VERSION ""

NS_ :

BS_:

BU_: VT TECU TC Sprayer GPS AuxInput

BO_ 2633895166 WSMEM: 8 Vector__XXX
 SG_ ArbitraryAddressCapable : 63|1@1+ (1,0) [0|1] "" Vector__XXX
 SG_ ECUInstance : 32|3@1+ (1,0) [0|7] "" Vector__XXX
 SG_ Function : 40|8@1+ (1,0) [0|255] "" Vector__XXX
 SG_ FunctionInstance : 35|5@1+ (1,0) [0|31] "" Vector__XXX
 SG_ IdentityNumber : 0|21@1+ (1,0) [0|2097152] "" Vector__XXX
 SG_ IndustryGroup M : 60|3@1+ (1,0) [0|7] "" Vector__XXX
 SG_ ManufacturerCode : 21|11@1+ (1,0) [0|2047] "" Vector__XXX
 SG_ VehicleSystem m0 : 49|7@1+ (1,0) [0|127] "" Vector__XXX
 SG_ VehicleSystem1 m1 : 49|7@1+ (1,0) [0|127] "" Vector__XXX
 SG_ VehicleSystem2 m2 : 49|7@1+ (1,0) [0|127] "" Vector__XXX
 SG_ VehicleSystem3 m3 : 49|7@1+ (1,0) [0|127] "" Vector__XXX
 SG_ VehicleSystem4 m4 : 49|7@1+ (1,0) [0|127] "" Vector__XXX
 SG_ VehicleSystem5 m5 : 49|7@1+ (1,0) [0|127] "" Vector__XXX
 SG_ VehicleSystemInstance m0 : 56|4@1+ (1,0) [0|15] "" Vector__XXX

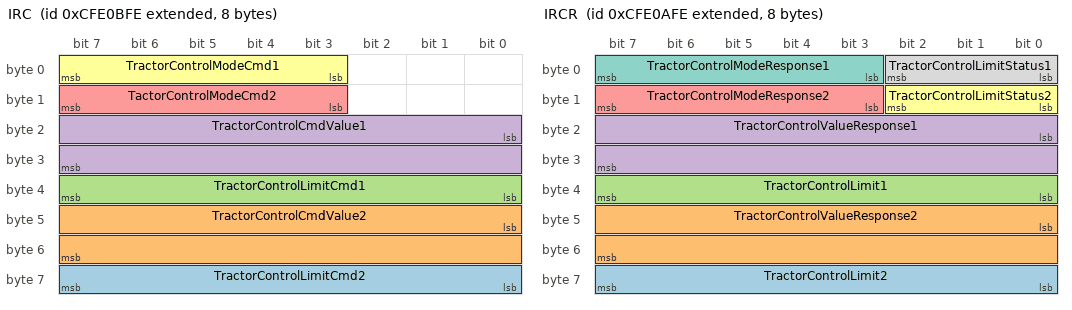
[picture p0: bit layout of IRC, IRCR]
BO_ 2365459454 IRC: 8 Vector__XXX
 SG_ TractorControlLimitCmd2 : 56|8@1- (1,0) [0|0] "" Vector__XXX
 SG_ TractorControlCmdValue2 : 40|16@1+ (1,0) [0|0] "" Vector__XXX
 SG_ TractorControlLimitCmd1 : 32|8@1- (1,0) [0|0] "" Vector__XXX
 SG_ TractorControlCmdValue1 : 16|16@1+ (1,0) [0|0] "" Vector__XXX
 SG_ TactorControlModeCmd2 : 11|5@1+ (1,0) [0|31] "" Vector__XXX
 SG_ TractorControlModeCmd1 : 3|5@1+ (1,0) [0|31] "" Vector__XXX

BO_ 2365459198 IRCR: 8 Vector__XXX
 SG_ TractorControlLimit2 : 56|8@1- (1,0) [0|0] "" Vector__XXX
 SG_ TractorControlValueResponse2 : 40|16@1+ (1,0) [0|0] "" Vector__XXX
 SG_ TractorControlLimit1 : 32|8@1- (1,0) [0|0] "" Vector__XXX
 SG_ TractorControlValueResponse1 : 16|16@1+ (1,0) [0|0] "" Vector__XXX
 SG_ TractorControlModeResponse2 : 11|5@1+ (1,0) [0|31] "" Vector__XXX
 SG_ TractorControlLimitStatus2 : 8|3@1+ (1,0) [0|7] "" Vector__XXX
 SG_ TractorControlModeResponse1 : 3|5@1+ (1,0) [0|31] "" Vector__XXX
 SG_ TractorControlLimitStatus1 : 0|3@1+ (1,0) [0|7] "" Vector__XXX

BO_ 2365458942 TFR: 8 Vector__XXX
 SG_ OperatorExtLightControls : 35|1@1+ (1,0) [0|0] "" Vector__XXX
 SG_ MachineSelectedSpeed : 34|1@1+ (1,0) [0|0] "" Vector__XXX
 SG_ MachineSelectedSpeedControl : 33|1@1+ (1,0) [0|0] "" Vector__XXX
 SG_ DirectionControl : 32|1@1+ (1,0) [0|0] "" Vector__XXX
 SG_ DriveStrategyStatusAndCommands : 48|1@1- (1,0) [0|0] "" Vector__XXX
 SG_ ExtGuidanceStatusAndCmd : 49|1@1- (1,0) [0|0] "" Vector__XXX
 SG_ PTOCmd_FrontPTOModeGearCmd : 55|1@1- (1,0) [0|0] "" Vector__XXX
 SG_ PTOCmd_RearPTOModeGearCmd : 26|1@1- (1,0) [0|0] "" Vector__XXX
 SG_ ReservedBitIndicator : 56|1@1- (1,0) [0|1] "" Vector__XXX
 SG_ HitchInfo_FrontPosition : 47|1@1+ (1,0) [0|1] "" Vector__XXX
 SG_ HitchInfo_FrontInWork : 46|1@1+ (1,0) [0|1] "" Vector__XXX
 SG_ PTOInfo_FrontShaftSpeed : 45|1@1+ (1,0) [0|1] "" Vector__XXX
 SG_ PTOInfo_FrontShaftEngagement : 44|1@1+ (1,0) [0|1] "" Vector__XXX
 SG_ AddHitchParameter__FrontDraft : 43|1@1+ (1,0) [0|1] "" Vector__XXX
 SG_ HitchCmd_FrontHitchPosition : 42|1@1+ (1,0) [0|1] "" Vector__XXX
 SG_ PTOCmd_FrontPTOSpeedCmd : 41|1@1+ (1,0) [0|1] "" Vector__XXX
 SG_ PTOCmd_FrontPTOEngagementCmd : 40|1@1+ (1,0) [0|1] "" Vector__XXX
 SG_ NavigSystemHighOutputPosition : 39|1@1+ (1,0) [0|1] "" Vector__XXX
 SG_ NavigSystemPositionData : 38|1@1+ (1,0) [0|1] "" Vector__XXX
 SG_ NavigPseudorangeNoiseStatistic : 37|1@1+ (1,0) [0|1] "" Vector__XXX
 SG_ HitchCmd_RearHitchPosition : 31|1@1+ (1,0) [0|1] "" Vector__XXX
 SG_ PTOCmd_RearPTOSpeedCmd : 30|1@1+ (1,0) [0|1] "" Vector__XXX
 SG_ PTOCmd_RearPTOEngagementCmd : 29|1@1+ (1,0) [0|1] "" Vector__XXX
 SG_ AuxiliaryValveCmd : 28|1@1+ (1,0) [0|1] "" Vector__XXX
 SG_ LimitStatusReporting : 27|1@1+ (1,0) [0|0] "" Vector__XXX
 SG_ TimeDate : 23|1@1+ (1,0) [0|1] "" Vector__XXX
 SG_ SpeedAndDist_GndBasedDistance : 22|1@1+ (1,0) [0|1] "" Vector__XXX
 SG_ SpeedAndDist_GndBasedDirection : 21|1@1+ (1,0) [0|1] "" Vector__XXX
 SG_ SpeedAndDist_WheelBasedDistance : 20|1@1+ (1,0) [0|1] "" Vector__XXX
 SG_ SpeedAndDist_WheelBasedDirection : 19|1@1+ (1,0) [0|1] "" Vector__XXX
 SG_ AddHitchParameter_RearDraft : 18|1@1+ (1,0) [0|1] "" Vector__XXX
 SG_ Light_FullImplLightingMessageSet : 17|1@1+ (1,0) [0|1] "" Vector__XXX
 SG_ EstimatedOrMeasuredAuxValveState : 16|1@1+ (1,0) [0|1] "" Vector__XXX
 SG_ HitchInfo_RearPosition : 15|1@1+ (1,0) [0|1] "" Vector__XXX
 SG_ HitchInfo_RearInWork : 14|1@1+ (1,0) [0|1] "" Vector__XXX
 SG_ PTOInfo_RearShaftSpeed : 13|1@1+ (1,0) [0|1] "" Vector__XXX
 SG_ PTOInfo_RearShaftEngagement : 12|1@1+ (1,0) [0|0] "" Vector__XXX
 SG_ Lighting_MinimalSet : 11|1@1+ (1,0) [0|1] "" Vector__XXX
 SG_ LanguageCmdStorageInTractorECU : 10|1@1+ (1,0) [0|1] "" Vector__XXX
 SG_ TractorClass : 6|2@1+ (1,0) [0|3] "" Vector__XXX
 SG_ PowerMgt_KeySwitch : 5|1@1+ (1,0) [0|1] "" Vector__XXX
 SG_ PowerMgt_MaxTimeTractorPower : 4|1@1+ (1,0) [0|1] "" Vector__XXX
 SG_ PowerMgt_MaintainPower : 3|1@1+ (1,0) [0|1] "" Vector__XXX
 SG_ SpeedInfo_WheelBasedSpeed : 2|1@1+ (1,0) [0|1] "" Vector__XXX
 SG_ SpeedInfo_GroundBasedSpeed : 1|1@1+ (1,0) [0|1] "" Vector__XXX
 SG_ SpeedInfo_EngineSpeed : 0|1@1+ (1,0) [0|1] "" Vector__XXX

BO_ 2365458686 RTF: 8 Vector__XXX
 SG_ DriveStrategyStatusAndCommands : 48|1@1- (1,0) [0|0] "" Vector__XXX
 SG_ ExtGuidanceStatusAndCmd : 49|1@1- (1,0) [0|0] "" Vector__XXX
 SG_ PTOCmd_FrontPTOModeGearCmd : 55|1@1- (1,0) [0|0] "" Vector__XXX
 SG_ PTOCmd_RearPTOModeGearCmd : 26|1@1- (1,0) [0|0] "" Vector__XXX
 SG_ ReservedBitIndicator : 56|1@1- (1,0) [0|1] "" Vector__XXX
 SG_ HitchInfo_FrontPosition : 47|1@1+ (1,0) [0|1] "" Vector__XXX
 SG_ HitchInfo_FrontInWork : 46|1@1+ (1,0) [0|1] "" Vector__XXX
 SG_ PTOInfo_FrontShaftSpeed : 45|1@1+ (1,0) [0|1] "" Vector__XXX
 SG_ PTOInfo_FrontShaftEngagement : 44|1@1+ (1,0) [0|1] "" Vector__XXX
 SG_ AddHitchParameter__FrontDraft : 43|1@1+ (1,0) [0|1] "" Vector__XXX
 SG_ HitchCmd_FrontHitchPosition : 42|1@1+ (1,0) [0|1] "" Vector__XXX
 SG_ PTOCmd_FrontPTOSpeedCmd : 41|1@1+ (1,0) [0|1] "" Vector__XXX
 SG_ PTOCmd_FrontPTOEngagementCmd : 40|1@1+ (1,0) [0|1] "" Vector__XXX
 SG_ NavigSystemHighOutputPosition : 39|1@1+ (1,0) [0|1] "" Vector__XXX
 SG_ NavigSystemPositionData : 38|1@1+ (1,0) [0|1] "" Vector__XXX
 SG_ NavigPseudorangeNoiseStatistic : 37|1@1+ (1,0) [0|1] "" Vector__XXX
 SG_ OperatorExternalLightControls : 35|1@1+ (1,0) [0|1] "" Vector__XXX
 SG_ SelectedMachineSpeed : 34|1@1+ (1,0) [0|1] "" Vector__XXX
 SG_ SelectedMachineSpeedControl : 33|1@1+ (1,0) [0|1] "" Vector__XXX
 SG_ DirectionControl : 32|1@1+ (1,0) [0|1] "" Vector__XXX
 SG_ HitchCmd_RearHitchPosition : 31|1@1+ (1,0) [0|1] "" Vector__XXX
 SG_ PTOCmd_RearPTOSpeedCmd : 30|1@1+ (1,0) [0|1] "" Vector__XXX
 SG_ PTOCmd_RearPTOEngagementCmd : 29|1@1+ (1,0) [0|1] "" Vector__XXX
 SG_ AuxiliaryValveCmd : 28|1@1+ (1,0) [0|1] "" Vector__XXX
 SG_ LimitStatusReporting : 27|1@1+ (1,0) [0|0] "" Vector__XXX
 SG_ TimeDate : 23|1@1+ (1,0) [0|1] "" Vector__XXX
 SG_ SpeedAndDist_GndBasedDistance : 22|1@1+ (1,0) [0|1] "" Vector__XXX
 SG_ SpeedAndDist_GndBasedDirection : 21|1@1+ (1,0) [0|1] "" Vector__XXX
 SG_ SpeedAndDist_WheelBasedDistance : 20|1@1+ (1,0) [0|1] "" Vector__XXX
 SG_ SpeedAndDist_WheelBasedDirection : 19|1@1+ (1,0) [0|1] "" Vector__XXX
 SG_ AddHitchParameter_RearDraft : 18|1@1+ (1,0) [0|1] "" Vector__XXX
 SG_ Light_FullImplLightingMessageSet : 17|1@1+ (1,0) [0|1] "" Vector__XXX
 SG_ EstimatedOrMeasuredAuxValveState : 16|1@1+ (1,0) [0|1] "" Vector__XXX
 SG_ HitchInfo_RearPosition : 15|1@1+ (1,0) [0|1] "" Vector__XXX
 SG_ HitchInfo_RearInWork : 14|1@1+ (1,0) [0|1] "" Vector__XXX
 SG_ PTOInfo_RearShaftSpeed : 13|1@1+ (1,0) [0|1] "" Vector__XXX
 SG_ PTOInfo_RearShaftEngagement : 12|1@1+ (1,0) [0|0] "" Vector__XXX
 SG_ Lighting_MinimalSet : 11|1@1+ (1,0) [0|1] "" Vector__XXX
 SG_ LanguageCmdStorageInTractorECU : 10|1@1+ (1,0) [0|1] "" Vector__XXX
 SG_ TractorClass : 6|2@1+ (1,0) [0|3] "" Vector__XXX
 SG_ PowerMgt_KeySwitch : 5|1@1+ (1,0) [0|1] "" Vector__XXX
 SG_ PowerMgt_MaxTimeTractorPower : 4|1@1+ (1,0) [0|1] "" Vector__XXX
 SG_ PowerMgt_MaintainPower : 3|1@1+ (1,0) [0|1] "" Vector__XXX
 SG_ SpeedInfo_WheelBasedSpeed : 2|1@1+ (1,0) [0|1] "" Vector__XXX
 SG_ SpeedInfo_GroundBasedSpeed : 1|1@1+ (1,0) [0|1] "" Vector__XXX
 SG_ SpeedInfo_EngineSpeed : 0|1@1+ (1,0) [0|1] "" Vector__XXX

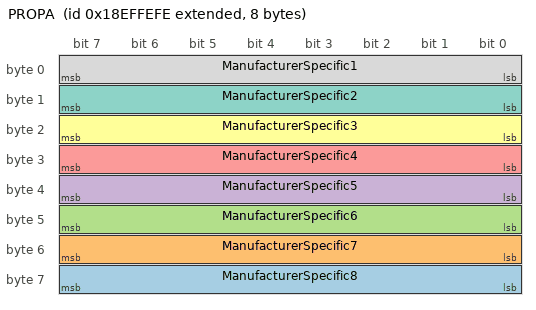
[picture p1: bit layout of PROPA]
BO_ 2565865214 PROPA: 8 Vector__XXX
 SG_ ManufacturerSpecific8 : 56|8@1+ (1,0) [0|255] "" Vector__XXX
 SG_ ManufacturerSpecific7 : 48|8@1+ (1,0) [0|255] "" Vector__XXX
 SG_ ManufacturerSpecific6 : 40|8@1+ (1,0) [0|255] "" Vector__XXX
 SG_ ManufacturerSpecific5 : 32|8@1+ (1,0) [0|255] "" Vector__XXX
 SG_ ManufacturerSpecific4 : 24|8@1+ (1,0) [0|255] "" Vector__XXX
 SG_ ManufacturerSpecific3 : 16|8@1+ (1,0) [0|255] "" Vector__XXX
 SG_ ManufacturerSpecific2 : 8|8@1+ (1,0) [0|255] "" Vector__XXX
 SG_ ManufacturerSpecific1 : 0|8@1+ (1,0) [0|255] "" Vector__XXX

BO_ 2632777470 TPCM: 8 Vector__XXX
 SG_ PGNumber : 40|24@1+ (1,0) [0|16777200] "" Vector__XXX
 SG_ MaximumNumberOfPackets m16 : 32|8@1+ (1,0) [0|255] "" Vector__XXX
 SG_ TotalNumberOfPackets m16 : 24|8@1+ (1,0) [0|255] "" Vector__XXX
 SG_ TotalNumberOfPacketsBAM m32 : 24|8@1+ (1,0) [0|255] "" Vector__XXX
 SG_ TotalNumberOfPacketsEoMA m19 : 24|8@1+ (1,0) [0|255] "" Vector__XXX
 SG_ NextPacketNumberToBeSent m17 : 16|8@1+ (1,0) [0|255] "" Vector__XXX
 SG_ ConnectionAbortReason m255 : 8|8@1+ (1,0) [0|255] "" Vector__XXX
 SG_ NumberOfPacketsThatCanBeSent m17 : 8|8@1+ (1,0) [0|255] "" Vector__XXX
 SG_ TotalMessageSize m16 : 8|16@1+ (1,0) [0|64255] "counts" Vector__XXX
 SG_ TotalMessageSizeBAM m32 : 8|16@1+ (1,0) [0|64255] "counts" Vector__XXX
 SG_ TotalMessageSizeEoMA m19 : 8|16@1+ (1,0) [0|64255] "counts" Vector__XXX
 SG_ ControlByte M : 0|8@1+ (1,0) [0|255] "" Vector__XXX

BO_ 2632711934 TPDT: 8 Vector__XXX
 SG_ SequenceNumber : 0|8@1+ (1,0) [0|255] "" Vector__XXX

BO_ 2565537534 RQST: 3 Vector__XXX
 SG_ ParameterGroupNumber : 0|24@1+ (1,0) [0|16777215] "" Vector__XXX

BO_ 2565406462 ACKM: 8 Vector__XXX
 SG_ ParameterGroupNumber : 40|24@1+ (1,0) [0|16777215] "" Vector__XXX
 SG_ AddressBusy m3 : 32|8@1+ (1,0) [0|255] "" Vector__XXX
 SG_ AddressAccessDenied m2 : 32|8@1+ (1,0) [0|255] "" Vector__XXX
 SG_ AddressNegativeAcknowledgement m1 : 32|8@1+ (1,0) [0|255] "" Vector__XXX
 SG_ AddressAcknowledged m0 : 32|8@1+ (1,0) [0|255] "" Vector__XXX
 SG_ GroupFunctionValue : 8|8@1+ (1,0) [0|255] "" Vector__XXX
 SG_ ControlByte M : 0|8@1+ (1,0) [0|255] "" Vector__XXX

BO_ 2498232062 VT21: 33 Vector__XXX
 SG_ AudioWasTerminated m10 : 8|1@1+ (1,0) [0|0] "" Vector__XXX
 SG_ VTControlAudioSigTerminationTAN m10 : 20|4@1+ (1,0) [0|0] "" Vector__XXX
 SG_ VTSelectInputObjectIsEdited m3 : 32|1@1+ (1,0) [0|1] "" Vector__XXX
 SG_ ParentMaskObjectID m2 : 48|16@1+ (1,0) [0|0] "" Vector__XXX
 SG_ OperatingState4 m38 : 59|1@1+ (1,0) [0|1] "" Vector__XXX
 SG_ OperatingState3 m38 : 58|1@1+ (1,0) [0|1] "" Vector__XXX
 SG_ VTSelectInputObjectResponseTAN m3 : 60|4@1+ (1,0) [0|15] "" Vector__XXX
 SG_ VTOnUserLayoutHideShowRespTAN m9 : 60|4@1+ (1,0) [0|15] "" Vector__XXX
 SG_ VTESCResponseTAN m4 : 60|4@1+ (1,0) [0|15] "" Vector__XXX
 SG_ VTChangeNumericValueResponseTAN m5 : 28|4@1+ (1,0) [0|15] "" Vector__XXX
 SG_ SoftKeyActivationResponseTAN m0 : 60|4@1+ (1,0) [0|15] "" Vector__XXX
 SG_ PointingEventResponseTAN m2 : 44|4@1+ (1,0) [0|15] "" Vector__XXX
 SG_ ButtonActivationResponseTAN m1 : 60|4@1+ (1,0) [0|15] "" Vector__XXX
 SG_ WSVehicleSystemInstance m144 : 64|4@1+ (1,0) [0|15] "" Vector__XXX
 SG_ WSVehicleSystem5 m5 : 57|7@1+ (1,0) [0|127] "" Vector__XXX
 SG_ WSVehicleSystem4 m4 : 57|7@1+ (1,0) [0|127] "" Vector__XXX
 SG_ WSVehicleSystem3 m3 : 57|7@1+ (1,0) [0|127] "" Vector__XXX
 SG_ WSVehicleSystem2 m2 : 57|7@1+ (1,0) [0|127] "" Vector__XXX
 SG_ WSVehicleSystem1 m1 : 57|7@1+ (1,0) [0|127] "" Vector__XXX
 SG_ WSVehicleSystem m0 : 57|7@1+ (1,0) [0|127] "" Vector__XXX
 SG_ WSManufacturerCode m144 : 29|11@1+ (1,0) [0|2047] "" Vector__XXX
 SG_ WSIndustryGroup m144M : 68|3@1+ (1,0) [0|7] "" Vector__XXX
 SG_ WSIdentityNumber m144 : 8|21@1+ (1,0) [0|2097152] "" Vector__XXX
 SG_ WSFunctionInstance m144 : 43|5@1+ (1,0) [0|31] "" Vector__XXX
 SG_ WSFunction m144 : 48|8@1+ (1,0) [0|255] "" Vector__XXX
 SG_ WSECUInstance m144 : 40|3@1+ (1,0) [0|7] "" Vector__XXX
 SG_ WSArbitraryAddressCapable m144 : 71|1@1+ (1,0) [0|1] "" Vector__XXX
 SG_ PathRequested m198 : 16|8@1+ (1,0) [0|255] "" Vector__XXX
 SG_ ItemRequested m198 : 8|8@1+ (1,0) [0|255] "" Vector__XXX
 SG_ Status_3 m35 : 24|8@1+ (1,0) [0|0] "" Vector__XXX
 SG_ UnsupportedVtFunction m253 : 8|8@1+ (1,0) [0|255] "" Vector__XXX
 SG_ AuxiliaryInputID_1 m34 : 120|16@1+ (1,0) [0|65535] "" Vector__XXX
 SG_ AuxiliaryFunctionID_1 m34 : 104|16@1+ (1,0) [0|65535] "" Vector__XXX
 SG_ NumOfPreferredFunctions m34 : 96|8@1- (1,0) [0|255] "" Vector__XXX
 SG_ ModelIdentificationCode m34 : 80|16@1+ (1,0) [0|65535] "" Vector__XXX
 SG_ ArbitraryAddressCapable m34 : 79|1@1+ (1,0) [0|1] "" Vector__XXX
 SG_ IndustryGroup m34 : 76|3@1+ (1,0) [0|7] "" Vector__XXX
 SG_ VehicleSystemInstance m34 : 72|4@1+ (1,0) [0|15] "" Vector__XXX
 SG_ VehicleSystem2 m34 : 65|7@1+ (1,0) [0|127] "" Vector__XXX
 SG_ ZoomValue_PanZoom m16 : 64|32@1- (1,0) [-32|32] "" Vector__XXX
 SG_ OperatingState2 m38 : 57|1@1+ (1,0) [0|1] "" Vector__XXX
 SG_ Function m34 : 56|8@1+ (1,0) [0|255] "" Vector__XXX
 SG_ OperatingState1 m38 : 56|1@1+ (1,0) [0|1] "" Vector__XXX
 SG_ YPosChangeTopLeftLong m180 : 56|16@1- (1,0) [-32768|32767] "" Vector__XXX
 SG_ LineDirection m169 : 56|8@1+ (1,0) [0|1] "" Vector__XXX
 SG_ FunctionInstance m34 : 51|5@1+ (1,0) [0|31] "" Vector__XXX
 SG_ ECUInstance m34 : 48|3@1+ (1,0) [0|7] "" Vector__XXX
 SG_ NewValueY m182 : 48|16@1+ (1,0) [0|65535] "" Vector__XXX
 SG_ GraphicRepresentationObjectID m181 : 48|16@1+ (1,0) [0|255] "" Vector__XXX
 SG_ FontStyle m170 : 48|8@1+ (1,0) [0|255] "" Vector__XXX
 SG_ YPosChangeTopLeft m165 : 48|8@1+ (1,-127) [-127|128] "" Vector__XXX
 SG_ OffTimeDuration_Audio m163 : 48|16@1+ (1,0) [0|65535] "ms" Vector__XXX
 SG_ ButtonKeyCode m1 : 48|8@1+ (1,0) [0|255] "" Vector__XXX
 SG_ SoftKeyCode m0 : 48|8@1+ (1,0) [0|255] "" Vector__XXX
 SG_ Status_2 m9 : 48|8@1+ (1,0) [0|1] "" Vector__XXX
 SG_ NewViewportHeight m17 : 48|16@1+ (1,0) [0|65535] "" Vector__XXX
 SG_ ViewportY_PanZoom m16 : 48|16@1- (1,0) [-32768|32767] "" Vector__XXX
 SG_ ViewportY m14 : 48|16@1- (1,0) [-32768|32767] "" Vector__XXX
 SG_ EllipseHeight m11 : 48|16@1+ (1,0) [0|65535] "" Vector__XXX
 SG_ RectangleHeight_Draw m10 : 48|16@1+ (1,0) [0|65535] "" Vector__XXX
 SG_ EndPixelOffsetY m9 : 48|16@1- (1,0) [-32768|32767] "" Vector__XXX
 SG_ PixelOffsetY m8 : 48|16@1- (1,0) [-32768|32767] "" Vector__XXX
 SG_ CursorOffsetY m1 : 48|16@1- (1,0) [-32768|32767] "" Vector__XXX
 SG_ CursorPosY m0 : 48|16@1- (1,0) [-32768|32767] "" Vector__XXX
 SG_ NewStringValue m179 : 24|16@1+ (1,0) [0|65535] "" Vector__XXX
 SG_ Value2 m38 : 40|16@1+ (1,0) [0|65535] "" Vector__XXX
 SG_ NewHeigthAttribute m183 : 40|16@1+ (1,0) [0|0] "" Vector__XXX
 SG_ FontType m170 : 40|8@1+ (1,0) [0|255] "" Vector__XXX
 SG_ XPosChangeTopLeftLong m180 : 40|16@1- (1,0) [-32768|32767] "" Vector__XXX
 SG_ FillPatternObjectID m172 : 40|16@1+ (1,0) [0|65535] "" Vector__XXX
 SG_ LineArt m171 : 40|16@1+ (1,0) [0|65535] "" Vector__XXX
 SG_ LabelFontType m181 : 40|8@1+ (1,0) [0|255] "" Vector__XXX
 SG_ Height m169 : 40|16@1+ (1,0) [0|65535] "" Vector__XXX
 SG_ NewHeight m166 : 40|16@1+ (1,0) [0|65535] "" Vector__XXX
 SG_ XPosChangeTopLeft m165 : 40|8@1+ (1,-127) [-127|128] "" Vector__XXX
 SG_ TouchState m2 : 40|4@1+ (1,0) [0|255] "" Vector__XXX
 SG_ TextLength m13 : 40|8@1+ (1,0) [0|255] "bytes" Vector__XXX
 SG_ ManufacturerCode m34 : 37|11@1+ (1,0) [0|2047] "" Vector__XXX
 SG_ AuxErrorAnyOther m37 : 33|1@1+ (1,0) [0|1] "" Vector__XXX
 SG_ CursorPosX m0 : 32|16@1- (1,0) [-32768|32767] "" Vector__XXX
 SG_ CursorOffsetX m1 : 32|16@1- (1,0) [-32768|32767] "" Vector__XXX
 SG_ ForegroundColour m2 : 32|8@1+ (1,0) [0|255] "" Vector__XXX
 SG_ BackgroundColour m3 : 32|8@1+ (1,0) [0|255] "" Vector__XXX
 SG_ LineAttributesObjectID m4 : 32|16@1+ (1,0) [0|65535] "" Vector__XXX
 SG_ FillAttributesObjectID m5 : 32|16@1+ (1,0) [0|65535] "" Vector__XXX
 SG_ FontAttributesObjectID m6 : 32|16@1+ (1,0) [0|65535] "" Vector__XXX
 SG_ RectangleWidth_Erase m7 : 32|16@1+ (1,0) [0|65535] "" Vector__XXX
 SG_ RectangleHeight_Erase m7 : 48|16@1+ (1,0) [0|65535] "" Vector__XXX
 SG_ PixelOffsetX m8 : 32|16@1- (1,0) [-32768|32767] "" Vector__XXX
 SG_ EndPixelOffsetX m9 : 32|16@1- (1,0) [-32768|32767] "" Vector__XXX
 SG_ RectangleWidth_Draw m10 : 32|16@1+ (1,0) [0|65535] "" Vector__XXX
 SG_ EllipseWidth m11 : 32|16@1+ (1,0) [0|65535] "" Vector__XXX
 SG_ NumberOfPoints m12 : 32|8@1+ (1,0) [0|255] "" Vector__XXX
 SG_ TextOption m13 : 32|8@1+ (1,0) [0|1] "" Vector__XXX
 SG_ ViewportX m14 : 32|16@1- (1,0) [-32768|32767] "" Vector__XXX
 SG_ ZoomValue m15 : 32|32@1- (1,0) [-32|32] "" Vector__XXX
 SG_ ViewportX_PanZoom m16 : 32|16@1- (1,0) [-32768|32767] "" Vector__XXX
 SG_ NewViewportWidth m17 : 32|16@1+ (1,0) [0|65535] "" Vector__XXX
 SG_ ObjectID m18 : 32|16@1+ (1,0) [0|65534] "" Vector__XXX
 SG_ PictureGraphicsID_Canvas m19 : 32|16@1+ (1,0) [0|65534] "" Vector__XXX
 SG_ PictureGraphicsID_Viewport m20 : 32|16@1+ (1,0) [0|65534] "" Vector__XXX
 SG_ LastWideChar m193 : 32|16@1+ (1,0) [0|65535] "" Vector__XXX
 SG_ LockTimeout m189 : 32|16@1+ (1,0) [0|65535] "" Vector__XXX
 SG_ NewValueX m182 : 32|16@1+ (1,0) [0|65535] "" Vector__XXX
 SG_ NewObjectID m177 : 32|16@1+ (1,0) [0|65535] "" Vector__XXX
 SG_ NewAttributeValue m175 : 32|32@1+ (1,0) [0|0] "" Vector__XXX
 SG_ NewSoftKeyMaskObjectID m174 : 32|16@1+ (1,0) [0|65535] "" Vector__XXX
 SG_ FillColour m172 : 32|8@1+ (1,0) [0|255] "" Vector__XXX
 SG_ LineWidth m171 : 32|8@1+ (1,0) [0|255] "" Vector__XXX
 SG_ FontSize m170 : 32|8@1+ (1,0) [0|255] "" Vector__XXX
 SG_ NewValue m168 : 32|32@1+ (1,0) [0|65535] "" Vector__XXX
 SG_ OnTimeDuration_Audio m163 : 32|16@1+ (1,0) [0|65535] "ms" Vector__XXX
 SG_ AuxErrorInvalidInputID m37 : 32|1@1+ (1,0) [0|1] "" Vector__XXX
 SG_ VTChangeNumericValueValue m5 : 32|32@1+ (1,0) [0|4294967295] "" Vector__XXX
 SG_ ButtonObjectParentID m1 : 32|16@1+ (1,0) [0|65535] "" Vector__XXX
 SG_ KeyObjectParentID m0 : 32|16@1+ (1,0) [0|65535] "" Vector__XXX
 SG_ ObjectId_2 m9 : 32|16@1+ (1,0) [0|65535] "" Vector__XXX
 SG_ Value1 m38 : 24|16@1+ (1,0) [0|65535] "" Vector__XXX
 SG_ AttributeIDToChange m175 : 24|8@1+ (1,0) [0|0] "" Vector__XXX
 SG_ SubCommandID m184M : 24|8@1+ (1,0) [0|0] "" Vector__XXX
 SG_ NewWidthAttribute m183 : 24|16@1+ (1,0) [0|65535] "" Vector__XXX
 SG_ IndexOfThePointToReplace m182 : 24|8@1+ (1,0) [0|255] "" Vector__XXX
 SG_ StringVariableObjectID m181 : 24|16@1+ (1,0) [0|65535] "" Vector__XXX
 SG_ ChangeChildLocationObjectID m165 : 24|16@1+ (1,0) [0|65535] "" Vector__XXX
 SG_ ListIndex m177 : 24|8@1+ (1,0) [0|255] "" Vector__XXX
 SG_ NewPriority m176 : 24|8@1+ (1,0) [0|255] "" Vector__XXX
 SG_ AttributeID m185 : 24|8@1+ (1,0) [0|16777200] "" Vector__XXX
 SG_ NewActiveMaskObjectID m173 : 24|16@1+ (1,0) [0|65535] "" Vector__XXX
 SG_ FillType m172 : 24|8@1+ (1,0) [0|255] "" Vector__XXX
 SG_ LineColour m171 : 24|8@1+ (1,0) [0|255] "" Vector__XXX
 SG_ FontColour m170 : 24|8@1+ (1,0) [0|255] "" Vector__XXX
 SG_ Width m169 : 24|16@1+ (1,0) [0|65535] "" Vector__XXX
 SG_ NewBackgroundColour m167 : 24|8@1+ (1,0) [0|255] "" Vector__XXX
 SG_ NewWidth m166 : 24|16@1+ (1,0) [0|65535] "" Vector__XXX
 SG_ ChangeChildPositionObjectID m180 : 24|16@1+ (1,0) [0|65535] "" Vector__XXX
 SG_ SetFocusOpenForEditing m162 : 24|8@1+ (1,0) [0|255] "" Vector__XXX
 SG_ EnableOrDisable m161 : 24|8@1+ (1,0) [0|1] "" Vector__XXX
 SG_ ShowOrHide m160 : 24|8@1+ (1,0) [0|1] "" Vector__XXX
 SG_ AuxInputEnable m37 : 24|8@1+ (1,0) [0|1] "" Vector__XXX
 SG_ AssignmentErrorNotAccepted m36 : 24|1@1+ (1,0) [0|1] "" Vector__XXX
 SG_ ObjectOfChangedStringValueID m8 : 24|16@1+ (1,0) [0|65535] "" Vector__XXX
 SG_ VTChangeSoftKeyMaskObjectID m7 : 24|16@1+ (1,0) [0|65535] "" Vector__XXX
 SG_ VTSelectInputObjectStatus m3 : 24|8@1+ (1,0) [0|1] "" Vector__XXX
 SG_ YPosition m2 : 24|16@1+ (1,0) [0|65535] "" Vector__XXX
 SG_ AuxiliaryFunctionID m32 : 24|16@1+ (1,0) [0|65535] "" Vector__XXX
 SG_ Status_1 m9 : 24|8@1+ (1,0) [0|1] "" Vector__XXX
 SG_ IdentityNumber m34 : 16|21@1+ (1,0) [0|2097152] "" Vector__XXX
 SG_ FirstWideChar m193 : 16|16@1+ (1,0) [0|65535] "" Vector__XXX
 SG_ MemoryRequired m192 : 16|32@1+ (1,0) [0|4294967295] "" Vector__XXX
 SG_ ObjectIDOfDataMaskToLock m189 : 16|16@1+ (1,0) [0|65535] "" Vector__XXX
 SG_ DataOrAlarmMaskObjectID m174 : 16|16@1+ (1,0) [0|65535] "" Vector__XXX
 SG_ Frequency_Audio m163 : 16|16@1+ (1,0) [0|65535] "hz" Vector__XXX
 SG_ ButtonObjectID m1 : 16|16@1+ (1,0) [0|65535] "" Vector__XXX
 SG_ KeyObjectID m0 : 16|16@1+ (1,0) [0|65535] "" Vector__XXX
 SG_ WSMaintenanceVersion m255M : 16|8@1+ (1,0) [0|255] "" Vector__XXX
 SG_ AuxiliaryInputNumber m32 : 16|8@1+ (1,0) [0|255] "" Vector__XXX
 SG_ ExtendedVersionLabelToDelete m214 : 8|256@1+ (1,0) [0|3338120000] "" Vector__XXX
 SG_ ExtendedVersionLabelToLoad m213 : 8|256@1+ (1,0) [0|3338120000] "" Vector__XXX
 SG_ ExtendedVersionLabelToStore m212 : 8|256@1+ (1,0) [0|3338120000] "" Vector__XXX
 SG_ MacroObjectID_2 m188 : 8|16@1+ (1,0) [0|65535] "" Vector__XXX
 SG_ AuxCapabilitiesRequestType m39 : 8|8@1+ (1,0) [0|255] "" Vector__XXX
 SG_ WSMaintenanceInitiating m3 : 8|1@1+ (1,0) [0|1] "" Vector__XXX
 SG_ VersionLabelToDelete m210 : 8|56@1+ (1,0) [0|3338120000] "" Vector__XXX
 SG_ VersionLabelToLoad m209 : 8|56@1+ (1,0) [0|3338120000] "" Vector__XXX
 SG_ VersionLabelToStore m208 : 8|56@1+ (1,0) [0|3338120000] "" Vector__XXX
 SG_ CodePlane m193 : 8|8@1+ (1,0) [0|16] "" Vector__XXX
 SG_ MacroObjectID m190 : 8|8@1+ (1,0) [0|255] "" Vector__XXX
 SG_ LockUnlockCommand m189 : 8|8@1+ (1,0) [0|1] "" Vector__XXX
 SG_ ColourMapObjectID m186 : 8|16@1+ (1,0) [0|65535] "" Vector__XXX
 SG_ ObjectToGetAttributeID m185 : 8|16@1+ (1,0) [0|65535] "" Vector__XXX
 SG_ GraphicsContextObjectID m184 : 8|16@1+ (1,0) [0|65535] "" Vector__XXX
 SG_ PolygonObjectToScaleID m183 : 8|16@1+ (1,0) [0|65535] "" Vector__XXX
 SG_ PolygonObjectToChangeID m182 : 8|16@1+ (1,0) [0|65535] "" Vector__XXX
 SG_ ObjectToAssociateLabelWithID m181 : 8|16@1+ (1,0) [0|65535] "" Vector__XXX
 SG_ ObjectToChangeStringValueID m179 : 8|16@1+ (1,0) [0|65535] "" Vector__XXX
 SG_ ListInputObjectID m177 : 8|16@1+ (1,0) [0|65535] "" Vector__XXX
 SG_ AlarmMaskObjectID m176 : 8|16@1+ (1,0) [0|65535] "" Vector__XXX
 SG_ ObjectToChangeAttributeID m175 : 8|16@1+ (1,0) [0|65535] "" Vector__XXX
 SG_ MaskType m174 : 8|8@1+ (1,0) [0|255] "" Vector__XXX
 SG_ WorkingSetObjectID m173 : 8|16@1+ (1,0) [0|65535] "" Vector__XXX
 SG_ ObjectToChangeFillAttributesID m172 : 8|16@1+ (1,0) [0|65535] "" Vector__XXX
 SG_ ObjectToChangeLineAttributesID m171 : 8|16@1+ (1,0) [0|65535] "" Vector__XXX
 SG_ ObjectToChangeFontID m170 : 8|16@1+ (1,0) [0|65535] "" Vector__XXX
 SG_ ObjectToChangeEndPointID m169 : 8|16@1+ (1,0) [0|65535] "" Vector__XXX
 SG_ ObjectToChangeNumValueID m168 : 8|16@1+ (1,0) [0|65535] "" Vector__XXX
 SG_ ObjectToChangeColourID m167 : 8|16@1+ (1,0) [0|65535] "" Vector__XXX
 SG_ ObjectToSizeID m166 : 8|16@1+ (1,0) [0|65535] "" Vector__XXX
 SG_ ChangeChildLocationParentOb_0003 m165 : 8|16@1+ (1,0) [0|65535] "" Vector__XXX
 SG_ AudioVolume m164 : 8|8@1+ (1,0) [0|100] "%" Vector__XXX
 SG_ NumberOfRepetitions_Audio m163 : 8|8@1+ (1,0) [0|255] "" Vector__XXX
 SG_ SelectInputObjectID m162 : 8|16@1+ (1,0) [0|65535] "" Vector__XXX
 SG_ ObjectoEnableDisbaleID m161 : 8|16@1+ (1,0) [0|65535] "" Vector__XXX
 SG_ ObjectToShowHideID m160 : 8|16@1+ (1,0) [0|65535] "" Vector__XXX
 SG_ InputStatusObjectId m37 : 8|16@1+ (1,0) [0|255] "" Vector__XXX
 SG_ AuxModelIdentification m35 : 8|16@1+ (1,0) [0|65535] "" Vector__XXX
 SG_ NumberOfInpuUnits m34 : 8|8@1+ (1,0) [0|255] "" Vector__XXX
 SG_ AuxiliaryFunctionObjectID m36 : 8|16@1+ (1,0) [0|65535] "" Vector__XXX
 SG_ ObjectPoolRecord m17 : 8|56@1+ (1,0) [0|3338120000] "" Vector__XXX
 SG_ ChangeChildPositionParentOb_0003 m180 : 8|16@1+ (1,0) [0|65535] "" Vector__XXX
 SG_ VTChangeSoftKeyMaskParentID m7 : 8|16@1+ (1,0) [0|65535] "" Vector__XXX
 SG_ VTChangeActiveMaskObjectID m6 : 8|16@1+ (1,0) [0|65535] "" Vector__XXX
 SG_ VTChangeNumericValueObjectID m5 : 8|16@1+ (1,0) [0|65535] "" Vector__XXX
 SG_ VTEscObjectID m4 : 8|16@1+ (1,0) [0|65535] "" Vector__XXX
 SG_ VTSelectInputObjectID m3 : 8|16@1+ (1,0) [0|65535] "" Vector__XXX
 SG_ XPosition m2 : 8|16@1+ (1,0) [0|65535] "" Vector__XXX
 SG_ ButtonActivationCode m1 : 8|8@1+ (1,0) [0|2] "" Vector__XXX
 SG_ KeyActivationCode m0 : 8|8@1+ (1,0) [0|2] "" Vector__XXX
 SG_ InputObjectId m38 : 8|16@1+ (1,0) [0|255] "" Vector__XXX
 SG_ SourceAddressOfAuxiliaryInputDev m32 : 8|8@1+ (1,0) [0|255] "" Vector__XXX
 SG_ ObjectId_1 m9 : 8|16@1+ (1,0) [0|65535] "" Vector__XXX
 SG_ VTFunctionECUtoVT M : 0|8@1+ (1,0) [0|255] "" Vector__XXX

CM_ BO_ 2633895166 "Working Set Member";
CM_ BO_ 2365459454 "Tractor control mode command (previously: Implement remote control command)";
CM_ BO_ 2365459198 "Tractor control command tractor response (previoulsy: Implement remote control command Tractor response)";
CM_ SG_ 2365459198 TractorControlLimitStatus2 "Parameter used to report the tractor ECUs present limit status associated with a parameter whose commands are persistent";
CM_ SG_ 2365459198 TractorControlLimitStatus1 "Parameter used to report the tractor ECUs present limit status associated with a parameter whose commands are persistent";
CM_ BO_ 2365458942 "Tractor Facilities response message";
CM_ SG_ 2365458942 LimitStatusReporting "Parameter used to respond to a request of a facility of a tractor ECU";
CM_ BO_ 2365458686 "Required Tractor Facilities message";
CM_ SG_ 2365458686 OperatorExternalLightControls "Parameter used to respond to a request of a facility of a tractor ECU";
CM_ SG_ 2365458686 SelectedMachineSpeed "Parameter used to respond to a request of a facility of a tractor ECU";
CM_ SG_ 2365458686 SelectedMachineSpeedControl "Parameter used to respond to a request of a facility of a tractor ECU";
CM_ SG_ 2365458686 DirectionControl "Parameter used to respond to a request of a facility of a tractor ECU";
CM_ SG_ 2365458686 LimitStatusReporting "Parameter used to respond to a request of a facility of a tractor ECU";
CM_ BO_ 2565865214 "Proprietary A";
CM_ BO_ 2632777470 "Transport Protocol - Connection Management";
CM_ SG_ 2632777470 MaximumNumberOfPackets "Maximum number of packets for RTS/CTS message.";
CM_ SG_ 2632777470 NextPacketNumberToBeSent "Next Packet Number to be sent (TP.CM_CTS)";
CM_ SG_ 2632777470 ConnectionAbortReason "Reason for connection abort message.";
CM_ SG_ 2632777470 NumberOfPacketsThatCanBeSent "Number of Packets that can be sent (TP.CM_CTS)";
CM_ BO_ 2632711934 "Transport Protocol - Data Transfer";
CM_ BO_ 2565537534 "Request";
CM_ SG_ 2565537534 ParameterGroupNumber "PGN which is requested by the Request message";
CM_ BO_ 2565406462 "Acknowledgment Message";
CM_ SG_ 2565406462 ParameterGroupNumber "PGN which is requested by the Request message";
CM_ BO_ 2498232062 "ECU to VT";
CM_ SG_ 2498232062 AuxErrorAnyOther "Any other error";
CM_ SG_ 2498232062 AuxErrorInvalidInputID "Invalid Auxiliary Input Object ID";
CM_ SG_ 2498232062 AuxInputEnable "Auxiliary Input Enable";
CM_ SG_ 2498232062 ObjectOfChangedStringValueID "Object ID of the Input String or String Variable ";
CM_ SG_ 2498232062 AuxModelIdentification "Model Identification Code of the Auxiliary Input Unit";
BA_DEF_ SG_  "DDI" INT 0 65535;
BA_DEF_ BO_  "SingleFrame" INT 0 1;
BA_DEF_ BO_  "VFrameFormat" ENUM  "StandardCAN","ExtendedCAN","reserved","J1939PG","vector_leerstring";
BA_DEF_ BO_  "GenMsgSendType" ENUM  "cyclic","NotUsed","IfActive","NotUsed","NotUsed","NotUsed","NotUsed","NotUsed","noMsgSendType","vector_leerstring";
BA_DEF_ BO_  "GenMsgCycleTime" INT 0 3600000;
BA_DEF_ BO_  "GenMsgRequestable" INT 0 1;
BA_DEF_ BO_  "GenMsgNrOfRepetition" INT 0 1000000;
BA_DEF_ BO_  "GenMsgCycleTimeFast" INT 0 3600000;
BA_DEF_ BO_  "GenMsgFastOnStart" INT 0 100000;
BA_DEF_ SG_  "SPN" INT 0 524287;
BA_DEF_ SG_  "GenSigSendType" ENUM  "Cyclic","OnWrite","OnWriteWithRepetition","OnChange","OnChangeWithRepetition","IfActive","IfActiveWithRepetition","NoSigSendType";
BA_DEF_ SG_  "SigType" ENUM  "Default","Range","RangeSigned","ASCII","Discrete","Control","ReferencePGN","DTC","StringDelimiter","StringLength","StringLengthControl","MessageCounter","MessageChecksum";
BA_DEF_ SG_  "GenSigStartValue" INT -2147483648 2147483647;
BA_DEF_ SG_  "SystemSignalLongSymbol" STRING ;
BA_DEF_DEF_  "DDI" 0;
BA_DEF_DEF_  "SingleFrame" 1;
BA_DEF_DEF_  "VFrameFormat" "J1939PG";
BA_DEF_DEF_  "GenMsgSendType" "noMsgSendType";
BA_DEF_DEF_  "GenMsgCycleTime" 0;
BA_DEF_DEF_  "GenMsgRequestable" 1;
BA_DEF_DEF_  "GenMsgNrOfRepetition" 0;
BA_DEF_DEF_  "GenMsgCycleTimeFast" 0;
BA_DEF_DEF_  "GenMsgFastOnStart" 0;
BA_DEF_DEF_  "SPN" 0;
BA_DEF_DEF_  "GenSigSendType" "NoSigSendType";
BA_DEF_DEF_  "SigType" "Default";
BA_DEF_DEF_  "GenSigStartValue" 0;
BA_DEF_DEF_  "SystemSignalLongSymbol" "";
BA_ "GenMsgCycleTime" BO_ 2365459454 100;
BA_ "GenMsgSendType" BO_ 2365459454 8.61276577466361E-317;
BA_ "GenMsgCycleTime" BO_ 2365459198 100;
BA_ "GenMsgCycleTime" BO_ 2365458942 100;
BA_ "GenMsgCycleTime" BO_ 2365458686 100;
BA_ "GenMsgCycleTime" BO_ 2565865214 100;
BA_ "GenMsgSendType" BO_ 2565865214 8.63482481761913E-317;
BA_ "GenMsgCycleTime" BO_ 2498232062 1000;
BA_ "GenMsgSendType" BO_ 2498232062 2;
BA_ "SPN" SG_ 2633895166 ArbitraryAddressCapable 2844;
BA_ "SPN" SG_ 2633895166 ECUInstance 2840;
BA_ "SPN" SG_ 2633895166 Function 2841;
BA_ "SPN" SG_ 2633895166 FunctionInstance 2839;
BA_ "SPN" SG_ 2633895166 IdentityNumber 2837;
BA_ "SPN" SG_ 2633895166 IndustryGroup 2846;
BA_ "SPN" SG_ 2633895166 ManufacturerCode 2838;
BA_ "SigType" SG_ 2633895166 ManufacturerCode 1;
BA_ "SPN" SG_ 2633895166 VehicleSystemInstance 2843;
BA_ "SigType" SG_ 2365459454 TractorControlCmdValue2 1;
BA_ "SigType" SG_ 2365459454 TractorControlCmdValue1 1;
BA_ "SPN" SG_ 2365459454 TractorControlModeCmd1 5204;
BA_ "SigType" SG_ 2365459198 TractorControlValueResponse2 1;
BA_ "SigType" SG_ 2365459198 TractorControlValueResponse1 1;
BA_ "SPN" SG_ 2365459198 TractorControlModeResponse1 5213;
BA_ "SPN" SG_ 2365459198 TractorControlLimitStatus1 5227;
BA_ "SPN" SG_ 2365458942 ReservedBitIndicator 5236;
BA_ "SPN" SG_ 2365458942 TractorClass 5234;
BA_ "SigType" SG_ 2365458942 TractorClass 4;
BA_ "SPN" SG_ 2365458942 SpeedInfo_EngineSpeed 5235;
BA_ "SPN" SG_ 2365458686 TractorClass 5232;
BA_ "SigType" SG_ 2365458686 TractorClass 4;
BA_ "SPN" SG_ 2365458686 SpeedInfo_EngineSpeed 5233;
BA_ "SigType" SG_ 2565865214 ManufacturerSpecific8 1;
BA_ "SigType" SG_ 2565865214 ManufacturerSpecific7 1;
BA_ "SigType" SG_ 2565865214 ManufacturerSpecific6 1;
BA_ "SigType" SG_ 2565865214 ManufacturerSpecific5 1;
BA_ "SigType" SG_ 2565865214 ManufacturerSpecific4 1;
BA_ "SigType" SG_ 2565865214 ManufacturerSpecific3 1;
BA_ "SigType" SG_ 2565865214 ManufacturerSpecific2 1;
BA_ "SigType" SG_ 2565865214 ManufacturerSpecific1 1;
BA_ "SPN" SG_ 2632777470 PGNumber 2560;
BA_ "SigType" SG_ 2632777470 PGNumber 6;
BA_ "SPN" SG_ 2632777470 MaximumNumberOfPackets 2559;
BA_ "SPN" SG_ 2632777470 TotalNumberOfPackets 2558;
BA_ "SPN" SG_ 2632777470 NextPacketNumberToBeSent 2562;
BA_ "SPN" SG_ 2632777470 ConnectionAbortReason 2570;
BA_ "SPN" SG_ 2632777470 NumberOfPacketsThatCanBeSent 2561;
BA_ "SPN" SG_ 2632777470 ControlByte 2556;
BA_ "SPN" SG_ 2632711934 SequenceNumber 2572;
BA_ "SPN" SG_ 2565537534 ParameterGroupNumber 2574;
BA_ "SigType" SG_ 2565537534 ParameterGroupNumber 6;
BA_ "SPN" SG_ 2565406462 ParameterGroupNumber 2574;
BA_ "SigType" SG_ 2565406462 ParameterGroupNumber 6;
BA_ "SigType" SG_ 2565406462 GroupFunctionValue 1;
BA_ "SPN" SG_ 2565406462 GroupFunctionValue 2542;
BA_ "SPN" SG_ 2565406462 ControlByte 2541;
BA_ "SPN" SG_ 2498232062 WSIdentityNumber 2837;
BA_ "SPN" SG_ 2498232062 ArbitraryAddressCapable 2844;
BA_ "SPN" SG_ 2498232062 IndustryGroup 2846;
BA_ "SPN" SG_ 2498232062 VehicleSystemInstance 2843;
BA_ "SPN" SG_ 2498232062 Function 2841;
BA_ "SPN" SG_ 2498232062 FunctionInstance 2839;
BA_ "SPN" SG_ 2498232062 ECUInstance 2840;
BA_ "SigType" SG_ 2498232062 NewStringValue 9;
BA_ "SPN" SG_ 2498232062 ManufacturerCode 2838;
BA_ "SigType" SG_ 2498232062 ManufacturerCode 1;
BA_ "SPN" SG_ 2498232062 IdentityNumber 2837;
BA_ "SigType" SG_ 2498232062 ExtendedVersionLabelToDelete 3;
BA_ "SigType" SG_ 2498232062 ExtendedVersionLabelToLoad 3;
BA_ "SigType" SG_ 2498232062 ExtendedVersionLabelToStore 3;
BA_ "SigType" SG_ 2498232062 VersionLabelToDelete 3;
BA_ "SigType" SG_ 2498232062 VersionLabelToLoad 3;
BA_ "SigType" SG_ 2498232062 VersionLabelToStore 3;
BA_ "SystemSignalLongSymbol" SG_ 2498232062 ChangeChildLocationParentOb_0003 "ChangeChildLocationParentObjectID";
BA_ "SystemSignalLongSymbol" SG_ 2498232062 ChangeChildPositionParentOb_0003 "ChangeChildPositionParentObjectID";
VAL_ 2633895166 Function 43 "Transmission Display" 44 "Exhaust Emission Control" 45 "Vehicle Dynamic Stability Control" 46 "Oil Sensor Unit" 47 "Information System Controller" 48 "Ramp Control" 49 "Clutch/Converter Control" 50 "Auxiliary Heater" 51 "Forward-Looking Collision Warning System" 52 "Chassis Controller" 53 "Alternator/Charging System" 54 "Communications Unit, Cellular" 55 "Communications Unit, Satellite" 56 "Communications Unit, Radio" 57 "Steering Column Unit" 58 "Fan Drive Control" 59 "Starter" 60 "Cab Display" 61 "File Server/Printer" 62 "On-Board Diagnostic Unit" 63 "Engine Valve Controller" 64 "Endurance Braking" 65 "Gas Flow Measurement" 66 "I/O Controller" 67 "Electrical System Controller" 68 "Aftertreatment system gas measurement" 69 "Engine Emission Aftertreatement System" 70 "Auxiliary Regeneration Device" 71 "Transfer Case Control" 72 "Coolant Valve Controller" 73 "Rollover Detection Control" 74 "Lubrication System" 75 "Supplemental Fan" 76 "Temperature Sensor" 77 "Fuel Properties Sensor" 78 "Fire Suppression System" 79 "Power Systems Manager" 80 "Electric Powertrain" 81 "Hydraulic Powertrain" 82 "File Server" 83 "Printer" 84 "Start Aid Device" 85 "Engine Injection Control Module" 86 "Reserved" 87 "Reserved" 88 "Reserved" 89 "Reserved" 90 "Reserved" 91 "Reserved" 92 "Reserved" 93 "Reserved" 94 "Reserved" 95 "Reserved" 96 "Reserved" 97 "Reserved" 98 "Reserved" 99 "Reserved" 100 "Reserved" 0 "Engine" 1 "Auxiliary Power Unit (APU)" 2 "Electric Propulsion Control" 3 "Transmission" 4 "Battery Pack Monitor" 5 "Shift Control/Console" 6 "Power TakeOff - (Main or Rear)" 7 "Axle - Steering" 8 "Axle - Drive" 9 "Brakes - System Controller" 10 "Brakes - Steer Axle" 11 "Brakes - Drive Axle" 12 "Retarder - Engine" 13 "Retarder - Driveline" 14 "Cruise Control" 15 "Fuel System" 16 "Steering Controller" 17 "Suspension - Steer Axle" 18 "Suspension - Drive Axle" 19 "Instrument Cluster" 20 "Trip Recorder" 21 "Cab Climate Control" 22 "Aerodynamic Control" 23 "Vehicle Navigation" 24 "Vehicle Security" 25 "Network Interconnect ECU" 26 "Body Controller" 27 "Power TakeOff (Secondary or Front)" 28 "Off Vehicle Gateway" 29 "Virtual Terminal (in cab)" 30 "Management Computer" 31 "Propulsion Battery Charger" 32 "Headway Controller" 33 "System Monitor" 34 "Hydraulic Pump Controller" 35 "Suspension - System Controller" 36 "Pneumatic - System Controller" 37 "Cab Controller" 38 "Tire Pressure Control" 39 "Ignition Control Module" 40 "Seat Control" 41 "Lighting - Operator Controls" 42 "Water Pump Control" 101 "Reserved" 102 "Reserved" 103 "Reserved" 104 "Reserved" 105 "Reserved" 106 "Reserved" 107 "Reserved" 108 "Reserved" 109 "Reserved" 110 "Reserved" 111 "Reserved" 112 "Reserved" 113 "Reserved" 114 "Reserved" 115 "Reserved" 116 "Reserved" 117 "Reserved" 118 "Reserved" 119 "Reserved" 120 "Reserved" 121 "Reserved" 122 "Reserved" 123 "Reserved" 124 "Reserved" 125 "Reserved" 126 "Reserved" 127 "Reserved" 255 "Not Available" ;
VAL_ 2633895166 IndustryGroup 7 "Reserved for SAE" 5 "IndustrialProcessCtrlStationary" 4 "Marine" 3 "Construction" 2 "AgriculturalAndForestry" 1 "On-Highway" 0 "Global" 6 "Reserved for SAE" ;
VAL_ 2633895166 ManufacturerCode 1077 "Ymer Technology" 1076 "DOGA S.A." 1075 "Uniden America Corporation" 1074 "Kindhelm / Navigs Oy" 1073 "Manitou Equipment America LLC" 1072 "La Marche Manufacturing Company" 1071 "MACH SYSTEMS s.r.o." 1070 "Quick-teck Electronics Ltd" 1069 "Lithionics Battery LLC" 1068 "Zapi S.p.A." 1067 "Tecomec S.r.l." 1066 "Spot Zero Water" 1065 "CALYPSO Instruments" 1064 "Omnitech Robotics Inc." 1063 "SolSteer" 1062 "Marol Co Ltd" 1061 "Volvo Construction Equipment" 1060 "Scale-Tec" 1059 "Boatrax" 1058 "Bondioli & Pavesi SpA" 1057 "EquipmentShare" 1056 "Lithium Pros" 1055 "EXA Computing GmbH" 1054 "Schmotzer Hacktechnik GmbH & Co. KG" 1053 "Vetus Maxwell, Inc." 1052 "Pfreundt" 1051 "ProNav AS" 1050 "Spacenus GmbH" 1049 "S&S Cycle" 1048 "Agrivation UG" 1047 "Sonic Corporation" 1046 "Praxidyn" 1045 "CMR Group" 1044 "Xee" 1043 "Hyva" 1042 "engcon group" 1041 "EZ Lynk" 1040 "BPE Electronics Srl" 1039 "Liugong Dressta Machinery" 1038 "EMIT Technologies, Inc." 1037 "Dragonfly Energy Corp." 1036 "Bender GmbH & Co. KG" 1035 "Agres" 1034 "Siren Marine" 1033 "ECCO Safety Group" 1032 "SIMOL S.p.A." 1031 "Flintec UK Ltd." 1030 "Tume-Agri Oy" 1029 "The Marine Guardian LLC" 1028 "Autel Intelligent Technology Corp., Ltd" 1027 "Goldacres PTY LTD" 1026 "ZTR Control Systems, LLC" 1025 "eze System, Inc." 1024 "Inventus Power" 1023 "PEAK-System Technik GmbH" 1022 "ITC Inc" 1021 "Entratech Systems LLC" 1020 "Onyx Marine Automation s.r.l." 1019 "Codek Foundries" 1018 "Flex TTS" 1017 "Caldaro AB" 1016 "Röhren- und Pumpenwerk BAUER GmbH" 1015 "SECURITAG SAS" 1014 "Briri Maschinenbau GmbH" 1013 "Allochis E-Tec" 1012 "Rhodan Marine Systems of Florida LLC" 1011 "Soundmax Electronics Ltd" 1010 "Agricultural Industry Electronics Foundation e.V." 1009 "TouchTronics, Inc." 1008 "Lintest Systems LLC" 1007 "Maschinenfabrik Meyer-Lohne GmbH" 1006 "Proterra" 1005 "TSE Brakes, Inc." 1004 "Ultraflex SpA" 1003 "technotrans SE" 1002 "Kussmaul Electronics Co." 1001 "Cleral Inc." 1000 "Landmaschinen Wienhoff GmbH" 1569 "621 Technologies Inc." 999 "TerraTroniq B.V." 998 "Transcell Technology Inc" 997 "Xenta Systems Srl" 996 "Eniquest Pty Ltd" 995 "Circuitlink Pty Ltd." 994 "Morris Industries Ltd." 993 "Alelion Energy Systems AB" 992 "MarineIOT LLC" 991 "Deutronic Elektronik GmbH" 990 "SAMSUNG SDI Co., Ltd." 989 "Flux-Geräte GmbH" 988 "Voith Turbo" 987 "Baltic Car Equipment" 986 "AAMP Global" 985 "NLR, LLC" 984 "E-T-A Elektrotechnische Apparate GmbH" 983 "Dezwaef NV" 982 "Briggs & Stratton Corporation" 981 "Kobelt Manufacturing Co. Ltd" 980 "Gussi Italia S.R.L." 979 "McHale" 978 "Canfield Connector" 977 "Emerson Electric Co." 976 "Derive Systems, Inc." 975 "Siemens AG" 974 "Pico Technology Limited" 973 "Zasso GmbH" 972 "Axion AG" 971 "B+B Smartworx" 970 "Jaboni Power Products, LLC" 969 "Blue Sea Systems" 968 "Cox Powertrain Limited" 967 "Moteck Electric Corp." 966 "VisibleFarm" 965 "Ro-Sys Software" 964 "AgroVIR Kft" 963 "Thomason Jones Company, LLC" 962 "Timbolier Industries, Inc." 961 "POK SAS" 960 "Vemcon GmbH" 959 "Cascade Corporation" 958 "NHK MEC Corporation" 957 "Sierra Wireless Inc" 956 "Piher Sensors & Controls S.A." 955 "Hottinger Baldwin (Suzhou) Electronic Measurement Technology Co., Ltd." 954 "Setec Pty Ltd" 953 "Curtiss-Wright" 952 "Tan Delta Systems Ltd" 951 "Exor International S.p.A." 950 "RE:Lab s.r.l." 949 "Škoda Electric a.s." 948 "Donix" 947 "Gerd Bär GmbH" 946 "Hydac Tecnologia Ltda" 945 "Equalizer AG" 944 "ZONTISA Marine SL" 943 "FISCHER AG Präzisionspindeln" 942 "Vogelsang GmbH & Co. KG" 941 "Navya" 940 "Dometal Oy" 939 "Warn Industries, Inc." 938 "LEVEL Systems" 937 "Precision Circuits Inc" 936 "Hi-tech Millennium" 935 "Meels GmbH & Co. KG" 934 "Farmobile, Inc." 933 "Delta Mobile Systems, Inc." 932 "Discover Battery" 931 "Enertec Marine Ltd" 930 "Ecotronix Corp." 929 "Jl Marine Systems, Inc." 928 "EAO Automotive GmbH & Co. KG" 927 "Saicon" 926 "Buhler Industries Inc." 925 "GW Lisk Company" 924 "PAS Peschak Autonome Systeme GmbH" 923 "ELTEK S.p.A." 922 "Terberg Benschop B.V." 921 "ROPA Fahrzeug- und Maschinenbau GmbH" 920 "MTD Consumer Group Inc." 919 "Furrion LLC" 918 "AMW Machine Control, Inc" 917 "Sentinel d.o.o." 916 "Turck Inc." 915 "Dosificacion y sistemas electronicos S.L. (DSE)" 914 "ZETOR TRACTORS a.s." 913 "Toyota Motor Corporation" 912 "Steyr Motors GmbH" 911 "Nautic-On" 910 "Hermann Paus Maschinenfabrik GmbH" 909 "Marines Co., Ltd." 908 "Chonbuk National University Department of Electronics" 907 "strautmann" 906 "MOBA AG" 905 "ASA Electronics" 904 "Equipment Safety Systems Pty. Ltd. (EQSS)" 903 "InMotion" 902 "Bucher Hydraulics" 901 "Zivan Srl" 900 "OSB AG" 899 "Lippert Components, Inc" 898 "Josef Kotte Landtechnik GmbH & Co. KG" 897 "Dot Technology Corp." 896 "NextFour Solutions Ltd" 895 "Peloton Technology" 894 "Rhodan Marine Systems of Florida LLC" 893 "KlinkTechnics Ltd." 892 "Mectronx Corp" 891 "CarrierWeb" 890 "L3 Technologies, Inc." 889 "SANY America Inc" 888 "Carma Systems Inc" 887 "Hyperdrive Innovation Limited" 886 "Hitachi Zosen Corporation" 885 "SICK Stegmann GmbH" 884 "Sure Grip Controls Inc." 883 "Swift Navigation, Inc." 882 "BHTronik GmbH & Co. KG" 881 "Sovema" 880 "Revision Military" 879 "PG Trionic, Inc." 878 "FOTON" 877 "SICK ATech GmbH" 876 "SUCO Robert Scheuffele GmbH & Co. KG" 875 "Salvarani S.r.l." 874 "MTA S.p.A." 873 "Garnet Instruments Ltd." 872 "Kählig Antriebstechnik GmbH" 871 "Superior Tech Inc" 870 "Textron Fleet Management" 869 "Intercomp" 868 "Data Panel Corp" 867 "Skeleton Technologies" 866 "Netradyne, Inc." 865 "MyEasyFarm" 864 "Streamline Transportation Technologies Inc." 863 "SMAG" 862 "Prospec Electronics" 861 "Adel System S.r.l." 860 "Michelin" 859 "Valor" 858 "Littelfuse" 857 "Zoomlion Heavy Industry NA, Inc" 856 "FarmFacts GmbH" 855 "Toshiba Infrastructure Systems & Solutions Corporation" 854 "GEMAC Chemnitz GmbH" 853 "Teledyne RESON B.V." 852 "Velvac Inc" 851 "Novotechnik Messwertaufnehmer OHG" 850 "Geoprospectors GmbH" 849 "MTS Maschinentechnik Schrode AG" 848 "ningupex" 847 "Oceanvolt" 846 "L3 Magnet-Motor" 845 "GMB Güstrower Maschinenbau GmbH" 844 "FELL AS" 843 "Hendrickson Truck Commercial Vehicle Systems" 842 "DigiDevice Srl" 841 "Agra-GPS" 840 "E.S.T.E. Srl" 839 "Indexator Rotator Systems AB" 838 "Teamsurv Ltd" 837 "Famic Technologies Inc." 836 "Signature4" 835 "PetTrack Ltd." 834 "Pioneer Microsystems, Inc." 833 "Electrum Automation AB" 832 "Heizomat Gerätebau-Energiesysteme GmbH" 831 "DOK-ING Ltd." 830 "Ultra Motion LLC" 829 "Drov Technologies, Inc." 828 "AgriBrink Inc." 827 "INmatix Technology Group Ltd" 826 "Lewmar Marine Inc" 825 "BPW Hungária" 824 "Undheim Systems AS" 823 "ACEINNA, Inc (formerly MEMSIC, Inc)" 822 "Bren-Tronics, Inc." 821 "Thorsen Teknik A/S" 820 "DIaLOGIKa Gesellschaft fuer angewandte Informatik mbH" 819 "Preco Electronics" 818 "HGNSS" 817 "TE Connectivity Sensor Solutions" 816 "UniStrong" 815 "FLIR Systems, Inc." 814 "Kronotech Srl (formerly Soltec Soluzioni Tecnologiche Srl)" 813 "Thales Suisse SA" 812 "Torch Technologies" 811 "Blue Water Desalination" 810 "Dutch Power Company" 809 "HMS Industrial Networks AB" 808 "RIMEX Supply Ltd." 807 "Schneider-Electric" 806 "Charge Automotive Ltd" 805 "Gundersen & Løken AS" 804 "ASA Electronics" 803 "Gill Sensors & Controls Limited" 802 "SPBI (Bj Technologie)" 801 "LOR Manufacturing Company Inc." 800 "Delta-Q Technologies" 799 "Stillwater Designs and Audio, Inc. - KICKER" 798 "Lumishore Ltd" 797 "Tides Marine" 796 "Canadian Automotive Industries Ltd" 795 "Broyda Enterprises Pty Ltd" 794 "Shihlin Electric & Engineering Corporation" 793 "James Fisher Prolec" 792 "Kostal Mexicana" 791 "AUTEC" 790 "VACALL" 789 "GRADALL" 788 "MoTeC Pty Ltd" 787 "Abertax Technologies Limited" 1863 "Thomas G. Faria Co." 1862 "Sanshin" 1861 "Vector North America" 1860 "MMP" 1859 "Kvasar AB" 1858 "Litton" 1857 "Simrad" 1856 "Trimble" 1855 "Furuno USA" 1854 "Northstar Technologies" 1853 "Japan Radio Co" 1852 "Navionics" 1851 "RayMarine" 1850 "Seastar Solutions (formerly Teleflex)" 786 "Johnson Matthey Battery Systems" 785 "Fischer Panda GmbH" 784 "CM Automotive Systems, Inc." 783 "Loup Electronics Inc." 782 "AVR bv (formerly AVR bvba)" 781 "Poly-Planar LLC" 780 "AVID Technology Ltd" 779 "RLC Electronic Systems" 778 "Seakeeper Inc." 777 "Ocean Signal Ltd" 776 "HMI Systems LLC" 775 "ZIEHL-ABEGG Automotive GmbH" 774 "Taisho Corporation" 773 "Clarion Corporation of America" 772 "Blink Marine" 771 "Shaw Development, LLC" 770 "MONOSEM" 769 "Trombetta" 768 "Flores Automation, LLC" 767 "Alliance Wireless Technologies Inc." 766 "Epec Oy" 765 "GIGAVAC" 764 "Bednar FMT s.r.o." 763 "AT-Systems BVBA" 762 "ROJ s.r.l." 761 "MITA OLEODINAMICA S.p.A." 760 "Bernecker + Rainer Industrie Elektronik GmbH" 759 "Hydro-Gear" 758 "Banner Engineering Corp." 757 "IMPCO Technologies" 756 "Maschio Gaspardo S.P.A." 755 "Firefly Integrations" 754 "Parker Hannifin Corp., Automation Group" 753 "AIROD Technologies" 752 "Deep Sea Electronics Plc" 751 "Pacific Track" 750 "Joskin SA" 749 "Chart Inc." 748 "ISOTTA" 747 "Agratronix" 746 "SureFire Ag Systems, Inc." 745 "Cidra Corporate Services Inc." 744 "Woosung Engineering Co., Ltd." 743 "Daemyung Elevator Co., Ltd." 742 "EROAD" 741 "Carling Technologies" 740 "e-Traction" 739 "LXNAV d.o.o." 738 "Blue Ink Technologies" 737 "Balluff GmbH" 736 "Terex Aerial Work Platforms - Genie" 735 "AEM Performance Electronics" 734 "REAPsystems" 733 "Intendia S.L." 732 "Gefran S.p.A." 731 "Modine Manufacturing Company" 730 "BERTHOUD AGRICOLE" 729 "Liebherr" 728 "Streumaster (formerly Streumaster / Panien)" 727 "Dhoot Transmission Pvt Ltd." 726 "MIDORI PRECISIONS" 725 "Hitachi Construction Machinery Co., Ltd." 724 "Electronic Applications, Inc." 723 "Jabil Inc." 722 "Contelec AG" 721 "Hypro" 720 "WITZ Corporation" 719 "Cojali S. L." 718 "Micronet Inc" 717 "Yacht Devices Ltd" 716 "Eaton Control & Power Conversion Division (CPCD)" 715 "Autonnic Research Ltd" 714 "Kobashi Kogyo Co., Ltd." 713 "US Hybrid Corporation" 712 "LOR Manufacturing Company Inc." 711 "DAS Co., LTD" 710 "Greentronics Ltd." 709 "Marquardt GmbH" 708 "Lars Thrane A/S" 707 "Rochester Gauges Inc" 706 "Shanghai Diesel Engine Corporation Limited" 705 "SVAB Hydraulik AB" 704 "JL Audio, Inc." 703 "Hydro Tab Marine Engineering" 702 "Weichai Power Co., Ltd." 701 "BigRoad Inc." 700 "K-Tec Earthmovers Inc." 699 "Harman International Industries" 698 "Scorpion Technologies Ltd." 697 "Ålö AB" 696 "DRS Network & Imaging Systems, LLC (DRS Technologies)" 695 "Weldon Technologies" 694 "GasTOPS Ltd." 693 "Agility Fuel Solutions (formerly Agility Fuel Systems)" 692 "Tanhay Corporation" 691 "Digitroll Agricultural Electronics" 690 "LINAK A/S" 689 "Aarcomm Systems Inc" 688 "Rockford Corp" 687 "Flight Systems, Inc." 686 "Taigene Electric Machinery Corp." 685 "ANEDO (formerly ANEDO Ltd.)" 684 "KEB" 683 "Fosen Elektro" 682 "Eckelmann AG" 681 "BEDIA Motorentechnik GmbH & Co. KG" 680 "AMVAC Chemical Corporation" 679 "Cimco Marine AB" 678 "KeepTruckin, Inc." 677 "DSA Daten- und Systemtechnik GmbH" 676 "Danfoss IXA A/S" 675 "Kawasaki Motors Corp., USA" 674 "Yara International ASA" 673 "Caruelle Nicolas" 672 "OPTIMA Concept" 671 "Innovative Controls Inc." 670 "STEMCO LP" 669 "Quantum Fuel Systems Technologies Worldwide, Inc" 668 "MacDon Industries Ltd." 667 "Bartec" 666 "Schaeffler Technologies AG & Co., KG" 665 "Gebr. Bode GmbH & Co. KG" 664 "Level Developments Ltd" 663 "Delta Systems, Inc" 662 "Kissling Elektrotechnik GmbH" 661 "SPAL Automotive S.r.l." 660 "Auto-Gaz Centrum" 659 "Data Panel Corp." 658 "Shenzhen Jiuzhou Himunication Technology Co., Ltd" 657 "Terzo Power Systems" 656 "PRO SOLUS do Brasil" 655 "Genge & Thoma AG" 654 "Kohler Power Systems, Detroit Engine Development Center (DEDC)" 653 "AEV, spol. s r. o." 652 "MicroControl GmbH & Co. KG" 651 "Takakita Co, Ltd." 650 "Seiko Epson Corp." 649 "Control-Q B.V." 648 "OJSC Ekran" 647 "Siloking" 646 "Veenhuis Machines B.V." 645 "esd electronic system design gmbh" 644 "KUS USA" 643 "Bogballe A/S" 642 "Moog / Aspen Motion Technologies" 641 "Diverse Yacht Services" 640 "Power Solutions International" 639 "Startec s.r.l." 638 "KVH Industries, Inc." 637 "Bavaria Yachtbau GmbH" 636 "Divelbiss Corporation" 635 "Argo Tractors S.p.A." 634 "Rocky Research" 633 "TORC Robotics" 632 "Pepperl+Fuchs GmbH" 631 "Reltima" 630 "SmartDrive Systems Inc." 629 "Agri Info Design, Ltd." 524 "Vomax Instrumentation Pty. Ltd." 523 "Reggio Emilia Innovazione" 522 "Nebraska Tractor Test Laboratory" 521 "Clever Devices Ltd." 520 "Trapeze" 519 "Peeters Landbouwmachines b.v." 518 "Transas USA Inc." 517 "Noland Engineering" 516 "AVAT Automation GmbH" 515 "GINAF Trucks Nederland B.V." 514 "DISTek Integration, Inc." 513 "Precision Technology (Formerly FarmscanAg)" 512 "Inpower LLC" 511 "Sulky" 510 "Marinesoft Co. Ltd" 509 "MOTORTECH GmbH" 508 "Transtech Innovations" 507 "ISOBUS Test Center" 506 "IHI STAR Machinery Corporation" 505 "Yetter Farm Equipment" 504 "Vesper Marine" 503 "Naviop S.R.L." 502 "Attwood Corporation" 501 "Agrotronix S.A." 500 "Oxbo International Corporation" 499 "LCJ Capteurs" 498 "Innovative Design Solutions, Inc." 497 "SENTRON Sistemas Embarcados" 496 "W. Gessmann GmbH" 495 "HOLMER Maschinenbau GmbH" 494 "Synerject" 493 "Watcheye" 492 "Inergy Automotive Systems" 491 "Penny and Giles Ltd" 490 "QuikQ" 489 "Appareo Systems, LLC" 488 "The Charles Machine Works, Inc." 487 "DSE Test Solutions A/S" 486 "Westport Innovations Inc." 485 "MATT automotive" 484 "Headsight Inc." 483 "Valeo" 482 "Tricon Electronics" 481 "Chetco Digital Instruments" 480 "EnerDel, Inc." 479 "Vapor Bus International" 478 "OceanSat B.V." 477 "OilQuick AB" 476 "Hummingbird Marine Electronics" 475 "GME" 474 "Persen Technologies Inc." 473 "Boss Industries, Inc." 472 "Tenneco Inc." 471 "Sea Cross Marine AB" 628 "Falck Schmidt Defence Systems" 627 "Radio Ocean" 626 "AVL DiTEST GmbH" 625 "Global MRV Inc." 624 "Blackbox Machine Control Pty Ltd" 623 "Xirgo Technologies" 622 "Floyd Bell Inc" 621 "Hagie Manufacturing Company" 620 "Sevcon Ltd." 619 "Right Weigh Load Scales" 618 "Evrard SA" 617 "Zero Emission Vehicles" 616 "SMART-TEC s.r.o." 615 "Networkfleet, Verizon Telematics" 614 "ARLT Technologies GmbH" 613 "HKS Co., Ltd." 612 "Samwon IT" 611 "Esterline" 610 "Trail Tech" 609 "Walvoil S.p.A." 608 "Gale Banks Engineering" 607 "Knappco/Civacon" 606 "Intellian Technologies" 605 "Aventics GmbH" 604 "Indexator Rototilt Systems AB" 603 "Kereval" 602 "Nomad Digital Ltd." 601 "Navitas Systems" 600 "Aquatic AV" 599 "Spudnik Equipment Co, LLC" 598 "ABB Turbo Systems Ltd" 597 "Hydac Filter Systems GmbH" 596 "Brunelco Electronic Innovators B.V." 595 "CustomWare" 594 "Kongsberg Automotive" 593 "Sensata Technologies" 592 "tecsis GmbH" 591 "United States Coast Guard" 590 "ARGO-HYTOS GMBH" 589 "MICO, Inc." 588 "Vignal Systems" 587 "JCA Electronics" 586 "Suzuki Motor Corp" 585 "Industrial Electronic Controls" 584 "CarMedialab GmbH" 583 "Yachtcontrol" 582 "Innovative Software Engineering" 581 "Väderstad - Verken AB" 580 "San Jose Technology, Inc." 579 "KVH Industries, Inc." 578 "advanSea" 577 "Denchi Power Ltd  (formerly ABSL Power Solutions Limited)" 576 "Vectia" 575 "Lytx" 574 "Vishay Precision Group" 573 "Orolia Ltd" 572 "Fasse Valves" 571 "Marinecraft Co., Ltd." 570 "frenzel + berg electronic GmbH & Co. KG" 569 "LORD MicroStrain Sensing Systems" 568 "Makersan Ltd. Co." 567 "Lithiumstart LLC" 566 "Geode Technology, Inc." 565 "Micro-Trak Systems, Inc." 564 "Auto Power Electronic" 563 "LOHR Sistemas Eletronicos LTDA" 562 "Bombardier Transportation GmbH" 561 "b-plus GmbH" 560 "Iowa State University, Agricultural and Biosystems Engineering" 559 "Four Peaks Navigation" 558 "Davis Instruments Corp." 557 "Rockson Automation GmbH" 556 "Doosan Infracore Norway" 555 "Sasaki Corporation" 554 "iris-GmbH infrared & intelligent sensors" 553 "KIB Electronics" 552 "Matsuyama Plow Mfg Co, Ltd" 551 "Wexler CSD Ltd." 550 "SUN-A Corporation" 549 "ROAD Deutschland GmbH" 548 "TM4 Inc." 547 "Thomson Linear LLC" 546 "Maruyama Mfg Co, Inc." 545 "GS Hydraulics" 544 "Au Group Electronics" 543 "BAUER Maschinen GmbH" 542 "Dinamica Generale s.p.a." 541 "Total Fire Systems, Inc." 540 "Dinex A/S" 539 "Mobileview" 538 "Crop Ventures, Inc." 537 "Schrader Electronics Ltd." 536 "SSI Technologies" 535 "MOTORPAL, a.s." 534 "Webasto Thermo & Comfort SE" 533 "Doran Manufacturing, LLC" 532 "Onwa Marine Electronics Co Ltd." 531 "Genge & Thoma AG" 530 "NMEA" 529 "National Instruments Korea" 528 "Hoganas AB, Electric Drive Systems" 527 "GKN Walterscheid GmbH" 526 "LOFA Industries, Inc" 525 "Rust Sales INC" 470 "SI-TEX Marine Electronics" 469 "RA Consulting GmbH" 468 "Tyco Fire Protection Products" 467 "Lely Industries N.V." 466 "Veethree Electronics and Marine LLC" 465 "Ashcroft Inc" 464 "Leach International Corporation" 463 "PROBOTIQ" 462 "IHI Shibaura Machinery Corporation" 461 "HAWE Hydraulik SE" 460 "San Giorgio S.E.I.N." 459 "Alltek Marine Electronics Corp" 458 "Control Solutions, Inc." 457 "RUSELPROM-ElectricDrive Ltd" 456 "General Kinetics" 455 "ADZ NAGANO GmbH" 454 "NGK Spark Plug Co. Ltd" 453 "Cooper Bussmann" 452 "WIKA Alexander Wiegand SE & Co. KG" 451 "Parker Hannifin Corp" 450 "Dycor Technologies Ltd." 449 "Polaris Industries Inc" 448 "Stanadyne Corporation, Electronics Systems" 447 "Great Plains Mfg." 446 "CertTech, L.L.C." 445 "KAT MECHATRONIC, Electronic Product Division" 444 "ITT Power Solutions" 443 "SignalQuest, Inc." 442 "Horsch Maschinen GmbH" 441 "PTG Reifendruckregelsysteme GmbH" 440 "Cummins Power Generation" 439 "Hyundai Heavy Industries" 438 "Comar Systems Ltd" 437 "Digital Yacht Limited" 436 "Kinze Manufacturing" 435 "Zunhammer GmbH" 434 "Stored Energy Systems" 433 "Rowe Electronics" 432 "S&A Systems, Inc." 431 "Tohatsu Corporation" 430 "Auteq Telematica S.A." 429 "Rota Engineering Ltd." 425 "Methode Electronics Inc, MDI" 424 "Odyne LLC" 423 "BSM Wireless, Inc." 422 "True Heading AB" 421 "Vertex Standard Co, Ltd" 420 "Vermeer Corporation, ACS Group" 419 "Fusion Electronics Ltd" 418 "Intellistick Inc" 417 "KZValve" 416 "Kubota Corporation" 415 "Valid Manufacturing Ltd." 414 "Cattron Group International" 413 "Datapross Nijbroek bv" 412 "WebTech Wireless Inc." 411 "Hy-Drive Technologies Ltd." 410 "COBO S.p.A. Divisione 3B6" 409 "Transfluid S.r.L." 408 "Corvus Energy Ltd." 407 "Comtech Mobile Datacom" 406 "Vecima Networks Inc." 405 "Wema System AS" 404 "Com Nav Marine Ltd" 403 "Trackwell ADS, Inc." 402 "Simma Software, Inc." 401 "Torqeedo GmbH" 400 "Livorsi Marine" 399 "ISEKI & Co., Ltd." 398 "Hilite International" 397 "Sanyo-kiki Co Ltd." 396 "Beyond Measure" 395 "GENTEC S.R.L." 394 "Capi 2 Nederland B.V." 393 "Harvest Tec, Inc" 392 "Tianyuan Technology Co Ltd." 391 "Electronic Design for Industry, Inc" 390 "Partech Inc." 389 "Benchmark Electronics, Minnesota Division" 388 "Innomatix, LLC" 387 "Orscheln Products, LLC" 386 "JLG Automation BVBA" 385 "Johnson Outdoor Marine Electronics" 384 "Camano Light" 383 "MCL Industries" 382 "National Agriculture and Food Research Organization" 381 "B & G" 380 "Suntech International Ltd." 379 "Yamabiko Corporation" 378 "Glendinning Marine Products" 377 "ifm electronic gmbh" 376 "Quake Global" 375 "Williams Controls Inc." 374 "Northern Lights, Inc." 373 "Electronic Design Inc." 372 "Delphi" 371 "Heinzmann GmbH & Co. KG" 370 "Rolls-Royce Marine AS" 369 "Power Torque Engineering Ltd" 368 "HANSENHOF_electronic" 367 "Fliegl Agrartechnik" 366 "Viewnyx Corp." 365 "Digi-Star, LLC" 364 "OEM Controls Inc." 363 "BEI Duncan" 362 "Poettinger Landtechnik GmbH (formerly Alois Poettinger Maschinenfabrik GmbH)" 361 "InMach" 360 "HJS Emission Technology GmbH & Co KG   (formerly HJS Fahrzeugtechnik GmbH & Co KG)" 359 "Ludwig Bergmann GmbH" 358 "Victron Energy B.V." 357 "Hardi International A/S" 356 "Fischer Panda Generators, Inc" 355 "Mastervolt International B.V." 354 "Junkkari OY" 353 "Hegemon Electronics, Inc." 352 "SAME DEUTZ-FAHR GROUP S.p.A." 351 "Thrane & Thrane" 350 "Noris Marine Systems GmbH & Co KG" 349 "Suonentieto" 348 "Amazonen Werke H. Dreyer" 347 "Honeywell" 346 "Control Solutions" 345 "Korean Maritime University" 344 "Parvus Corporation" 343 "Baumer Group" 342 "THOMAS MAGNETE GmbH" 341 "Boning GmbH & Co" 340 "Continental AG" 339 "Competence Center ISOBUS e.V." 338 "GRAF-SYTECO" 337 "Carraro S.p.A." 336 "APE s.r.o." 335 "Evo Electric Ltd" 334 "Takata-Petri AG" 333 "Hadley Products Corporation" 332 "HWH Corporation" 331 "Horton, Inc." 330 "Kidde Aerospace and Defense" 329 "Deif A/S" 328 "Qwerty Electronik AB" 327 "Sonceboz SA" 326 "Akron Brass Company" 325 "ASM Automation Sensorik Messtechnik GmbH" 324 "Snap-on Diagnostics" 323 "Mobileye Vision Technologies Ltd." 322 "MICHENKA s.r.o." 321 "Ultra Electronics, Electrics" 320 "Miedema Landbouwwerktuigenfabriek B.V." 319 "Cadec Global" 318 "SAT Plan" 317 "Navtronics Bvba" 263 "IMMI" 262 "HydraForce, Inc" 261 "Red Dot Corporation" 260 "Reichhardt GmbH Steuerungstechnik" 259 "Jetter AG" 258 "ARAG" 257 "Honda Motor Co., Ltd" 256 "Tyco Electronics AMP" 255 "MEAS France" 254 "GE Sensing" 253 "Mobile Control Systems" 252 "Sensor-Technik Wiedemann GmbH" 251 "German Agricultural Society, Test Center (DLG)" 250 "Kuhn Group" 249 "Schaltbau GmbH" 248 "Cooper Standard Automotive Active Systems Group" 247 "ePULSE" 246 "Class 1, Inc" 245 "Capstan Ag Systems, Inc." 244 "Techno-Matic" 243 "eRide, Inc." 242 "Kokusandenki Co. Ltd" 241 "Schneider Automation SAS" 240 "Vanair Mfg" 239 "May & Scofield Ltd" 238 "ZF Friedrichshafen AG" 237 "Agtron Enterprises Inc" 236 "NORAC Systems International Inc" 235 "SailorMade Marine Telemetry - Tetra Technology Ltd." 234 "Mondial electronic GmbH" 233 "Yacht Monitoring Solutions Inc." 232 "TSD Integrated Controls" 231 "Topcon Positioning Systems, Inc." 230 "Saucon Technologies" 229 "Garmin International Inc." 228 "Unused (formerly ZF Marine Electronics)" 227 "Lykketronic A/S" 226 "Monaco Coach Corporation" 225 "SKF" 224 "EMMI Network, S.L." 223 "Vaueo Retarder Co., Ltd." 222 "Generac Power Systems, Inc." 221 "SiE" 220 "Beede Electrical Instrument Company, Inc" 219 "Cat OEM Solutions" 218 "Gits Manufacturing Company" 217 "RM Michaelides Software & Elektronik GmbH" 216 "Paneltronics Inc." 215 "Aetna Engineering/Fireboy-Xintex" 214 "MC elettronica Srl" 164 "MTU Friedrichshafen GmbH (formerly DaimlerChrysler Off-Highway)" 163 "BRP Inc." 162 "Axiomatic Technologies" 161 "Offshore Systems (UK) Ltd" 160 "Nido" 159 "NTech Industries Inc" 158 "Firestone Industrial Products Company" 157 "ISSPRO Inc." 156 "ITT Industries - Cannon" 155 "Vetronix Corporation" 154 "Westerbeke Corporation" 153 "Woodward, Industrial Controls Division" 152 "elobau GmbH & Co. KG" 151 "Raven Industries, Inc." 150 "Fleetguard" 149 "Holset" 148 "Blue Water Data, Inc." 147 "Nautibus electronic GmbH" 146 "Maxima Technologies" 145 "MurCal Controls" 144 "Mercury Marine" 143 "W. Gmeiner GmbH & Co." 142 "TRW Automotive (Commercial Steering Systems)" 141 "Thales Navigation Ltd." 140 "Lowrance Electronics, Inc." 139 "Caterpillar Trimble Control Technologies (CTCT), LLC" 138 "Georg Fritzmeier GmbH & Co. KG" 137 "Maretron" 136 "Komatsu Ltd" 135 "Airmar Technology Corporation" 134 "Iris Technology Ltd" 133 "Bucher Schoerling GmbH" 132 "Mulag-Fahrzeugwerk" 131 "ITT Industries" 130 "Nido - Universal Machines B.V." 129 "OMNEX Control Systems Inc." 128 "Gerhard Duecker GmbH & Co. KG" 127 "Holland USA" 126 "Driver Tech" 125 "Nevada Automotive Test Center" 124 "Hydac Electronic" 123 "Basler Electric" 122 "FG Wilson (Engineering) Limited" 121 "HED (Hydro Electronic Devices, Inc.)" 120 "RDS Technology Ltd" 119 "IntegriNautics  " 118 "Intron GmbH" 117 "HUSCO International" 116 "BEELINE Technologies" 115 "NACCO Materials Handling Group, Inc." 114 "EControls, Inc." 113 "Stress-Tek, Inc." 112 "MECALAC" 111 "Bernard Krone Holding SE & Co. KG (formerly Maschinenfabrik Bernard Krone GmbH)" 110 "EPIQ Sensor-Nite" 109 "TeeJet Technologies Denmark (formerly LH Technologies ApS)" 108 "WTK-Elecktronik GmbH" 107 "Grimme Landmaschinen GmbH & Co. KG" 106 "BAE Systems Controls, Inc." 105 "Kiepe Elektrik GmbH & Co. KG" 104 "CLAAS KGaA mbH (formerly CLAAS Selbstfahrende Erntemaschinen GmbH)" 103 "CLAAS E-Systems GmbH (formerly CLAAS E-Systems KGaA mbH & Co. KG)" 102 "AGCO (formerly AGCO GmbH & Co.)" 101 "Sensoria" 100 "VDO Technik AG" 99 "International Transmissions Ltd (ITL)" 98 "Mueller-Elektronik GmbH & Co" 97 "Ag Leader Technology, Inc." 96 "Mech@tronic IT GmbH" 95 "Pacific Insight Electronics Corp." 94 "CNH Industrial N.V. (formerly CNH Global N.V.)" 93 "Perkins Engines Company Ltd." 92 "Ag-Chem Equipment Co., Inc." 91 "BSG Bodensee Steuergeraete GmbH" 90 "Knorr-Bremse SfN GmbH" 89 "Kverneland Group, Electronics Division" 88 "Hemisphere GPS Inc (formerly Satloc Precision GPS)" 87 "J.C. Bamford Excavators Ltd (JCB)" 86 "C. E. Niehoff & Company" 85 "Kohler Co" 84 "New Holland UK Limited" 83 "Bendix VORAD Technologies (formerly Eaton VORAD Technologies)" 82 "Bobcat/Ingersoll-Rand (formerly Melroe/Ingersoll-Rand)" 81 "Fire Research Corp." 80 "Twin Disc, Inc." 79 "Daimler Benz AG - Engine Division (PBM)" 78 "Frank W. Murphy Manufacturing, Inc" 77 "Deere Power Systems Group" 76 "unused (formerly Deere & Co, Construction Division)" 75 "Deere & Co, Agricultural Division" 74 "Eaton Axle-Brake Division" 73 "LeTourneau, Inc." 72 "Sisu Corporation" 71 "Vansco Electronics Ltd." 70 "Flex-coil Limited" 69 "Trimble Navigation" 316 "ITT Flow Control" 315 "Icom Incorporated" 314 "CSM GmbH" 313 "Ilmor Engineering, Inc." 312 "Lectronix, Inc." 311 "Patrick Power Products" 310 "TECNORD srl" 309 "Krauss-Maffei Wegmann GmbH & Co. KG" 308 "Cyntrx" 307 "MAS Technologies" 306 "Sleipner Motor AB" 305 "NovAtel Inc" 304 "EmpirBus AB" 303 "CTS Corporation" 302 "Nissin Kogyo Co., LTD" 301 "Parker Hannifin (UK) Ltd FDE group" 300 "Systron Donner Automotive" 299 "Rauch" 298 "Holley Performance" 297 "Zonar Systems Inc" 296 "micro dynamics GmbH" 295 "BEP Marine" 294 "Grayhill Inc." 293 "Spyder Controls Corp." 292 "IKUSI - Angel Iglesias S.A." 291 "Groeneveld Transport Efficiency BV" 290 "Kuebler GmbH" 289 "Watlow" 288 "Mitsubishi FUSO Truck & Bus Corp." 287 "NTech Industries, Inc" 286 "Coelmo srl" 285 "Sea Recovery Corp" 284 "Mobile Tech Chile" 283 "CWF Hamilton & Co Ltd" 282 "Medallion Instrumentation Systems" 281 "Precision Governors LLC" 280 "Leica Geosystems Pty Ltd" 279 "Geometris LP" 278 "Takata Electronics" 277 "LHP Telematics" 276 "Aqua-Hot Heating Systems" 275 "Navico Egersund AS" 274 "LTW Technology Co., LTD" 273 "Active Research Limited" 272 "Gross Mechanical Laboratories, Inc" 271 "Cole Hersee" 270 "Tennant" 269 "Saft America Inc.,  Space & Defense Division" 268 "Accurate Technologies" 267 "Red Lion Controls, Inc" 266 "International Thermal Research Ltd" 265 "MTS Sensor Technologie GmbH" 264 "Autolync" 213 "CNH Belgium N.V." 212 "Sure Power Industries, Inc" 211 "DNA Group" 210 "Iteris, Inc." 209 "Bell Equip. Co. SA (PTY) LTD" 208 "Drew Technologies, Inc" 207 "Otto Engineering" 206 "port GmbH" 205 "SmarTire Systems Inc" 204 "The Morey Corporation" 203 "MILtronik GmbH" 202 "Curtis Instruments, Inc" 201 "Disenos y Tecnologia S.A." 200 "MGM Brakes" 199 "ACTIA Group (formerly Actia Corp)" 198 "Mystic Valley Communications" 197 "Mechron Power Systems" 196 "LEMKEN GmbH & Co KG" 195 "General Engine Products" 194 "TriMark Corporation" 193 "Jeppesen Marine" 192 "Floscan" 191 "XRS Corporation (formerly XATA Corporation)" 190 "Hella KGaA Hueck & Co" 189 "QUALCOMM" 188 "EMP Corp" 187 "Air-Weigh" 186 "Altronic, Inc" 185 "Beede Electrical Instrument Company" 184 "EIA Electronics" 183 "KDS Controls, Inc" 182 "Vehicle Systems Engineering B.V." 181 "Coretronics, Inc." 180 "Smart Power Systems" 179 "TeeJet Technologies Springfield (formerly Midwest Technologies Illinois, LLC)" 178 "Continental Automotive GmbH (formerly Siemens VDO Automotive AG)" 177 "Diagnostic Systems Associates" 176 "Moritz Aerospace" 175 "Veris Technologies, Inc." 174 "AB Volvo Penta" 173 "Ryeso, Inc." 172 "Yanmar Co., Ltd. (formerly Yanmar Marine USA)" 171 "Topcon Electronics GmbH & Co. KG (formerly Wachendorff Elektronik GmbH & Co. KG)" 170 "Computronics Corporation Ltd." 169 "Marlin Technologies Inc." 168 "Xantrex" 167 "JLG Industries Inc" 166 "John Deere Electronic Solutions (formerly Phoenix International)" 165 "CPAC Systems AB" 68 "Scania" 67 "John Deere Coffeyville Works (formerly Funk Manufacturing Company)" 66 "John Deere Construction Equipment Division" 65 "MAN Nutzfahrzeuge AG" 64 "Unused (formerly SpectraPrecision Laserplane, then SpectraPhysics)" 63 "ZF Industries Inc." 62 "Wabco" 61 "Volvo Truck Corp." 60 "Volvo Trucks North America Inc." 59 "VES Inc." 58 "SPX Corporation, OTC Div" 57 "Danfoss  (formerly Sauer Sundstrand Co, then Sauer-Danfoss Co)" 56 "SAIC" 55 "Ryder System Inc." 54 "Meritor Wabco" 53 "Continental Automotive Systems US, Inc. (formerly Rockwell Land Transportation)" 52 "Meritor Automotive, Inc. (formerly Rockwell Automotive)" 51 "Robert Bosch GmbH" 50 "Robert Bosch Corp" 49 "RE America Inc." 48 "Pollak Alphabet" 47 "Phillips Semiconductor" 46 "Noregon Systems, Inc  (formerly Parasoft Computing Solutions)" 45 "PACCAR" 44 "Nippondenso Co. Ltd." 43 "International Truck and Engine Corporation - Vehicle Electronics (formerly Navistar Intl Trans Corp.)" 42 "International Truck and Engine Corporation - Engine Electronics  (formerly Navistar Intl Trans Co., Engine Electronics)" 41 "Motorola Inc." 40 "Motorola AIEG Inc." 39 "Microfirm Inc." 38 "Micro Processor Systems Inc." 37 "Mack Trucks Inc." 36 "Lucas Ind." 35 "Kenworth Truck Co." 34 "Kelsey Hayes Co." 33 "John Deere" 32 "Jacobs Vehicle Systems" 31 "J Pollak Corp" 30 "Isuzu Motors Ltd" 29 "Hino Motors Ltd." 28 "Grote Ind. Inc." 27 "GMC" 26 "General Motors Corp, Service Technology Grp" 25 "Daimler Trucks North America LLC (formerly Freightliner LLC)" 24 "Ford Motor Co., Vehicle Controls" 23 "Ford Motor Co., Heavy Truck" 22 "Ford Motor Co., Electronic Concepts & Systems" 21 "Echlin Inc., Midland Brake Inc." 20 "Eaton Ltd" 19 "Eaton Corp. Trucking Info Services" 18 "Eaton Corp, Transmission Div." 17 "Eaton Corp, Corp Res & Dev" 16 "Eaton Corp" 15 "DICKEY-john Corporation" 14 "Detroit Diesel Corporation" 13 "Delco Electronics" 12 "Deere & Company, Precision Farming" 11 "Dearborn Group Inc." 10 "Cummins Inc (formerly Cummins Engine Co)" 9 "Chrysler Corp." 8 "Caterpillar Inc." 7 "Case Corp." 6 "Berifors Electronics AB" 5 "AMP Inc." 4 "Ametek-Dixson" 3 "Ametek, US Gauge Division" 2 "Allison Transmission, Inc." 1 "Bendix Commercial Vehicle Systems LLC (formerly Allied Signal Inc.)" 0 "Reserved" ;
VAL_ 2633895166 VehicleSystem 127 "Not Available" 0 "NonSpecificSystem" ;
VAL_ 2633895166 VehicleSystem1 0 "NonSpecificSystem" 127 "Not Available" 1 "Tractor" 2 "Trailer" ;
VAL_ 2633895166 VehicleSystem2 0 "NonSpecificSystem" 127 "Not Available" 1 "Tractor" 2 "Tillage" 3 "Secondary Tillage" 4 "Planters/Seeders" 5 "Fertilizers" 6 "Sprayers" 7 "Harvesters" 8 "Root Harvesters" 9 "Forage" 10 "Irrigation" 11 "Transport/Trailer" 12 "Farm Yard Operations" 13 "Powered Auxiliary Device" 14 "Special Crops" 15 "Earth Work" 16 "Skidder" 17 "Sensor Systems" 19 "Timber Harvesters" 20 "Forwarders" 21 "Timber loaders" 22 "Timber Processing Machines" 23 "Mulchers" 24 "Utility Vehicles" 25 "Slurry Applicators" ;
VAL_ 2633895166 VehicleSystem3 0 "NonSpecificSystem" 127 "Not Available" 1 "Skid Steer Loader" 2 "Articulated Dump Truck" 3 "Backhoe" 4 "Crawler" 5 "Excavator" 6 "Forklift" 7 "Four Wheel Drive Loader" 8 "Grader" ;
VAL_ 2633895166 VehicleSystem4 0 "NonSpecificSystem" 127 "Not Available" 10 "System Tools" 20 "Safety Systems" 25 "Inter/Intranetwork Device" 30 "Electrical Distribution" 40 "Steering and Control Surfaces" 50 "Propulsion" 60 "Navigation" 70 "Communications" 80 "Instrumentation/General Systems (deprecate)" 90 "Internal Environment" 100 "Deck, Cargo and Fishing Equipment" 35 "Electrical Generation" 75 "Sensor Communication Interface" 85 "External Environment" 120 "Display" 125 "Entertainment" ;
VAL_ 2633895166 VehicleSystem5 0 "Ind. Process Control Stationary" 127 "Not Available" ;
VAL_ 2365459454 TactorControlModeCmd2 31 "DoNotCare" 18 "UserDefinedControl" 17 "EnableGuidanceControl" 16 "EnableRearDraftForceControl" 15 "EnableFrontDraftForceControl" 14 "EnableRearPTOTorqueControl" 13 "EnableFrontPTOTorqueControl" 12 "EnableEngineEconomyCruiseControl" 11 "EnableMinimumEngineSpeedControl" 10 "EnableConstPTOSpeedCruiseControl" 9 "EnableConstantPTOSpeedControl" 8 "EnableMaximumDraftPowerControl" 7 "EnableAuxiliaryValveSlipControl" 6 "EnableReduceSpeedSlipControl" 5 "EnableRearPTOSlipControl" 4 "EnableFrontPTOSlipControl" 3 "EnableRearHitchSlipControl" 2 "EnableFrontHitchSlipControl" 1 "EnableCruiseControl" 0 "DisableRemoteControl" ;
VAL_ 2365459454 TractorControlModeCmd1 31 "DontCare" 17 "EnableGuidanceControl" 16 "EnableRearDraftForceControl" 15 "EnableFrontDraftForceControl" 14 "EnableRearPTOTorqueControl" 13 "EnableFrontPTOTorqueControl" 12 "EnableEngineEconomyCruiseControl" 11 "EnableMinimumEngineSpeedControl" 10 "EnableConstPTOSpeedCruiseControl" 9 "EnableConstantPTOSpeedControl" 8 "EnableMaximumDraftPowerControl" 7 "EnableAuxiliaryValveSlipControl" 6 "EnableReduceSpeedSlipControl" 5 "EnableRearPTOSlipControl" 4 "EnableFrontPTOSlipControl" 3 "EnableRearHitchSlipControl" 2 "EnableFrontHitchSlipControl" 1 "EnableCruiseControl" 0 "DisableRemoteControl" ;
VAL_ 2365459198 TractorControlModeResponse2 31 "NotAvailable" 23 "EnableGuidanceControl" 22 "EnableRearDraftForceControl" 21 "EnableFrontDraftForceControl" 20 "EnableRearPTOTorqueControl" 19 "EnableFrontPTOTorqueControl" 18 "EnEngineEcoSpdNavigSpdCruiseCtrl" 17 "EnEngineEcoSpdWheelSpdCrusieCtrl" 16 "EnEngineEcoSpdGndSpeedCruiseCtrl" 15 "EnableMinimumEngineSpeedControl" 14 "EnCoPTOSpeedNavigSpeedCruisCtrl" 13 "EnCoPTOSpeedWheelSpeedCruiseCtrl" 12 "EnCoPTOSpeedGndSpeedCruisCtrl" 11 "EnableConstantPTOSpeedControl" 10 "EnableMaximumDraftPowerControl" 9 "EnableReduceSpeedSlipControl" 8 "EnableAuxiliaryValveSlipControl" 7 "EnableRearPTOSlipControl" 6 "EnableFrontPTOSlipControl" 5 "EnableRearHitchSlipControl" 4 "EnableFrontHitchSlipCtrl" 3 "EnableNavigationSpeedCruiseCtrl" 2 "EnableWheelSpeedCruiseControl" 1 "EnableGroundSpeedCruiseControl" 0 "DisableRemoteControl" ;
VAL_ 2365459198 TractorControlLimitStatus2 0 "Not limited" 1 "Operator Limited" 2 "Limited High" 3 "Limited Low" 4 "Reserved" 5 "Reserver" 6 "Non-recoverable Fault" 7 "Not available" ;
VAL_ 2365459198 TractorControlModeResponse1 31 "NotAvailable" 23 "EnableGuidanceControl" 22 "EnableRearDraftForceControl" 21 "EnableFrontDraftForceControl" 20 "EnableRearPTOTorqueControl" 19 "EnableFrontPTOTorqueControl" 18 "EnEngineEcoSpdNavigSpdCruiseCtrl" 17 "EnEngineEcoSpdWheelSpdCrusieCtrl" 16 "EnEngineEcoSpdGndSpeedCruiseCtrl" 15 "EnableMinimumEngineSpeedControl" 14 "EnCoPTOSpeedNavigSpeedCruisCtrl" 13 "EnCoPTOSpeedWheelSpeedCruiseCtrl" 12 "EnCoPTOSpeedGndSpeedCruisCtrl" 11 "EnableConstantPTOSpeedControl" 10 "EnableMaximumDraftPowerControl" 9 "EnableReduceSpeedSlipControl" 8 "EnableAuxiliaryValveSlipControl" 7 "EnableRearPTOSlipControl" 6 "EnableFrontPTOSlipControl" 5 "EnableRearHitchSlipControl" 4 "EnableFrontHitchSlipCtrl" 3 "EnableNavigationSpeedCruiseCtrl" 2 "EnableWheelSpeedCruiseControl" 1 "EnableGroundSpeedCruiseControl" 0 "DisableRemoteControl" ;
VAL_ 2365459198 TractorControlLimitStatus1 0 "Not limited" 1 "Operator Limited" 2 "Limited High" 3 "Limited Low" 4 "Reserved" 5 "Reserver" 6 "Non-recoverable Fault" 7 "Not available" ;
VAL_ 2365458942 OperatorExtLightControls 1 "Facility available" 0 "Facility not available" ;
VAL_ 2365458942 MachineSelectedSpeed 1 "Facility available" 0 "Facility not available" ;
VAL_ 2365458942 MachineSelectedSpeedControl 1 "Facility available" 0 "Facility not available" ;
VAL_ 2365458942 DirectionControl 1 "Facility available" 0 "Facility not available" ;
VAL_ 2365458942 DriveStrategyStatusAndCommands 1 "Facility available" 0 "Facility not available" ;
VAL_ 2365458942 ExtGuidanceStatusAndCmd 1 "Facility available" 0 "Facility not available" ;
VAL_ 2365458942 PTOCmd_FrontPTOModeGearCmd 1 "Facility available" 0 "Facility not available" ;
VAL_ 2365458942 PTOCmd_RearPTOModeGearCmd 1 "Facility available" 0 "Facility not available" ;
VAL_ 2365458942 ReservedBitIndicator 1 "Reserved bits are set to 1" 0 "Reserved bits are set to 0" ;
VAL_ 2365458942 HitchInfo_FrontPosition 1 "FrontPositionAvailable" 0 "FrontPositionNotAvailable" ;
VAL_ 2365458942 HitchInfo_FrontInWork 1 "FrontInWorkAvailable" 0 "FrontInWorkNotAvailable" ;
VAL_ 2365458942 PTOInfo_FrontShaftSpeed 1 "FrontShaftSpeedAvailable" 0 "FrontShaftSpeedNotAvailable" ;
VAL_ 2365458942 PTOInfo_FrontShaftEngagement 1 "FrontShaftEgtAvailable" 0 "FrontShaftEgtNotAvailable" ;
VAL_ 2365458942 AddHitchParameter__FrontDraft 1 "FrontDraftAvailable" 0 "FrontDraftNotAvailable" ;
VAL_ 2365458942 HitchCmd_FrontHitchPosition 1 "FrontHitchPosAvailable" 0 "FrontHitchPosNotAvailable" ;
VAL_ 2365458942 PTOCmd_FrontPTOSpeedCmd 1 "FrontPTOSpeedCmdAvailable" 0 "FrontPTOSpeedCmdNotAvailable" ;
VAL_ 2365458942 PTOCmd_FrontPTOEngagementCmd 1 "FrontPTOEgtCmdAvailable" 0 "FrontPTOEgtCmdNotAvailable" ;
VAL_ 2365458942 NavigSystemHighOutputPosition 1 "NavigSysHOutPosDataAvailable" 0 "NavigSysHOutPosDataNotAvailable" ;
VAL_ 2365458942 NavigSystemPositionData 1 "NavigSysPosDataAvailable" 0 "NavigSysPosDataNotAvailable" ;
VAL_ 2365458942 NavigPseudorangeNoiseStatistic 1 "NavigPsdoNoiseStatAvailable" 0 "NavigPsdoNoiseStatNotAvailable" ;
VAL_ 2365458942 HitchCmd_RearHitchPosition 1 "HitchRearPosAvailable" 0 "HitchRearPosNotAvailable" ;
VAL_ 2365458942 PTOCmd_RearPTOSpeedCmd 1 "RearPTOSpeedCmdAvailable" 0 "RearPTOSpeedCmdNotAvailable" ;
VAL_ 2365458942 PTOCmd_RearPTOEngagementCmd 1 "RearPTOEgtCmdAvailable" 0 "RearPTOEgtCmdNotAvailable" ;
VAL_ 2365458942 AuxiliaryValveCmd 1 "AuxiliaryValveCmdsAvailable" 0 "AuxiliaryValveCmdsNotAvailable" ;
VAL_ 2365458942 LimitStatusReporting 0 "Facility not available" 1 "Facility available" ;
VAL_ 2365458942 TimeDate 1 "TimeAndDateAvailable" 0 "TimeAndDateNotAvailable" ;
VAL_ 2365458942 SpeedAndDist_GndBasedDistance 1 "GndBasedDistanceAvailable" 0 "GndBasedDistanceNotAvailable" ;
VAL_ 2365458942 SpeedAndDist_GndBasedDirection 1 "GndBasedDirectionAvailable" 0 "GndBasedDirectionNotAvailable" ;
VAL_ 2365458942 SpeedAndDist_WheelBasedDistance 1 "WheelBasedDistanceAvailable" 0 "WheelBasedDistanceNotAvailable" ;
VAL_ 2365458942 SpeedAndDist_WheelBasedDirection 1 "WheelBasedDirectionAvailable" 0 "WheelBasedDirectionNotAvailable" ;
VAL_ 2365458942 AddHitchParameter_RearDraft 1 "HitchInfo_RearDraftAvailable" 0 "HitchInfo_RearDraftNotAvailable" ;
VAL_ 2365458942 Light_FullImplLightingMessageSet 1 "FullImplLightMsgSetAvailable" 0 "FullImplLightMsgSetNotAvailable" ;
VAL_ 2365458942 EstimatedOrMeasuredAuxValveState 1 "EstOrMeasAuxValStatAvailable" 0 "EstOrMeasAuxValStatNotAvailable" ;
VAL_ 2365458942 HitchInfo_RearPosition 1 "HitchInfo_RearInPosAvailable" 0 "HitchInfo_RearInPosNotAvailable" ;
VAL_ 2365458942 HitchInfo_RearInWork 1 "HitchInfo_RearInWorkAvailable" 0 "HitchInfo_RearInWorkNotAvailable" ;
VAL_ 2365458942 PTOInfo_RearShaftSpeed 1 "PTOInfo_RearShaftSpdAvailable" 0 "PTOInfo_RearShaftSpdNotAvailable" ;
VAL_ 2365458942 PTOInfo_RearShaftEngagement 1 "PTOInfo_RearShaftEgtAvailable" 0 "PTOInfo_RearShaftEgtNotAvailable" ;
VAL_ 2365458942 Lighting_MinimalSet 1 "MinSetAvailable" 0 "MinSetNotAvailable" ;
VAL_ 2365458942 LanguageCmdStorageInTractorECU 1 "LangCmdAvailableInTractorECU" 0 "LangCmdNotAvailableInTractorECU" ;
VAL_ 2365458942 TractorClass 3 "NotAvailable" 2 "TECU_Class_3" 1 "TECU_Class_2" 0 "TECU_Class_1" ;
VAL_ 2365458942 PowerMgt_KeySwitch 1 "KeySwitchPwrMgtAvailable" 0 "KeySwitchPwrMgtNotAvailable" ;
VAL_ 2365458942 PowerMgt_MaxTimeTractorPower 1 "MaxTimeTractorPwrMgtAvailable" 0 "MaxTimeTractorPwrMgtNotAvailable" ;
VAL_ 2365458942 PowerMgt_MaintainPower 1 "MainPwrMgtAvailable" 0 "MainPwrMgtNotAvailable" ;
VAL_ 2365458942 SpeedInfo_WheelBasedSpeed 1 "WheelBasedSpeedInfoAvailable" 0 "WheelBasedSpeedInfoNotAvailable" ;
VAL_ 2365458942 SpeedInfo_GroundBasedSpeed 1 "GndBasedSpeedInfoAvailable" 0 "GndBasedSpeedInfoNotAvailable" ;
VAL_ 2365458942 SpeedInfo_EngineSpeed 1 "EngineSpeedInfoAvailable" 0 "EngineSpeedInfoNotAvailable" ;
VAL_ 2365458686 DriveStrategyStatusAndCommands 1 "Facility available" 0 "Facility not available" ;
VAL_ 2365458686 ExtGuidanceStatusAndCmd 1 "Facility available" 0 "Facility not available" ;
VAL_ 2365458686 PTOCmd_FrontPTOModeGearCmd 1 "Facility available" 0 "Facility not available" ;
VAL_ 2365458686 PTOCmd_RearPTOModeGearCmd 1 "Facility available" 0 "Facility not available" ;
VAL_ 2365458686 HitchInfo_FrontPosition 1 "FrontPositionAvailable" 0 "FrontPositionNotAvailable" ;
VAL_ 2365458686 HitchInfo_FrontInWork 1 "FrontInWorkAvailable" 0 "FrontInWorkNotAvailable" ;
VAL_ 2365458686 PTOInfo_FrontShaftSpeed 1 "FrontShaftSpeedAvailable" 0 "FrontShaftSpeedNotAvailable" ;
VAL_ 2365458686 PTOInfo_FrontShaftEngagement 1 "FrontShaftEgtAvailable" 0 "FrontShaftEgtNotAvailable" ;
VAL_ 2365458686 AddHitchParameter__FrontDraft 1 "FrontDraftAvailable" 0 "FrontDraftNotAvailable" ;
VAL_ 2365458686 HitchCmd_FrontHitchPosition 1 "FrontHitchPosAvailable" 0 "FrontHitchPosNotAvailable" ;
VAL_ 2365458686 PTOCmd_FrontPTOSpeedCmd 1 "FrontPTOSpeedCmdAvailable" 0 "FrontPTOSpeedCmdNotAvailable" ;
VAL_ 2365458686 PTOCmd_FrontPTOEngagementCmd 1 "FrontPTOEgtCmdAvailable" 0 "FrontPTOEgtCmdNotAvailable" ;
VAL_ 2365458686 NavigSystemHighOutputPosition 1 "NavigSysHOutPosDataAvailable" 0 "NavigSysHOutPosDataNotAvailable" ;
VAL_ 2365458686 NavigSystemPositionData 1 "NavigSysPosDataAvailable" 0 "NavigSysPosDataNotAvailable" ;
VAL_ 2365458686 NavigPseudorangeNoiseStatistic 1 "NavigPsdoNoiseStatAvailable" 0 "NavigPsdoNoiseStatNotAvailable" ;
VAL_ 2365458686 DirectionControl 1 "Facility available" 0 "Facility not available" ;
VAL_ 2365458686 HitchCmd_RearHitchPosition 1 "HitchRearPosAvailable" 0 "HitchRearPosNotAvailable" ;
VAL_ 2365458686 PTOCmd_RearPTOSpeedCmd 1 "RearPTOSpeedCmdAvailable" 0 "RearPTOSpeedCmdNotAvailable" ;
VAL_ 2365458686 PTOCmd_RearPTOEngagementCmd 1 "RearPTOEgtCmdAvailable" 0 "RearPTOEgtCmdNotAvailable" ;
VAL_ 2365458686 AuxiliaryValveCmd 1 "AuxiliaryValveCmdsAvailable" 0 "AuxiliaryValveCmdsNotAvailable" ;
VAL_ 2365458686 LimitStatusReporting 0 "Facility not available" 1 "Facility available" ;
VAL_ 2365458686 TimeDate 1 "TimeAndDateAvailable" 0 "TimeAndDateNotAvailable" ;
VAL_ 2365458686 SpeedAndDist_GndBasedDistance 1 "GndBasedDistanceAvailable" 0 "GndBasedDistanceNotAvailable" ;
VAL_ 2365458686 SpeedAndDist_GndBasedDirection 1 "GndBasedDirectionAvailable" 0 "GndBasedDirectionNotAvailable" ;
VAL_ 2365458686 SpeedAndDist_WheelBasedDistance 1 "WheelBasedDistanceAvailable" 0 "WheelBasedDistanceNotAvailable" ;
VAL_ 2365458686 SpeedAndDist_WheelBasedDirection 1 "WheelBasedDirectionAvailable" 0 "WheelBasedDirectionNotAvailable" ;
VAL_ 2365458686 AddHitchParameter_RearDraft 1 "HitchInfo_RearDraftAvailable" 0 "HitchInfo_RearDraftNotAvailable" ;
VAL_ 2365458686 Light_FullImplLightingMessageSet 1 "FullImplLightMsgSetAvailable" 0 "FullImplLightMsgSetNotAvailable" ;
VAL_ 2365458686 EstimatedOrMeasuredAuxValveState 1 "EstOrMeasAuxValStatAvailable" 0 "EstOrMeasAuxValStatNotAvailable" ;
VAL_ 2365458686 HitchInfo_RearPosition 1 "HitchInfo_RearInPosAvailable" 0 "HitchInfo_RearInPosNotAvailable" ;
VAL_ 2365458686 HitchInfo_RearInWork 1 "HitchInfo_RearInWorkAvailable" 0 "HitchInfo_RearInWorkNotAvailable" ;
VAL_ 2365458686 PTOInfo_RearShaftSpeed 1 "PTOInfo_RearShaftSpdAvailable" 0 "PTOInfo_RearShaftSpdNotAvailable" ;
VAL_ 2365458686 PTOInfo_RearShaftEngagement 1 "PTOInfo_RearShaftEgtAvailable" 0 "PTOInfo_RearShaftEgtNotAvailable" ;
VAL_ 2365458686 Lighting_MinimalSet 1 "MinSetAvailable" 0 "MinSetNotAvailable" ;
VAL_ 2365458686 LanguageCmdStorageInTractorECU 1 "LangCmdAvailableInTractorECU" 0 "LangCmdNotAvailableInTractorECU" ;
VAL_ 2365458686 TractorClass 3 "NotAvailable" 2 "TECU_Class_3" 1 "TECU_Class_2" 0 "TECU_Class_1" ;
VAL_ 2365458686 PowerMgt_KeySwitch 1 "KeySwitchPwrMgtAvailable" 0 "KeySwitchPwrMgtNotAvailable" ;
VAL_ 2365458686 PowerMgt_MaxTimeTractorPower 1 "MaxTimeTractorPwrMgtAvailable" 0 "MaxTimeTractorPwrMgtNotAvailable" ;
VAL_ 2365458686 PowerMgt_MaintainPower 0 "MainPwrMgtNotAvailable" 1 "MainPwrMgtAvailable" ;
VAL_ 2365458686 SpeedInfo_WheelBasedSpeed 0 "WheelBasedSpeedInfoNotAvailable" 1 "WheelBasedSpeedInfoAvailable" ;
VAL_ 2365458686 SpeedInfo_GroundBasedSpeed 1 "GndBasedSpeedInfoAvailable" 0 "GndBasedSpeedInfoNotAvailable" ;
VAL_ 2365458686 SpeedInfo_EngineSpeed 1 "EngineSpeedInfoAvailable" 0 "EngineSpeedInfoNotAvailable" ;
VAL_ 2565865214 ManufacturerSpecific8 255 "NotAvailable" ;
VAL_ 2565865214 ManufacturerSpecific7 255 "NotAvailable" ;
VAL_ 2565865214 ManufacturerSpecific6 255 "NotAvailable" ;
VAL_ 2565865214 ManufacturerSpecific5 255 "NotAvailable" ;
VAL_ 2565865214 ManufacturerSpecific4 255 "NotAvailable" ;
VAL_ 2565865214 ManufacturerSpecific3 255 "NotAvailable" ;
VAL_ 2565865214 ManufacturerSpecific2 255 "NotAvailable" ;
VAL_ 2565865214 ManufacturerSpecific1 255 "NotAvailable" ;
VAL_ 2632777470 PGNumber 255 "NotAvailable" ;
VAL_ 2632777470 ConnectionAbortReason 8 "Duplicate sequence number" 1 "Already in one or more connection-managed sessions" 2 "System resources were needed for another task" 3 "Timeout occurred" 4 "CTS messages received when data transfer is in progress" 5 "Maximum retransmit request limit reached" 6 "Unexpected data transfer packet" 7 "Bad sequence number" ;
VAL_ 2632777470 ControlByte 16 "RTS" 17 "CTS" 19 "EoMA" 255 "Abort" 32 "BAM" ;
VAL_ 2565406462 ControlByte 0 "ACK" 1 "NACK" 2 "AccessDenied" 3 "CannotRespond" ;
VAL_ 2498232062 VTSelectInputObjectIsEdited 1 "ObjectIsOpenForEditing" 0 "ObjectIsNotEdited" ;
VAL_ 2498232062 OperatingState4 0 "NoInteractionDetected" 1 "InteractionDetected" ;
VAL_ 2498232062 OperatingState3 0 "ControlIsNotLocked" 1 "ControlIsLocked" ;
VAL_ 2498232062 WSVehicleSystem5 127 "Not Available" 0 "Ind. Process Control Stationary" ;
VAL_ 2498232062 WSVehicleSystem4 125 "Entertainment" 120 "Display" 85 "External Environment" 75 "Sensor Communication Interface" 35 "Electrical Generation" 100 "Deck, Cargo and Fishing Equipment" 90 "Internal Environment" 80 "Instrumentation/General Systems (deprecate)" 70 "Communications" 60 "Navigation" 50 "Propulsion" 40 "Steering and Control Surfaces" 30 "Electrical Distribution" 25 "Inter/Intranetwork Device" 20 "Safety Systems" 10 "System Tools" 127 "Not Available" 0 "Non-specific System" ;
VAL_ 2498232062 WSVehicleSystem3 8 "Grader" 7 "Four Wheel Drive Loader" 6 "Forklift" 5 "Excavator" 4 "Crawler" 3 "Backhoe" 2 "Articulated Dump Truck" 1 "Skid Steer Loader" 127 "Not Available" 0 "Non-specific System" ;
VAL_ 2498232062 WSVehicleSystem2 25 "Slurry Applicators" 24 "Utility Vehicles" 23 "Mulchers" 22 "Timber Processing Machines" 21 "Timber loaders" 20 "Forwarders" 19 "Timber Harvesters" 17 "Sensor Systems" 16 "Skidder" 15 "Earth Work" 14 "Special Crops" 13 "Powered Auxiliary Device" 12 "Farm Yard Operations" 11 "Transport/Trailer" 10 "Irrigation" 9 "Forage" 8 "Root Harvesters" 7 "Harvesters" 6 "Sprayers" 5 "Fertilizers" 4 "Planters/Seeders" 3 "Secondary Tillage" 2 "Tillage" 1 "Tractor" 127 "Not Available" 0 "Non-specific System" ;
VAL_ 2498232062 WSVehicleSystem1 2 "Trailer" 1 "Tractor" 127 "Not Available" 0 "Non-specific System" ;
VAL_ 2498232062 WSVehicleSystem 0 "Non-specific System" 127 "Not Available" ;
VAL_ 2498232062 WSManufacturerCode 1077 "Ymer Technology" 1076 "DOGA S.A." 1075 "Uniden America Corporation" 1074 "Kindhelm / Navigs Oy" 1073 "Manitou Equipment America LLC" 1072 "La Marche Manufacturing Company" 1071 "MACH SYSTEMS s.r.o." 1070 "Quick-teck Electronics Ltd" 1069 "Lithionics Battery LLC" 1068 "Zapi S.p.A." 1067 "Tecomec S.r.l." 1066 "Spot Zero Water" 1065 "CALYPSO Instruments" 1064 "Omnitech Robotics Inc." 1063 "SolSteer" 1062 "Marol Co Ltd" 1061 "Volvo Construction Equipment" 1060 "Scale-Tec" 1059 "Boatrax" 1058 "Bondioli & Pavesi SpA" 1057 "EquipmentShare" 1056 "Lithium Pros" 1055 "EXA Computing GmbH" 1054 "Schmotzer Hacktechnik GmbH & Co. KG" 1053 "Vetus Maxwell, Inc." 1052 "Pfreundt" 1051 "ProNav AS" 1050 "Spacenus GmbH" 1049 "S&S Cycle" 1048 "Agrivation UG" 1047 "Sonic Corporation" 1046 "Praxidyn" 1045 "CMR Group" 1044 "Xee" 1043 "Hyva" 1042 "engcon group" 1041 "EZ Lynk" 1040 "BPE Electronics Srl" 1039 "Liugong Dressta Machinery" 1038 "EMIT Technologies, Inc." 1037 "Dragonfly Energy Corp." 1036 "Bender GmbH & Co. KG" 1035 "Agres" 1034 "Siren Marine" 1033 "ECCO Safety Group" 1032 "SIMOL S.p.A." 1031 "Flintec UK Ltd." 1030 "Tume-Agri Oy" 1029 "The Marine Guardian LLC" 1028 "Autel Intelligent Technology Corp., Ltd" 1027 "Goldacres PTY LTD" 1026 "ZTR Control Systems, LLC" 1025 "eze System, Inc." 1024 "Inventus Power" 1023 "PEAK-System Technik GmbH" 1022 "ITC Inc" 1021 "Entratech Systems LLC" 1020 "Onyx Marine Automation s.r.l." 1019 "Codek Foundries" 1018 "Flex TTS" 1017 "Caldaro AB" 1016 "Röhren- und Pumpenwerk BAUER GmbH" 1015 "SECURITAG SAS" 1014 "Briri Maschinenbau GmbH" 1013 "Allochis E-Tec" 1012 "Rhodan Marine Systems of Florida LLC" 1011 "Soundmax Electronics Ltd" 1010 "Agricultural Industry Electronics Foundation e.V." 1009 "TouchTronics, Inc." 1008 "Lintest Systems LLC" 1007 "Maschinenfabrik Meyer-Lohne GmbH" 1006 "Proterra" 1005 "TSE Brakes, Inc." 1004 "Ultraflex SpA" 1003 "technotrans SE" 1002 "Kussmaul Electronics Co." 1001 "Cleral Inc." 1000 "Landmaschinen Wienhoff GmbH" 1569 "621 Technologies Inc." 999 "TerraTroniq B.V." 998 "Transcell Technology Inc" 997 "Xenta Systems Srl" 996 "Eniquest Pty Ltd" 995 "Circuitlink Pty Ltd." 994 "Morris Industries Ltd." 993 "Alelion Energy Systems AB" 992 "MarineIOT LLC" 991 "Deutronic Elektronik GmbH" 990 "SAMSUNG SDI Co., Ltd." 989 "Flux-Geräte GmbH" 988 "Voith Turbo" 987 "Baltic Car Equipment" 986 "AAMP Global" 985 "NLR, LLC" 984 "E-T-A Elektrotechnische Apparate GmbH" 983 "Dezwaef NV" 982 "Briggs & Stratton Corporation" 981 "Kobelt Manufacturing Co. Ltd" 980 "Gussi Italia S.R.L." 979 "McHale" 978 "Canfield Connector" 977 "Emerson Electric Co." 976 "Derive Systems, Inc." 975 "Siemens AG" 974 "Pico Technology Limited" 973 "Zasso GmbH" 972 "Axion AG" 971 "B+B Smartworx" 970 "Jaboni Power Products, LLC" 969 "Blue Sea Systems" 968 "Cox Powertrain Limited" 967 "Moteck Electric Corp." 966 "VisibleFarm" 965 "Ro-Sys Software" 964 "AgroVIR Kft" 963 "Thomason Jones Company, LLC" 962 "Timbolier Industries, Inc." 961 "POK SAS" 960 "Vemcon GmbH" 959 "Cascade Corporation" 958 "NHK MEC Corporation" 957 "Sierra Wireless Inc" 956 "Piher Sensors & Controls S.A." 955 "Hottinger Baldwin (Suzhou) Electronic Measurement Technology Co., Ltd." 954 "Setec Pty Ltd" 953 "Curtiss-Wright" 952 "Tan Delta Systems Ltd" 951 "Exor International S.p.A." 950 "RE:Lab s.r.l." 949 "Škoda Electric a.s." 948 "Donix" 947 "Gerd Bär GmbH" 946 "Hydac Tecnologia Ltda" 945 "Equalizer AG" 944 "ZONTISA Marine SL" 943 "FISCHER AG Präzisionspindeln" 942 "Vogelsang GmbH & Co. KG" 941 "Navya" 940 "Dometal Oy" 939 "Warn Industries, Inc." 938 "LEVEL Systems" 937 "Precision Circuits Inc" 936 "Hi-tech Millennium" 935 "Meels GmbH & Co. KG" 934 "Farmobile, Inc." 933 "Delta Mobile Systems, Inc." 932 "Discover Battery" 931 "Enertec Marine Ltd" 930 "Ecotronix Corp." 929 "Jl Marine Systems, Inc." 928 "EAO Automotive GmbH & Co. KG" 927 "Saicon" 926 "Buhler Industries Inc." 925 "GW Lisk Company" 924 "PAS Peschak Autonome Systeme GmbH" 923 "ELTEK S.p.A." 922 "Terberg Benschop B.V." 921 "ROPA Fahrzeug- und Maschinenbau GmbH" 920 "MTD Consumer Group Inc." 919 "Furrion LLC" 918 "AMW Machine Control, Inc" 917 "Sentinel d.o.o." 916 "Turck Inc." 915 "Dosificacion y sistemas electronicos S.L. (DSE)" 914 "ZETOR TRACTORS a.s." 913 "Toyota Motor Corporation" 912 "Steyr Motors GmbH" 911 "Nautic-On" 910 "Hermann Paus Maschinenfabrik GmbH" 909 "Marines Co., Ltd." 908 "Chonbuk National University Department of Electronics" 907 "strautmann" 906 "MOBA AG" 905 "ASA Electronics" 904 "Equipment Safety Systems Pty. Ltd. (EQSS)" 903 "InMotion" 902 "Bucher Hydraulics" 901 "Zivan Srl" 900 "OSB AG" 899 "Lippert Components, Inc" 898 "Josef Kotte Landtechnik GmbH & Co. KG" 897 "Dot Technology Corp." 896 "NextFour Solutions Ltd" 895 "Peloton Technology" 894 "Rhodan Marine Systems of Florida LLC" 893 "KlinkTechnics Ltd." 892 "Mectronx Corp" 891 "CarrierWeb" 890 "L3 Technologies, Inc." 889 "SANY America Inc" 888 "Carma Systems Inc" 887 "Hyperdrive Innovation Limited" 886 "Hitachi Zosen Corporation" 885 "SICK Stegmann GmbH" 884 "Sure Grip Controls Inc." 883 "Swift Navigation, Inc." 882 "BHTronik GmbH & Co. KG" 881 "Sovema" 880 "Revision Military" 879 "PG Trionic, Inc." 878 "FOTON" 877 "SICK ATech GmbH" 876 "SUCO Robert Scheuffele GmbH & Co. KG" 875 "Salvarani S.r.l." 874 "MTA S.p.A." 873 "Garnet Instruments Ltd." 872 "Kählig Antriebstechnik GmbH" 871 "Superior Tech Inc" 870 "Textron Fleet Management" 869 "Intercomp" 868 "Data Panel Corp" 867 "Skeleton Technologies" 866 "Netradyne, Inc." 865 "MyEasyFarm" 864 "Streamline Transportation Technologies Inc." 863 "SMAG" 862 "Prospec Electronics" 861 "Adel System S.r.l." 860 "Michelin" 859 "Valor" 858 "Littelfuse" 857 "Zoomlion Heavy Industry NA, Inc" 856 "FarmFacts GmbH" 855 "Toshiba Infrastructure Systems & Solutions Corporation" 854 "GEMAC Chemnitz GmbH" 853 "Teledyne RESON B.V." 852 "Velvac Inc" 851 "Novotechnik Messwertaufnehmer OHG" 850 "Geoprospectors GmbH" 849 "MTS Maschinentechnik Schrode AG" 848 "ningupex" 847 "Oceanvolt" 846 "L3 Magnet-Motor" 845 "GMB Güstrower Maschinenbau GmbH" 844 "FELL AS" 843 "Hendrickson Truck Commercial Vehicle Systems" 842 "DigiDevice Srl" 841 "Agra-GPS" 840 "E.S.T.E. Srl" 839 "Indexator Rotator Systems AB" 838 "Teamsurv Ltd" 837 "Famic Technologies Inc." 836 "Signature4" 835 "PetTrack Ltd." 834 "Pioneer Microsystems, Inc." 833 "Electrum Automation AB" 832 "Heizomat Gerätebau-Energiesysteme GmbH" 831 "DOK-ING Ltd." 830 "Ultra Motion LLC" 829 "Drov Technologies, Inc." 828 "AgriBrink Inc." 827 "INmatix Technology Group Ltd" 826 "Lewmar Marine Inc" 825 "BPW Hungária" 824 "Undheim Systems AS" 823 "ACEINNA, Inc (formerly MEMSIC, Inc)" 822 "Bren-Tronics, Inc." 821 "Thorsen Teknik A/S" 820 "DIaLOGIKa Gesellschaft fuer angewandte Informatik mbH" 819 "Preco Electronics" 818 "HGNSS" 817 "TE Connectivity Sensor Solutions" 816 "UniStrong" 815 "FLIR Systems, Inc." 814 "Kronotech Srl (formerly Soltec Soluzioni Tecnologiche Srl)" 813 "Thales Suisse SA" 812 "Torch Technologies" 811 "Blue Water Desalination" 810 "Dutch Power Company" 809 "HMS Industrial Networks AB" 808 "RIMEX Supply Ltd." 807 "Schneider-Electric" 806 "Charge Automotive Ltd" 805 "Gundersen & Løken AS" 804 "ASA Electronics" 803 "Gill Sensors & Controls Limited" 802 "SPBI (Bj Technologie)" 801 "LOR Manufacturing Company Inc." 800 "Delta-Q Technologies" 799 "Stillwater Designs and Audio, Inc. - KICKER" 798 "Lumishore Ltd" 797 "Tides Marine" 796 "Canadian Automotive Industries Ltd" 795 "Broyda Enterprises Pty Ltd" 794 "Shihlin Electric & Engineering Corporation" 793 "James Fisher Prolec" 792 "Kostal Mexicana" 791 "AUTEC" 790 "VACALL" 789 "GRADALL" 788 "MoTeC Pty Ltd" 787 "Abertax Technologies Limited" 1863 "Thomas G. Faria Co." 1862 "Sanshin" 1861 "Vector North America" 1860 "MMP" 1859 "Kvasar AB" 1858 "Litton" 1857 "Simrad" 1856 "Trimble" 1855 "Furuno USA" 1854 "Northstar Technologies" 1853 "Japan Radio Co" 1852 "Navionics" 1851 "RayMarine" 1850 "Seastar Solutions (formerly Teleflex)" 786 "Johnson Matthey Battery Systems" 785 "Fischer Panda GmbH" 784 "CM Automotive Systems, Inc." 783 "Loup Electronics Inc." 782 "AVR bv (formerly AVR bvba)" 781 "Poly-Planar LLC" 780 "AVID Technology Ltd" 779 "RLC Electronic Systems" 778 "Seakeeper Inc." 777 "Ocean Signal Ltd" 776 "HMI Systems LLC" 775 "ZIEHL-ABEGG Automotive GmbH" 774 "Taisho Corporation" 773 "Clarion Corporation of America" 772 "Blink Marine" 771 "Shaw Development, LLC" 770 "MONOSEM" 769 "Trombetta" 768 "Flores Automation, LLC" 767 "Alliance Wireless Technologies Inc." 766 "Epec Oy" 765 "GIGAVAC" 764 "Bednar FMT s.r.o." 763 "AT-Systems BVBA" 762 "ROJ s.r.l." 761 "MITA OLEODINAMICA S.p.A." 760 "Bernecker + Rainer Industrie Elektronik GmbH" 759 "Hydro-Gear" 758 "Banner Engineering Corp." 757 "IMPCO Technologies" 756 "Maschio Gaspardo S.P.A." 755 "Firefly Integrations" 754 "Parker Hannifin Corp., Automation Group" 753 "AIROD Technologies" 752 "Deep Sea Electronics Plc" 751 "Pacific Track" 750 "Joskin SA" 749 "Chart Inc." 748 "ISOTTA" 747 "Agratronix" 746 "SureFire Ag Systems, Inc." 745 "Cidra Corporate Services Inc." 744 "Woosung Engineering Co., Ltd." 743 "Daemyung Elevator Co., Ltd." 742 "EROAD" 741 "Carling Technologies" 740 "e-Traction" 739 "LXNAV d.o.o." 738 "Blue Ink Technologies" 737 "Balluff GmbH" 736 "Terex Aerial Work Platforms - Genie" 735 "AEM Performance Electronics" 734 "REAPsystems" 733 "Intendia S.L." 732 "Gefran S.p.A." 731 "Modine Manufacturing Company" 730 "BERTHOUD AGRICOLE" 729 "Liebherr" 728 "Streumaster (formerly Streumaster / Panien)" 727 "Dhoot Transmission Pvt Ltd." 726 "MIDORI PRECISIONS" 725 "Hitachi Construction Machinery Co., Ltd." 724 "Electronic Applications, Inc." 723 "Jabil Inc." 722 "Contelec AG" 721 "Hypro" 720 "WITZ Corporation" 719 "Cojali S. L." 718 "Micronet Inc" 717 "Yacht Devices Ltd" 716 "Eaton Control & Power Conversion Division (CPCD)" 715 "Autonnic Research Ltd" 714 "Kobashi Kogyo Co., Ltd." 713 "US Hybrid Corporation" 712 "LOR Manufacturing Company Inc." 711 "DAS Co., LTD" 710 "Greentronics Ltd." 709 "Marquardt GmbH" 708 "Lars Thrane A/S" 707 "Rochester Gauges Inc" 706 "Shanghai Diesel Engine Corporation Limited" 705 "SVAB Hydraulik AB" 704 "JL Audio, Inc." 703 "Hydro Tab Marine Engineering" 702 "Weichai Power Co., Ltd." 701 "BigRoad Inc." 700 "K-Tec Earthmovers Inc." 699 "Harman International Industries" 698 "Scorpion Technologies Ltd." 697 "Ålö AB" 696 "DRS Network & Imaging Systems, LLC (DRS Technologies)" 695 "Weldon Technologies" 694 "GasTOPS Ltd." 693 "Agility Fuel Solutions (formerly Agility Fuel Systems)" 692 "Tanhay Corporation" 691 "Digitroll Agricultural Electronics" 690 "LINAK A/S" 689 "Aarcomm Systems Inc" 688 "Rockford Corp" 687 "Flight Systems, Inc." 686 "Taigene Electric Machinery Corp." 685 "ANEDO (formerly ANEDO Ltd.)" 684 "KEB" 683 "Fosen Elektro" 682 "Eckelmann AG" 681 "BEDIA Motorentechnik GmbH & Co. KG" 680 "AMVAC Chemical Corporation" 679 "Cimco Marine AB" 678 "KeepTruckin, Inc." 677 "DSA Daten- und Systemtechnik GmbH" 676 "Danfoss IXA A/S" 675 "Kawasaki Motors Corp., USA" 674 "Yara International ASA" 673 "Caruelle Nicolas" 672 "OPTIMA Concept" 671 "Innovative Controls Inc." 670 "STEMCO LP" 669 "Quantum Fuel Systems Technologies Worldwide, Inc" 668 "MacDon Industries Ltd." 667 "Bartec" 666 "Schaeffler Technologies AG & Co., KG" 665 "Gebr. Bode GmbH & Co. KG" 664 "Level Developments Ltd" 663 "Delta Systems, Inc" 662 "Kissling Elektrotechnik GmbH" 661 "SPAL Automotive S.r.l." 660 "Auto-Gaz Centrum" 659 "Data Panel Corp." 658 "Shenzhen Jiuzhou Himunication Technology Co., Ltd" 657 "Terzo Power Systems" 656 "PRO SOLUS do Brasil" 655 "Genge & Thoma AG" 654 "Kohler Power Systems, Detroit Engine Development Center (DEDC)" 653 "AEV, spol. s r. o." 652 "MicroControl GmbH & Co. KG" 651 "Takakita Co, Ltd." 650 "Seiko Epson Corp." 649 "Control-Q B.V." 648 "OJSC Ekran" 647 "Siloking" 646 "Veenhuis Machines B.V." 645 "esd electronic system design gmbh" 644 "KUS USA" 643 "Bogballe A/S" 642 "Moog / Aspen Motion Technologies" 641 "Diverse Yacht Services" 640 "Power Solutions International" 639 "Startec s.r.l." 638 "KVH Industries, Inc." 637 "Bavaria Yachtbau GmbH" 636 "Divelbiss Corporation" 635 "Argo Tractors S.p.A." 634 "Rocky Research" 633 "TORC Robotics" 632 "Pepperl+Fuchs GmbH" 631 "Reltima" 630 "SmartDrive Systems Inc." 629 "Agri Info Design, Ltd." 524 "Vomax Instrumentation Pty. Ltd." 523 "Reggio Emilia Innovazione" 522 "Nebraska Tractor Test Laboratory" 521 "Clever Devices Ltd." 520 "Trapeze" 519 "Peeters Landbouwmachines b.v." 518 "Transas USA Inc." 517 "Noland Engineering" 516 "AVAT Automation GmbH" 515 "GINAF Trucks Nederland B.V." 514 "DISTek Integration, Inc." 513 "Precision Technology (Formerly FarmscanAg)" 512 "Inpower LLC" 511 "Sulky" 510 "Marinesoft Co. Ltd" 509 "MOTORTECH GmbH" 508 "Transtech Innovations" 507 "ISOBUS Test Center" 506 "IHI STAR Machinery Corporation" 505 "Yetter Farm Equipment" 504 "Vesper Marine" 503 "Naviop S.R.L." 502 "Attwood Corporation" 501 "Agrotronix S.A." 500 "Oxbo International Corporation" 499 "LCJ Capteurs" 498 "Innovative Design Solutions, Inc." 497 "SENTRON Sistemas Embarcados" 496 "W. Gessmann GmbH" 495 "HOLMER Maschinenbau GmbH" 494 "Synerject" 493 "Watcheye" 492 "Inergy Automotive Systems" 491 "Penny and Giles Ltd" 490 "QuikQ" 489 "Appareo Systems, LLC" 488 "The Charles Machine Works, Inc." 487 "DSE Test Solutions A/S" 486 "Westport Innovations Inc." 485 "MATT automotive" 484 "Headsight Inc." 483 "Valeo" 482 "Tricon Electronics" 481 "Chetco Digital Instruments" 480 "EnerDel, Inc." 479 "Vapor Bus International" 478 "OceanSat B.V." 477 "OilQuick AB" 476 "Hummingbird Marine Electronics" 475 "GME" 474 "Persen Technologies Inc." 473 "Boss Industries, Inc." 472 "Tenneco Inc." 471 "Sea Cross Marine AB" 628 "Falck Schmidt Defence Systems" 627 "Radio Ocean" 626 "AVL DiTEST GmbH" 625 "Global MRV Inc." 624 "Blackbox Machine Control Pty Ltd" 623 "Xirgo Technologies" 622 "Floyd Bell Inc" 621 "Hagie Manufacturing Company" 620 "Sevcon Ltd." 619 "Right Weigh Load Scales" 618 "Evrard SA" 617 "Zero Emission Vehicles" 616 "SMART-TEC s.r.o." 615 "Networkfleet, Verizon Telematics" 614 "ARLT Technologies GmbH" 613 "HKS Co., Ltd." 612 "Samwon IT" 611 "Esterline" 610 "Trail Tech" 609 "Walvoil S.p.A." 608 "Gale Banks Engineering" 607 "Knappco/Civacon" 606 "Intellian Technologies" 605 "Aventics GmbH" 604 "Indexator Rototilt Systems AB" 603 "Kereval" 602 "Nomad Digital Ltd." 601 "Navitas Systems" 600 "Aquatic AV" 599 "Spudnik Equipment Co, LLC" 598 "ABB Turbo Systems Ltd" 597 "Hydac Filter Systems GmbH" 596 "Brunelco Electronic Innovators B.V." 595 "CustomWare" 594 "Kongsberg Automotive" 593 "Sensata Technologies" 592 "tecsis GmbH" 591 "United States Coast Guard" 590 "ARGO-HYTOS GMBH" 589 "MICO, Inc." 588 "Vignal Systems" 587 "JCA Electronics" 586 "Suzuki Motor Corp" 585 "Industrial Electronic Controls" 584 "CarMedialab GmbH" 583 "Yachtcontrol" 582 "Innovative Software Engineering" 581 "Väderstad - Verken AB" 580 "San Jose Technology, Inc." 579 "KVH Industries, Inc." 578 "advanSea" 577 "Denchi Power Ltd  (formerly ABSL Power Solutions Limited)" 576 "Vectia" 575 "Lytx" 574 "Vishay Precision Group" 573 "Orolia Ltd" 572 "Fasse Valves" 571 "Marinecraft Co., Ltd." 570 "frenzel + berg electronic GmbH & Co. KG" 569 "LORD MicroStrain Sensing Systems" 568 "Makersan Ltd. Co." 567 "Lithiumstart LLC" 566 "Geode Technology, Inc." 565 "Micro-Trak Systems, Inc." 564 "Auto Power Electronic" 563 "LOHR Sistemas Eletronicos LTDA" 562 "Bombardier Transportation GmbH" 561 "b-plus GmbH" 560 "Iowa State University, Agricultural and Biosystems Engineering" 559 "Four Peaks Navigation" 558 "Davis Instruments Corp." 557 "Rockson Automation GmbH" 556 "Doosan Infracore Norway" 555 "Sasaki Corporation" 554 "iris-GmbH infrared & intelligent sensors" 553 "KIB Electronics" 552 "Matsuyama Plow Mfg Co, Ltd" 551 "Wexler CSD Ltd." 550 "SUN-A Corporation" 549 "ROAD Deutschland GmbH" 548 "TM4 Inc." 547 "Thomson Linear LLC" 546 "Maruyama Mfg Co, Inc." 545 "GS Hydraulics" 544 "Au Group Electronics" 543 "BAUER Maschinen GmbH" 542 "Dinamica Generale s.p.a." 541 "Total Fire Systems, Inc." 540 "Dinex A/S" 539 "Mobileview" 538 "Crop Ventures, Inc." 537 "Schrader Electronics Ltd." 536 "SSI Technologies" 535 "MOTORPAL, a.s." 534 "Webasto Thermo & Comfort SE" 533 "Doran Manufacturing, LLC" 532 "Onwa Marine Electronics Co Ltd." 531 "Genge & Thoma AG" 530 "NMEA" 529 "National Instruments Korea" 528 "Hoganas AB, Electric Drive Systems" 527 "GKN Walterscheid GmbH" 526 "LOFA Industries, Inc" 525 "Rust Sales INC" 470 "SI-TEX Marine Electronics" 469 "RA Consulting GmbH" 468 "Tyco Fire Protection Products" 467 "Lely Industries N.V." 466 "Veethree Electronics and Marine LLC" 465 "Ashcroft Inc" 464 "Leach International Corporation" 463 "PROBOTIQ" 462 "IHI Shibaura Machinery Corporation" 461 "HAWE Hydraulik SE" 460 "San Giorgio S.E.I.N." 459 "Alltek Marine Electronics Corp" 458 "Control Solutions, Inc." 457 "RUSELPROM-ElectricDrive Ltd" 456 "General Kinetics" 455 "ADZ NAGANO GmbH" 454 "NGK Spark Plug Co. Ltd" 453 "Cooper Bussmann" 452 "WIKA Alexander Wiegand SE & Co. KG" 451 "Parker Hannifin Corp" 450 "Dycor Technologies Ltd." 449 "Polaris Industries Inc" 448 "Stanadyne Corporation, Electronics Systems" 447 "Great Plains Mfg." 446 "CertTech, L.L.C." 445 "KAT MECHATRONIC, Electronic Product Division" 444 "ITT Power Solutions" 443 "SignalQuest, Inc." 442 "Horsch Maschinen GmbH" 441 "PTG Reifendruckregelsysteme GmbH" 440 "Cummins Power Generation" 439 "Hyundai Heavy Industries" 438 "Comar Systems Ltd" 437 "Digital Yacht Limited" 436 "Kinze Manufacturing" 435 "Zunhammer GmbH" 434 "Stored Energy Systems" 433 "Rowe Electronics" 432 "S&A Systems, Inc." 431 "Tohatsu Corporation" 430 "Auteq Telematica S.A." 429 "Rota Engineering Ltd." 425 "Methode Electronics Inc, MDI" 424 "Odyne LLC" 423 "BSM Wireless, Inc." 422 "True Heading AB" 421 "Vertex Standard Co, Ltd" 420 "Vermeer Corporation, ACS Group" 419 "Fusion Electronics Ltd" 418 "Intellistick Inc" 417 "KZValve" 416 "Kubota Corporation" 415 "Valid Manufacturing Ltd." 414 "Cattron Group International" 413 "Datapross Nijbroek bv" 412 "WebTech Wireless Inc." 411 "Hy-Drive Technologies Ltd." 410 "COBO S.p.A. Divisione 3B6" 409 "Transfluid S.r.L." 408 "Corvus Energy Ltd." 407 "Comtech Mobile Datacom" 406 "Vecima Networks Inc." 405 "Wema System AS" 404 "Com Nav Marine Ltd" 403 "Trackwell ADS, Inc." 402 "Simma Software, Inc." 401 "Torqeedo GmbH" 400 "Livorsi Marine" 399 "ISEKI & Co., Ltd." 398 "Hilite International" 397 "Sanyo-kiki Co Ltd." 396 "Beyond Measure" 395 "GENTEC S.R.L." 394 "Capi 2 Nederland B.V." 393 "Harvest Tec, Inc" 392 "Tianyuan Technology Co Ltd." 391 "Electronic Design for Industry, Inc" 390 "Partech Inc." 389 "Benchmark Electronics, Minnesota Division" 388 "Innomatix, LLC" 387 "Orscheln Products, LLC" 386 "JLG Automation BVBA" 385 "Johnson Outdoor Marine Electronics" 384 "Camano Light" 383 "MCL Industries" 382 "National Agriculture and Food Research Organization" 381 "B & G" 380 "Suntech International Ltd." 379 "Yamabiko Corporation" 378 "Glendinning Marine Products" 377 "ifm electronic gmbh" 376 "Quake Global" 375 "Williams Controls Inc." 374 "Northern Lights, Inc." 373 "Electronic Design Inc." 372 "Delphi" 371 "Heinzmann GmbH & Co. KG" 370 "Rolls-Royce Marine AS" 369 "Power Torque Engineering Ltd" 368 "HANSENHOF_electronic" 367 "Fliegl Agrartechnik" 366 "Viewnyx Corp." 365 "Digi-Star, LLC" 364 "OEM Controls Inc." 363 "BEI Duncan" 362 "Poettinger Landtechnik GmbH (formerly Alois Poettinger Maschinenfabrik GmbH)" 361 "InMach" 360 "HJS Emission Technology GmbH & Co KG   (formerly HJS Fahrzeugtechnik GmbH & Co KG)" 359 "Ludwig Bergmann GmbH" 358 "Victron Energy B.V." 357 "Hardi International A/S" 356 "Fischer Panda Generators, Inc" 355 "Mastervolt International B.V." 354 "Junkkari OY" 353 "Hegemon Electronics, Inc." 352 "SAME DEUTZ-FAHR GROUP S.p.A." 351 "Thrane & Thrane" 350 "Noris Marine Systems GmbH & Co KG" 349 "Suonentieto" 348 "Amazonen Werke H. Dreyer" 347 "Honeywell" 346 "Control Solutions" 345 "Korean Maritime University" 344 "Parvus Corporation" 343 "Baumer Group" 342 "THOMAS MAGNETE GmbH" 341 "Boning GmbH & Co" 340 "Continental AG" 339 "Competence Center ISOBUS e.V." 338 "GRAF-SYTECO" 337 "Carraro S.p.A." 336 "APE s.r.o." 335 "Evo Electric Ltd" 334 "Takata-Petri AG" 333 "Hadley Products Corporation" 332 "HWH Corporation" 331 "Horton, Inc." 330 "Kidde Aerospace and Defense" 329 "Deif A/S" 328 "Qwerty Electronik AB" 327 "Sonceboz SA" 326 "Akron Brass Company" 325 "ASM Automation Sensorik Messtechnik GmbH" 324 "Snap-on Diagnostics" 323 "Mobileye Vision Technologies Ltd." 322 "MICHENKA s.r.o." 321 "Ultra Electronics, Electrics" 320 "Miedema Landbouwwerktuigenfabriek B.V." 319 "Cadec Global" 318 "SAT Plan" 317 "Navtronics Bvba" 263 "IMMI" 262 "HydraForce, Inc" 261 "Red Dot Corporation" 260 "Reichhardt GmbH Steuerungstechnik" 259 "Jetter AG" 258 "ARAG" 257 "Honda Motor Co., Ltd" 256 "Tyco Electronics AMP" 255 "MEAS France" 254 "GE Sensing" 253 "Mobile Control Systems" 252 "Sensor-Technik Wiedemann GmbH" 251 "German Agricultural Society, Test Center (DLG)" 250 "Kuhn Group" 249 "Schaltbau GmbH" 248 "Cooper Standard Automotive Active Systems Group" 247 "ePULSE" 246 "Class 1, Inc" 245 "Capstan Ag Systems, Inc." 244 "Techno-Matic" 243 "eRide, Inc." 242 "Kokusandenki Co. Ltd" 241 "Schneider Automation SAS" 240 "Vanair Mfg" 239 "May & Scofield Ltd" 238 "ZF Friedrichshafen AG" 237 "Agtron Enterprises Inc" 236 "NORAC Systems International Inc" 235 "SailorMade Marine Telemetry - Tetra Technology Ltd." 234 "Mondial electronic GmbH" 233 "Yacht Monitoring Solutions Inc." 232 "TSD Integrated Controls" 231 "Topcon Positioning Systems, Inc." 230 "Saucon Technologies" 229 "Garmin International Inc." 228 "Unused (formerly ZF Marine Electronics)" 227 "Lykketronic A/S" 226 "Monaco Coach Corporation" 225 "SKF" 224 "EMMI Network, S.L." 223 "Vaueo Retarder Co., Ltd." 222 "Generac Power Systems, Inc." 221 "SiE" 220 "Beede Electrical Instrument Company, Inc" 219 "Cat OEM Solutions" 218 "Gits Manufacturing Company" 217 "RM Michaelides Software & Elektronik GmbH" 216 "Paneltronics Inc." 215 "Aetna Engineering/Fireboy-Xintex" 214 "MC elettronica Srl" 164 "MTU Friedrichshafen GmbH (formerly DaimlerChrysler Off-Highway)" 163 "BRP Inc." 162 "Axiomatic Technologies" 161 "Offshore Systems (UK) Ltd" 160 "Nido" 159 "NTech Industries Inc" 158 "Firestone Industrial Products Company" 157 "ISSPRO Inc." 156 "ITT Industries - Cannon" 155 "Vetronix Corporation" 154 "Westerbeke Corporation" 153 "Woodward, Industrial Controls Division" 152 "elobau GmbH & Co. KG" 151 "Raven Industries, Inc." 150 "Fleetguard" 149 "Holset" 148 "Blue Water Data, Inc." 147 "Nautibus electronic GmbH" 146 "Maxima Technologies" 145 "MurCal Controls" 144 "Mercury Marine" 143 "W. Gmeiner GmbH & Co." 142 "TRW Automotive (Commercial Steering Systems)" 141 "Thales Navigation Ltd." 140 "Lowrance Electronics, Inc." 139 "Caterpillar Trimble Control Technologies (CTCT), LLC" 138 "Georg Fritzmeier GmbH & Co. KG" 137 "Maretron" 136 "Komatsu Ltd" 135 "Airmar Technology Corporation" 134 "Iris Technology Ltd" 133 "Bucher Schoerling GmbH" 132 "Mulag-Fahrzeugwerk" 131 "ITT Industries" 130 "Nido - Universal Machines B.V." 129 "OMNEX Control Systems Inc." 128 "Gerhard Duecker GmbH & Co. KG" 127 "Holland USA" 126 "Driver Tech" 125 "Nevada Automotive Test Center" 124 "Hydac Electronic" 123 "Basler Electric" 122 "FG Wilson (Engineering) Limited" 121 "HED (Hydro Electronic Devices, Inc.)" 120 "RDS Technology Ltd" 119 "IntegriNautics  " 118 "Intron GmbH" 117 "HUSCO International" 116 "BEELINE Technologies" 115 "NACCO Materials Handling Group, Inc." 114 "EControls, Inc." 113 "Stress-Tek, Inc." 112 "MECALAC" 111 "Bernard Krone Holding SE & Co. KG (formerly Maschinenfabrik Bernard Krone GmbH)" 110 "EPIQ Sensor-Nite" 109 "TeeJet Technologies Denmark (formerly LH Technologies ApS)" 108 "WTK-Elecktronik GmbH" 107 "Grimme Landmaschinen GmbH & Co. KG" 106 "BAE Systems Controls, Inc." 105 "Kiepe Elektrik GmbH & Co. KG" 104 "CLAAS KGaA mbH (formerly CLAAS Selbstfahrende Erntemaschinen GmbH)" 103 "CLAAS E-Systems GmbH (formerly CLAAS E-Systems KGaA mbH & Co. KG)" 102 "AGCO (formerly AGCO GmbH & Co.)" 101 "Sensoria" 100 "VDO Technik AG" 99 "International Transmissions Ltd (ITL)" 98 "Mueller-Elektronik GmbH & Co" 97 "Ag Leader Technology, Inc." 96 "Mech@tronic IT GmbH" 95 "Pacific Insight Electronics Corp." 94 "CNH Industrial N.V. (formerly CNH Global N.V.)" 93 "Perkins Engines Company Ltd." 92 "Ag-Chem Equipment Co., Inc." 91 "BSG Bodensee Steuergeraete GmbH" 90 "Knorr-Bremse SfN GmbH" 89 "Kverneland Group, Electronics Division" 88 "Hemisphere GPS Inc (formerly Satloc Precision GPS)" 87 "J.C. Bamford Excavators Ltd (JCB)" 86 "C. E. Niehoff & Company" 85 "Kohler Co" 84 "New Holland UK Limited" 83 "Bendix VORAD Technologies (formerly Eaton VORAD Technologies)" 82 "Bobcat/Ingersoll-Rand (formerly Melroe/Ingersoll-Rand)" 81 "Fire Research Corp." 80 "Twin Disc, Inc." 79 "Daimler Benz AG - Engine Division (PBM)" 78 "Frank W. Murphy Manufacturing, Inc" 77 "Deere Power Systems Group" 76 "unused (formerly Deere & Co, Construction Division)" 75 "Deere & Co, Agricultural Division" 74 "Eaton Axle-Brake Division" 73 "LeTourneau, Inc." 72 "Sisu Corporation" 71 "Vansco Electronics Ltd." 70 "Flex-coil Limited" 69 "Trimble Navigation" 316 "ITT Flow Control" 315 "Icom Incorporated" 314 "CSM GmbH" 313 "Ilmor Engineering, Inc." 312 "Lectronix, Inc." 311 "Patrick Power Products" 310 "TECNORD srl" 309 "Krauss-Maffei Wegmann GmbH & Co. KG" 308 "Cyntrx" 307 "MAS Technologies" 306 "Sleipner Motor AB" 305 "NovAtel Inc" 304 "EmpirBus AB" 303 "CTS Corporation" 302 "Nissin Kogyo Co., LTD" 301 "Parker Hannifin (UK) Ltd FDE group" 300 "Systron Donner Automotive" 299 "Rauch" 298 "Holley Performance" 297 "Zonar Systems Inc" 296 "micro dynamics GmbH" 295 "BEP Marine" 294 "Grayhill Inc." 293 "Spyder Controls Corp." 292 "IKUSI - Angel Iglesias S.A." 291 "Groeneveld Transport Efficiency BV" 290 "Kuebler GmbH" 289 "Watlow" 288 "Mitsubishi FUSO Truck & Bus Corp." 287 "NTech Industries, Inc" 286 "Coelmo srl" 285 "Sea Recovery Corp" 284 "Mobile Tech Chile" 283 "CWF Hamilton & Co Ltd" 282 "Medallion Instrumentation Systems" 281 "Precision Governors LLC" 280 "Leica Geosystems Pty Ltd" 279 "Geometris LP" 278 "Takata Electronics" 277 "LHP Telematics" 276 "Aqua-Hot Heating Systems" 275 "Navico Egersund AS" 274 "LTW Technology Co., LTD" 273 "Active Research Limited" 272 "Gross Mechanical Laboratories, Inc" 271 "Cole Hersee" 270 "Tennant" 269 "Saft America Inc.,  Space & Defense Division" 268 "Accurate Technologies" 267 "Red Lion Controls, Inc" 266 "International Thermal Research Ltd" 265 "MTS Sensor Technologie GmbH" 264 "Autolync" 213 "CNH Belgium N.V." 212 "Sure Power Industries, Inc" 211 "DNA Group" 210 "Iteris, Inc." 209 "Bell Equip. Co. SA (PTY) LTD" 208 "Drew Technologies, Inc" 207 "Otto Engineering" 206 "port GmbH" 205 "SmarTire Systems Inc" 204 "The Morey Corporation" 203 "MILtronik GmbH" 202 "Curtis Instruments, Inc" 201 "Disenos y Tecnologia S.A." 200 "MGM Brakes" 199 "ACTIA Group (formerly Actia Corp)" 198 "Mystic Valley Communications" 197 "Mechron Power Systems" 196 "LEMKEN GmbH & Co KG" 195 "General Engine Products" 194 "TriMark Corporation" 193 "Jeppesen Marine" 192 "Floscan" 191 "XRS Corporation (formerly XATA Corporation)" 190 "Hella KGaA Hueck & Co" 189 "QUALCOMM" 188 "EMP Corp" 187 "Air-Weigh" 186 "Altronic, Inc" 185 "Beede Electrical Instrument Company" 184 "EIA Electronics" 183 "KDS Controls, Inc" 182 "Vehicle Systems Engineering B.V." 181 "Coretronics, Inc." 180 "Smart Power Systems" 179 "TeeJet Technologies Springfield (formerly Midwest Technologies Illinois, LLC)" 178 "Continental Automotive GmbH (formerly Siemens VDO Automotive AG)" 177 "Diagnostic Systems Associates" 176 "Moritz Aerospace" 175 "Veris Technologies, Inc." 174 "AB Volvo Penta" 173 "Ryeso, Inc." 172 "Yanmar Co., Ltd. (formerly Yanmar Marine USA)" 171 "Topcon Electronics GmbH & Co. KG (formerly Wachendorff Elektronik GmbH & Co. KG)" 170 "Computronics Corporation Ltd." 169 "Marlin Technologies Inc." 168 "Xantrex" 167 "JLG Industries Inc" 166 "John Deere Electronic Solutions (formerly Phoenix International)" 165 "CPAC Systems AB" 68 "Scania" 67 "John Deere Coffeyville Works (formerly Funk Manufacturing Company)" 66 "John Deere Construction Equipment Division" 65 "MAN Nutzfahrzeuge AG" 64 "Unused (formerly SpectraPrecision Laserplane, then SpectraPhysics)" 63 "ZF Industries Inc." 62 "Wabco" 61 "Volvo Truck Corp." 60 "Volvo Trucks North America Inc." 59 "VES Inc." 58 "SPX Corporation, OTC Div" 57 "Danfoss  (formerly Sauer Sundstrand Co, then Sauer-Danfoss Co)" 56 "SAIC" 55 "Ryder System Inc." 54 "Meritor Wabco" 53 "Continental Automotive Systems US, Inc. (formerly Rockwell Land Transportation)" 52 "Meritor Automotive, Inc. (formerly Rockwell Automotive)" 51 "Robert Bosch GmbH" 50 "Robert Bosch Corp" 49 "RE America Inc." 48 "Pollak Alphabet" 47 "Phillips Semiconductor" 46 "Noregon Systems, Inc  (formerly Parasoft Computing Solutions)" 45 "PACCAR" 44 "Nippondenso Co. Ltd." 43 "International Truck and Engine Corporation - Vehicle Electronics (formerly Navistar Intl Trans Corp.)" 42 "International Truck and Engine Corporation - Engine Electronics  (formerly Navistar Intl Trans Co., Engine Electronics)" 41 "Motorola Inc." 40 "Motorola AIEG Inc." 39 "Microfirm Inc." 38 "Micro Processor Systems Inc." 37 "Mack Trucks Inc." 36 "Lucas Ind." 35 "Kenworth Truck Co." 34 "Kelsey Hayes Co." 33 "John Deere" 32 "Jacobs Vehicle Systems" 31 "J Pollak Corp" 30 "Isuzu Motors Ltd" 29 "Hino Motors Ltd." 28 "Grote Ind. Inc." 27 "GMC" 26 "General Motors Corp, Service Technology Grp" 25 "Daimler Trucks North America LLC (formerly Freightliner LLC)" 24 "Ford Motor Co., Vehicle Controls" 23 "Ford Motor Co., Heavy Truck" 22 "Ford Motor Co., Electronic Concepts & Systems" 21 "Echlin Inc., Midland Brake Inc." 20 "Eaton Ltd" 19 "Eaton Corp. Trucking Info Services" 18 "Eaton Corp, Transmission Div." 17 "Eaton Corp, Corp Res & Dev" 16 "Eaton Corp" 15 "DICKEY-john Corporation" 14 "Detroit Diesel Corporation" 13 "Delco Electronics" 12 "Deere & Company, Precision Farming" 11 "Dearborn Group Inc." 10 "Cummins Inc (formerly Cummins Engine Co)" 9 "Chrysler Corp." 8 "Caterpillar Inc." 7 "Case Corp." 6 "Berifors Electronics AB" 5 "AMP Inc." 4 "Ametek-Dixson" 3 "Ametek, US Gauge Division" 2 "Allison Transmission, Inc." 1 "Bendix Commercial Vehicle Systems LLC (formerly Allied Signal Inc.)" 0 "Reserved" ;
VAL_ 2498232062 WSIndustryGroup 7 "Reserved for SAE" 5 "IndustrialProcessCtrlStationary" 4 "Marine" 3 "Construction" 2 "AgriculturalAndForestry" 1 "On-Highway" 0 "Global" 6 "Reserved for SAE" ;
VAL_ 2498232062 PathRequested 255 "Proprietary15" 254 "Proprietary14" 253 "Proprietary13" 252 "Proprietary12" 251 "Proprietary11" 250 "Proprietary10" 249 "Proprietary9" 248 "Proprietary8" 247 "Proprietary7" 246 "Proprietary6" 245 "Proprietary5" 244 "Proprietary4" 243 "Proprietary3" 242 "Proprietary2" 241 "Proprietary1" 240 "Proprietary0" 1 "VTAccessibleStorage" ;
VAL_ 2498232062 ItemRequested 255 "Proprietary15" 254 "Proprietary14" 253 "Proprietary13" 252 "Proprietary12" 251 "Proprietary11" 250 "Proprietary10" 249 "Proprietary9" 248 "Proprietary8" 247 "Proprietary7" 246 "Proprietary6" 245 "Proprietary5" 244 "Proprietary4" 243 "Proprietary3" 242 "Proprietary2" 241 "Proprietary1" 240 "Proprietary0" 0 "ScreenImage" ;
VAL_ 2498232062 Status_3 1 "Ready" 0 "Initializing" ;
VAL_ 2498232062 IndustryGroup 7 "Reserved for SAE" 5 "IndustrialProcessCtrlStationary" 4 "Marine" 3 "Construction" 2 "AgriculturalAndForestry" 1 "On-Highway" 0 "Global" 6 "Reserved for SAE" ;
VAL_ 2498232062 VehicleSystem2 0 "NonSpecificSystem" 127 "Not Available" 1 "Tractor" 2 "Tillage" 3 "Secondary Tillage" 4 "Planters/Seeders" 5 "Fertilizers" 6 "Sprayers" 7 "Harvesters" 8 "Root Harvesters" 9 "Forage" 10 "Irrigation" 11 "Transport/Trailer" 12 "Farm Yard Operations" 13 "Powered Auxiliary Device" 14 "Special Crops" 15 "Earth Work" 16 "Skidder" 17 "Sensor Systems" 19 "Timber Harvesters" 20 "Forwarders" 21 "Timber loaders" 22 "Timber Processing Machines" 23 "Mulchers" 24 "Utility Vehicles" 25 "Slurry Applicators" ;
VAL_ 2498232062 OperatingState2 0 "InputNotActivatedInLearnMode" 1 "InputActivatedInLearnMode" ;
VAL_ 2498232062 Function 43 "Transmission Display" 44 "Exhaust Emission Control" 45 "Vehicle Dynamic Stability Control" 46 "Oil Sensor Unit" 47 "Information System Controller" 48 "Ramp Control" 49 "Clutch/Converter Control" 50 "Auxiliary Heater" 51 "Forward-Looking Collision Warning System" 52 "Chassis Controller" 53 "Alternator/Charging System" 54 "Communications Unit, Cellular" 55 "Communications Unit, Satellite" 56 "Communications Unit, Radio" 57 "Steering Column Unit" 58 "Fan Drive Control" 59 "Starter" 60 "Cab Display" 61 "File Server/Printer" 62 "On-Board Diagnostic Unit" 63 "Engine Valve Controller" 64 "Endurance Braking" 65 "Gas Flow Measurement" 66 "I/O Controller" 67 "Electrical System Controller" 68 "Aftertreatment system gas measurement" 69 "Engine Emission Aftertreatement System" 70 "Auxiliary Regeneration Device" 71 "Transfer Case Control" 72 "Coolant Valve Controller" 73 "Rollover Detection Control" 74 "Lubrication System" 75 "Supplemental Fan" 76 "Temperature Sensor" 77 "Fuel Properties Sensor" 78 "Fire Suppression System" 79 "Power Systems Manager" 80 "Electric Powertrain" 81 "Hydraulic Powertrain" 82 "File Server" 83 "Printer" 84 "Start Aid Device" 85 "Engine Injection Control Module" 86 "Reserved" 87 "Reserved" 88 "Reserved" 89 "Reserved" 90 "Reserved" 91 "Reserved" 92 "Reserved" 93 "Reserved" 94 "Reserved" 95 "Reserved" 96 "Reserved" 97 "Reserved" 98 "Reserved" 99 "Reserved" 100 "Reserved" 0 "Engine" 1 "Auxiliary Power Unit (APU)" 2 "Electric Propulsion Control" 3 "Transmission" 4 "Battery Pack Monitor" 5 "Shift Control/Console" 6 "Power TakeOff - (Main or Rear)" 7 "Axle - Steering" 8 "Axle - Drive" 9 "Brakes - System Controller" 10 "Brakes - Steer Axle" 11 "Brakes - Drive Axle" 12 "Retarder - Engine" 13 "Retarder - Driveline" 14 "Cruise Control" 15 "Fuel System" 16 "Steering Controller" 17 "Suspension - Steer Axle" 18 "Suspension - Drive Axle" 19 "Instrument Cluster" 20 "Trip Recorder" 21 "Cab Climate Control" 22 "Aerodynamic Control" 23 "Vehicle Navigation" 24 "Vehicle Security" 25 "Network Interconnect ECU" 26 "Body Controller" 27 "Power TakeOff (Secondary or Front)" 28 "Off Vehicle Gateway" 29 "Virtual Terminal (in cab)" 30 "Management Computer" 31 "Propulsion Battery Charger" 32 "Headway Controller" 33 "System Monitor" 34 "Hydraulic Pump Controller" 35 "Suspension - System Controller" 36 "Pneumatic - System Controller" 37 "Cab Controller" 38 "Tire Pressure Control" 39 "Ignition Control Module" 40 "Seat Control" 41 "Lighting - Operator Controls" 42 "Water Pump Control" 101 "Reserved" 102 "Reserved" 103 "Reserved" 104 "Reserved" 105 "Reserved" 106 "Reserved" 107 "Reserved" 108 "Reserved" 109 "Reserved" 110 "Reserved" 111 "Reserved" 112 "Reserved" 113 "Reserved" 114 "Reserved" 115 "Reserved" 116 "Reserved" 117 "Reserved" 118 "Reserved" 119 "Reserved" 120 "Reserved" 121 "Reserved" 122 "Reserved" 123 "Reserved" 124 "Reserved" 125 "Reserved" 126 "Reserved" 127 "Reserved" 255 "Not Available" ;
VAL_ 2498232062 OperatingState1 0 "LearnModeInactive" 1 "LearnModeActive" ;
VAL_ 2498232062 Status_2 0 "Hidden" 1 "Shown" ;
VAL_ 2498232062 ManufacturerCode 1077 "Ymer Technology" 1076 "DOGA S.A." 1075 "Uniden America Corporation" 1074 "Kindhelm / Navigs Oy" 1073 "Manitou Equipment America LLC" 1072 "La Marche Manufacturing Company" 1071 "MACH SYSTEMS s.r.o." 1070 "Quick-teck Electronics Ltd" 1069 "Lithionics Battery LLC" 1068 "Zapi S.p.A." 1067 "Tecomec S.r.l." 1066 "Spot Zero Water" 1065 "CALYPSO Instruments" 1064 "Omnitech Robotics Inc." 1063 "SolSteer" 1062 "Marol Co Ltd" 1061 "Volvo Construction Equipment" 1060 "Scale-Tec" 1059 "Boatrax" 1058 "Bondioli & Pavesi SpA" 1057 "EquipmentShare" 1056 "Lithium Pros" 1055 "EXA Computing GmbH" 1054 "Schmotzer Hacktechnik GmbH & Co. KG" 1053 "Vetus Maxwell, Inc." 1052 "Pfreundt" 1051 "ProNav AS" 1050 "Spacenus GmbH" 1049 "S&S Cycle" 1048 "Agrivation UG" 1047 "Sonic Corporation" 1046 "Praxidyn" 1045 "CMR Group" 1044 "Xee" 1043 "Hyva" 1042 "engcon group" 1041 "EZ Lynk" 1040 "BPE Electronics Srl" 1039 "Liugong Dressta Machinery" 1038 "EMIT Technologies, Inc." 1037 "Dragonfly Energy Corp." 1036 "Bender GmbH & Co. KG" 1035 "Agres" 1034 "Siren Marine" 1033 "ECCO Safety Group" 1032 "SIMOL S.p.A." 1031 "Flintec UK Ltd." 1030 "Tume-Agri Oy" 1029 "The Marine Guardian LLC" 1028 "Autel Intelligent Technology Corp., Ltd" 1027 "Goldacres PTY LTD" 1026 "ZTR Control Systems, LLC" 1025 "eze System, Inc." 1024 "Inventus Power" 1023 "PEAK-System Technik GmbH" 1022 "ITC Inc" 1021 "Entratech Systems LLC" 1020 "Onyx Marine Automation s.r.l." 1019 "Codek Foundries" 1018 "Flex TTS" 1017 "Caldaro AB" 1016 "Röhren- und Pumpenwerk BAUER GmbH" 1015 "SECURITAG SAS" 1014 "Briri Maschinenbau GmbH" 1013 "Allochis E-Tec" 1012 "Rhodan Marine Systems of Florida LLC" 1011 "Soundmax Electronics Ltd" 1010 "Agricultural Industry Electronics Foundation e.V." 1009 "TouchTronics, Inc." 1008 "Lintest Systems LLC" 1007 "Maschinenfabrik Meyer-Lohne GmbH" 1006 "Proterra" 1005 "TSE Brakes, Inc." 1004 "Ultraflex SpA" 1003 "technotrans SE" 1002 "Kussmaul Electronics Co." 1001 "Cleral Inc." 1000 "Landmaschinen Wienhoff GmbH" 1569 "621 Technologies Inc." 999 "TerraTroniq B.V." 998 "Transcell Technology Inc" 997 "Xenta Systems Srl" 996 "Eniquest Pty Ltd" 995 "Circuitlink Pty Ltd." 994 "Morris Industries Ltd." 993 "Alelion Energy Systems AB" 992 "MarineIOT LLC" 991 "Deutronic Elektronik GmbH" 990 "SAMSUNG SDI Co., Ltd." 989 "Flux-Geräte GmbH" 988 "Voith Turbo" 987 "Baltic Car Equipment" 986 "AAMP Global" 985 "NLR, LLC" 984 "E-T-A Elektrotechnische Apparate GmbH" 983 "Dezwaef NV" 982 "Briggs & Stratton Corporation" 981 "Kobelt Manufacturing Co. Ltd" 980 "Gussi Italia S.R.L." 979 "McHale" 978 "Canfield Connector" 977 "Emerson Electric Co." 976 "Derive Systems, Inc." 975 "Siemens AG" 974 "Pico Technology Limited" 973 "Zasso GmbH" 972 "Axion AG" 971 "B+B Smartworx" 970 "Jaboni Power Products, LLC" 969 "Blue Sea Systems" 968 "Cox Powertrain Limited" 967 "Moteck Electric Corp." 966 "VisibleFarm" 965 "Ro-Sys Software" 964 "AgroVIR Kft" 963 "Thomason Jones Company, LLC" 962 "Timbolier Industries, Inc." 961 "POK SAS" 960 "Vemcon GmbH" 959 "Cascade Corporation" 958 "NHK MEC Corporation" 957 "Sierra Wireless Inc" 956 "Piher Sensors & Controls S.A." 955 "Hottinger Baldwin (Suzhou) Electronic Measurement Technology Co., Ltd." 954 "Setec Pty Ltd" 953 "Curtiss-Wright" 952 "Tan Delta Systems Ltd" 951 "Exor International S.p.A." 950 "RE:Lab s.r.l." 949 "Škoda Electric a.s." 948 "Donix" 947 "Gerd Bär GmbH" 946 "Hydac Tecnologia Ltda" 945 "Equalizer AG" 944 "ZONTISA Marine SL" 943 "FISCHER AG Präzisionspindeln" 942 "Vogelsang GmbH & Co. KG" 941 "Navya" 940 "Dometal Oy" 939 "Warn Industries, Inc." 938 "LEVEL Systems" 937 "Precision Circuits Inc" 936 "Hi-tech Millennium" 935 "Meels GmbH & Co. KG" 934 "Farmobile, Inc." 933 "Delta Mobile Systems, Inc." 932 "Discover Battery" 931 "Enertec Marine Ltd" 930 "Ecotronix Corp." 929 "Jl Marine Systems, Inc." 928 "EAO Automotive GmbH & Co. KG" 927 "Saicon" 926 "Buhler Industries Inc." 925 "GW Lisk Company" 924 "PAS Peschak Autonome Systeme GmbH" 923 "ELTEK S.p.A." 922 "Terberg Benschop B.V." 921 "ROPA Fahrzeug- und Maschinenbau GmbH" 920 "MTD Consumer Group Inc." 919 "Furrion LLC" 918 "AMW Machine Control, Inc" 917 "Sentinel d.o.o." 916 "Turck Inc." 915 "Dosificacion y sistemas electronicos S.L. (DSE)" 914 "ZETOR TRACTORS a.s." 913 "Toyota Motor Corporation" 912 "Steyr Motors GmbH" 911 "Nautic-On" 910 "Hermann Paus Maschinenfabrik GmbH" 909 "Marines Co., Ltd." 908 "Chonbuk National University Department of Electronics" 907 "strautmann" 906 "MOBA AG" 905 "ASA Electronics" 904 "Equipment Safety Systems Pty. Ltd. (EQSS)" 903 "InMotion" 902 "Bucher Hydraulics" 901 "Zivan Srl" 900 "OSB AG" 899 "Lippert Components, Inc" 898 "Josef Kotte Landtechnik GmbH & Co. KG" 897 "Dot Technology Corp." 896 "NextFour Solutions Ltd" 895 "Peloton Technology" 894 "Rhodan Marine Systems of Florida LLC" 893 "KlinkTechnics Ltd." 892 "Mectronx Corp" 891 "CarrierWeb" 890 "L3 Technologies, Inc." 889 "SANY America Inc" 888 "Carma Systems Inc" 887 "Hyperdrive Innovation Limited" 886 "Hitachi Zosen Corporation" 885 "SICK Stegmann GmbH" 884 "Sure Grip Controls Inc." 883 "Swift Navigation, Inc." 882 "BHTronik GmbH & Co. KG" 881 "Sovema" 880 "Revision Military" 879 "PG Trionic, Inc." 878 "FOTON" 877 "SICK ATech GmbH" 876 "SUCO Robert Scheuffele GmbH & Co. KG" 875 "Salvarani S.r.l." 874 "MTA S.p.A." 873 "Garnet Instruments Ltd." 872 "Kählig Antriebstechnik GmbH" 871 "Superior Tech Inc" 870 "Textron Fleet Management" 869 "Intercomp" 868 "Data Panel Corp" 867 "Skeleton Technologies" 866 "Netradyne, Inc." 865 "MyEasyFarm" 864 "Streamline Transportation Technologies Inc." 863 "SMAG" 862 "Prospec Electronics" 861 "Adel System S.r.l." 860 "Michelin" 859 "Valor" 858 "Littelfuse" 857 "Zoomlion Heavy Industry NA, Inc" 856 "FarmFacts GmbH" 855 "Toshiba Infrastructure Systems & Solutions Corporation" 854 "GEMAC Chemnitz GmbH" 853 "Teledyne RESON B.V." 852 "Velvac Inc" 851 "Novotechnik Messwertaufnehmer OHG" 850 "Geoprospectors GmbH" 849 "MTS Maschinentechnik Schrode AG" 848 "ningupex" 847 "Oceanvolt" 846 "L3 Magnet-Motor" 845 "GMB Güstrower Maschinenbau GmbH" 844 "FELL AS" 843 "Hendrickson Truck Commercial Vehicle Systems" 842 "DigiDevice Srl" 841 "Agra-GPS" 840 "E.S.T.E. Srl" 839 "Indexator Rotator Systems AB" 838 "Teamsurv Ltd" 837 "Famic Technologies Inc." 836 "Signature4" 835 "PetTrack Ltd." 834 "Pioneer Microsystems, Inc." 833 "Electrum Automation AB" 832 "Heizomat Gerätebau-Energiesysteme GmbH" 831 "DOK-ING Ltd." 830 "Ultra Motion LLC" 829 "Drov Technologies, Inc." 828 "AgriBrink Inc." 827 "INmatix Technology Group Ltd" 826 "Lewmar Marine Inc" 825 "BPW Hungária" 824 "Undheim Systems AS" 823 "ACEINNA, Inc (formerly MEMSIC, Inc)" 822 "Bren-Tronics, Inc." 821 "Thorsen Teknik A/S" 820 "DIaLOGIKa Gesellschaft fuer angewandte Informatik mbH" 819 "Preco Electronics" 818 "HGNSS" 817 "TE Connectivity Sensor Solutions" 816 "UniStrong" 815 "FLIR Systems, Inc." 814 "Kronotech Srl (formerly Soltec Soluzioni Tecnologiche Srl)" 813 "Thales Suisse SA" 812 "Torch Technologies" 811 "Blue Water Desalination" 810 "Dutch Power Company" 809 "HMS Industrial Networks AB" 808 "RIMEX Supply Ltd." 807 "Schneider-Electric" 806 "Charge Automotive Ltd" 805 "Gundersen & Løken AS" 804 "ASA Electronics" 803 "Gill Sensors & Controls Limited" 802 "SPBI (Bj Technologie)" 801 "LOR Manufacturing Company Inc." 800 "Delta-Q Technologies" 799 "Stillwater Designs and Audio, Inc. - KICKER" 798 "Lumishore Ltd" 797 "Tides Marine" 796 "Canadian Automotive Industries Ltd" 795 "Broyda Enterprises Pty Ltd" 794 "Shihlin Electric & Engineering Corporation" 793 "James Fisher Prolec" 792 "Kostal Mexicana" 791 "AUTEC" 790 "VACALL" 789 "GRADALL" 788 "MoTeC Pty Ltd" 787 "Abertax Technologies Limited" 1863 "Thomas G. Faria Co." 1862 "Sanshin" 1861 "Vector North America" 1860 "MMP" 1859 "Kvasar AB" 1858 "Litton" 1857 "Simrad" 1856 "Trimble" 1855 "Furuno USA" 1854 "Northstar Technologies" 1853 "Japan Radio Co" 1852 "Navionics" 1851 "RayMarine" 1850 "Seastar Solutions (formerly Teleflex)" 786 "Johnson Matthey Battery Systems" 785 "Fischer Panda GmbH" 784 "CM Automotive Systems, Inc." 783 "Loup Electronics Inc." 782 "AVR bv (formerly AVR bvba)" 781 "Poly-Planar LLC" 780 "AVID Technology Ltd" 779 "RLC Electronic Systems" 778 "Seakeeper Inc." 777 "Ocean Signal Ltd" 776 "HMI Systems LLC" 775 "ZIEHL-ABEGG Automotive GmbH" 774 "Taisho Corporation" 773 "Clarion Corporation of America" 772 "Blink Marine" 771 "Shaw Development, LLC" 770 "MONOSEM" 769 "Trombetta" 768 "Flores Automation, LLC" 767 "Alliance Wireless Technologies Inc." 766 "Epec Oy" 765 "GIGAVAC" 764 "Bednar FMT s.r.o." 763 "AT-Systems BVBA" 762 "ROJ s.r.l." 761 "MITA OLEODINAMICA S.p.A." 760 "Bernecker + Rainer Industrie Elektronik GmbH" 759 "Hydro-Gear" 758 "Banner Engineering Corp." 757 "IMPCO Technologies" 756 "Maschio Gaspardo S.P.A." 755 "Firefly Integrations" 754 "Parker Hannifin Corp., Automation Group" 753 "AIROD Technologies" 752 "Deep Sea Electronics Plc" 751 "Pacific Track" 750 "Joskin SA" 749 "Chart Inc." 748 "ISOTTA" 747 "Agratronix" 746 "SureFire Ag Systems, Inc." 745 "Cidra Corporate Services Inc." 744 "Woosung Engineering Co., Ltd." 743 "Daemyung Elevator Co., Ltd." 742 "EROAD" 741 "Carling Technologies" 740 "e-Traction" 739 "LXNAV d.o.o." 738 "Blue Ink Technologies" 737 "Balluff GmbH" 736 "Terex Aerial Work Platforms - Genie" 735 "AEM Performance Electronics" 734 "REAPsystems" 733 "Intendia S.L." 732 "Gefran S.p.A." 731 "Modine Manufacturing Company" 730 "BERTHOUD AGRICOLE" 729 "Liebherr" 728 "Streumaster (formerly Streumaster / Panien)" 727 "Dhoot Transmission Pvt Ltd." 726 "MIDORI PRECISIONS" 725 "Hitachi Construction Machinery Co., Ltd." 724 "Electronic Applications, Inc." 723 "Jabil Inc." 722 "Contelec AG" 721 "Hypro" 720 "WITZ Corporation" 719 "Cojali S. L." 718 "Micronet Inc" 717 "Yacht Devices Ltd" 716 "Eaton Control & Power Conversion Division (CPCD)" 715 "Autonnic Research Ltd" 714 "Kobashi Kogyo Co., Ltd." 713 "US Hybrid Corporation" 712 "LOR Manufacturing Company Inc." 711 "DAS Co., LTD" 710 "Greentronics Ltd." 709 "Marquardt GmbH" 708 "Lars Thrane A/S" 707 "Rochester Gauges Inc" 706 "Shanghai Diesel Engine Corporation Limited" 705 "SVAB Hydraulik AB" 704 "JL Audio, Inc." 703 "Hydro Tab Marine Engineering" 702 "Weichai Power Co., Ltd." 701 "BigRoad Inc." 700 "K-Tec Earthmovers Inc." 699 "Harman International Industries" 698 "Scorpion Technologies Ltd." 697 "Ålö AB" 696 "DRS Network & Imaging Systems, LLC (DRS Technologies)" 695 "Weldon Technologies" 694 "GasTOPS Ltd." 693 "Agility Fuel Solutions (formerly Agility Fuel Systems)" 692 "Tanhay Corporation" 691 "Digitroll Agricultural Electronics" 690 "LINAK A/S" 689 "Aarcomm Systems Inc" 688 "Rockford Corp" 687 "Flight Systems, Inc." 686 "Taigene Electric Machinery Corp." 685 "ANEDO (formerly ANEDO Ltd.)" 684 "KEB" 683 "Fosen Elektro" 682 "Eckelmann AG" 681 "BEDIA Motorentechnik GmbH & Co. KG" 680 "AMVAC Chemical Corporation" 679 "Cimco Marine AB" 678 "KeepTruckin, Inc." 677 "DSA Daten- und Systemtechnik GmbH" 676 "Danfoss IXA A/S" 675 "Kawasaki Motors Corp., USA" 674 "Yara International ASA" 673 "Caruelle Nicolas" 672 "OPTIMA Concept" 671 "Innovative Controls Inc." 670 "STEMCO LP" 669 "Quantum Fuel Systems Technologies Worldwide, Inc" 668 "MacDon Industries Ltd." 667 "Bartec" 666 "Schaeffler Technologies AG & Co., KG" 665 "Gebr. Bode GmbH & Co. KG" 664 "Level Developments Ltd" 663 "Delta Systems, Inc" 662 "Kissling Elektrotechnik GmbH" 661 "SPAL Automotive S.r.l." 660 "Auto-Gaz Centrum" 659 "Data Panel Corp." 658 "Shenzhen Jiuzhou Himunication Technology Co., Ltd" 657 "Terzo Power Systems" 656 "PRO SOLUS do Brasil" 655 "Genge & Thoma AG" 654 "Kohler Power Systems, Detroit Engine Development Center (DEDC)" 653 "AEV, spol. s r. o." 652 "MicroControl GmbH & Co. KG" 651 "Takakita Co, Ltd." 650 "Seiko Epson Corp." 649 "Control-Q B.V." 648 "OJSC Ekran" 647 "Siloking" 646 "Veenhuis Machines B.V." 645 "esd electronic system design gmbh" 644 "KUS USA" 643 "Bogballe A/S" 642 "Moog / Aspen Motion Technologies" 641 "Diverse Yacht Services" 640 "Power Solutions International" 639 "Startec s.r.l." 638 "KVH Industries, Inc." 637 "Bavaria Yachtbau GmbH" 636 "Divelbiss Corporation" 635 "Argo Tractors S.p.A." 634 "Rocky Research" 633 "TORC Robotics" 632 "Pepperl+Fuchs GmbH" 631 "Reltima" 630 "SmartDrive Systems Inc." 629 "Agri Info Design, Ltd." 524 "Vomax Instrumentation Pty. Ltd." 523 "Reggio Emilia Innovazione" 522 "Nebraska Tractor Test Laboratory" 521 "Clever Devices Ltd." 520 "Trapeze" 519 "Peeters Landbouwmachines b.v." 518 "Transas USA Inc." 517 "Noland Engineering" 516 "AVAT Automation GmbH" 515 "GINAF Trucks Nederland B.V." 514 "DISTek Integration, Inc." 513 "Precision Technology (Formerly FarmscanAg)" 512 "Inpower LLC" 511 "Sulky" 510 "Marinesoft Co. Ltd" 509 "MOTORTECH GmbH" 508 "Transtech Innovations" 507 "ISOBUS Test Center" 506 "IHI STAR Machinery Corporation" 505 "Yetter Farm Equipment" 504 "Vesper Marine" 503 "Naviop S.R.L." 502 "Attwood Corporation" 501 "Agrotronix S.A." 500 "Oxbo International Corporation" 499 "LCJ Capteurs" 498 "Innovative Design Solutions, Inc." 497 "SENTRON Sistemas Embarcados" 496 "W. Gessmann GmbH" 495 "HOLMER Maschinenbau GmbH" 494 "Synerject" 493 "Watcheye" 492 "Inergy Automotive Systems" 491 "Penny and Giles Ltd" 490 "QuikQ" 489 "Appareo Systems, LLC" 488 "The Charles Machine Works, Inc." 487 "DSE Test Solutions A/S" 486 "Westport Innovations Inc." 485 "MATT automotive" 484 "Headsight Inc." 483 "Valeo" 482 "Tricon Electronics" 481 "Chetco Digital Instruments" 480 "EnerDel, Inc." 479 "Vapor Bus International" 478 "OceanSat B.V." 477 "OilQuick AB" 476 "Hummingbird Marine Electronics" 475 "GME" 474 "Persen Technologies Inc." 473 "Boss Industries, Inc." 472 "Tenneco Inc." 471 "Sea Cross Marine AB" 628 "Falck Schmidt Defence Systems" 627 "Radio Ocean" 626 "AVL DiTEST GmbH" 625 "Global MRV Inc." 624 "Blackbox Machine Control Pty Ltd" 623 "Xirgo Technologies" 622 "Floyd Bell Inc" 621 "Hagie Manufacturing Company" 620 "Sevcon Ltd." 619 "Right Weigh Load Scales" 618 "Evrard SA" 617 "Zero Emission Vehicles" 616 "SMART-TEC s.r.o." 615 "Networkfleet, Verizon Telematics" 614 "ARLT Technologies GmbH" 613 "HKS Co., Ltd." 612 "Samwon IT" 611 "Esterline" 610 "Trail Tech" 609 "Walvoil S.p.A." 608 "Gale Banks Engineering" 607 "Knappco/Civacon" 606 "Intellian Technologies" 605 "Aventics GmbH" 604 "Indexator Rototilt Systems AB" 603 "Kereval" 602 "Nomad Digital Ltd." 601 "Navitas Systems" 600 "Aquatic AV" 599 "Spudnik Equipment Co, LLC" 598 "ABB Turbo Systems Ltd" 597 "Hydac Filter Systems GmbH" 596 "Brunelco Electronic Innovators B.V." 595 "CustomWare" 594 "Kongsberg Automotive" 593 "Sensata Technologies" 592 "tecsis GmbH" 591 "United States Coast Guard" 590 "ARGO-HYTOS GMBH" 589 "MICO, Inc." 588 "Vignal Systems" 587 "JCA Electronics" 586 "Suzuki Motor Corp" 585 "Industrial Electronic Controls" 584 "CarMedialab GmbH" 583 "Yachtcontrol" 582 "Innovative Software Engineering" 581 "Väderstad - Verken AB" 580 "San Jose Technology, Inc." 579 "KVH Industries, Inc." 578 "advanSea" 577 "Denchi Power Ltd  (formerly ABSL Power Solutions Limited)" 576 "Vectia" 575 "Lytx" 574 "Vishay Precision Group" 573 "Orolia Ltd" 572 "Fasse Valves" 571 "Marinecraft Co., Ltd." 570 "frenzel + berg electronic GmbH & Co. KG" 569 "LORD MicroStrain Sensing Systems" 568 "Makersan Ltd. Co." 567 "Lithiumstart LLC" 566 "Geode Technology, Inc." 565 "Micro-Trak Systems, Inc." 564 "Auto Power Electronic" 563 "LOHR Sistemas Eletronicos LTDA" 562 "Bombardier Transportation GmbH" 561 "b-plus GmbH" 560 "Iowa State University, Agricultural and Biosystems Engineering" 559 "Four Peaks Navigation" 558 "Davis Instruments Corp." 557 "Rockson Automation GmbH" 556 "Doosan Infracore Norway" 555 "Sasaki Corporation" 554 "iris-GmbH infrared & intelligent sensors" 553 "KIB Electronics" 552 "Matsuyama Plow Mfg Co, Ltd" 551 "Wexler CSD Ltd." 550 "SUN-A Corporation" 549 "ROAD Deutschland GmbH" 548 "TM4 Inc." 547 "Thomson Linear LLC" 546 "Maruyama Mfg Co, Inc." 545 "GS Hydraulics" 544 "Au Group Electronics" 543 "BAUER Maschinen GmbH" 542 "Dinamica Generale s.p.a." 541 "Total Fire Systems, Inc." 540 "Dinex A/S" 539 "Mobileview" 538 "Crop Ventures, Inc." 537 "Schrader Electronics Ltd." 536 "SSI Technologies" 535 "MOTORPAL, a.s." 534 "Webasto Thermo & Comfort SE" 533 "Doran Manufacturing, LLC" 532 "Onwa Marine Electronics Co Ltd." 531 "Genge & Thoma AG" 530 "NMEA" 529 "National Instruments Korea" 528 "Hoganas AB, Electric Drive Systems" 527 "GKN Walterscheid GmbH" 526 "LOFA Industries, Inc" 525 "Rust Sales INC" 470 "SI-TEX Marine Electronics" 469 "RA Consulting GmbH" 468 "Tyco Fire Protection Products" 467 "Lely Industries N.V." 466 "Veethree Electronics and Marine LLC" 465 "Ashcroft Inc" 464 "Leach International Corporation" 463 "PROBOTIQ" 462 "IHI Shibaura Machinery Corporation" 461 "HAWE Hydraulik SE" 460 "San Giorgio S.E.I.N." 459 "Alltek Marine Electronics Corp" 458 "Control Solutions, Inc." 457 "RUSELPROM-ElectricDrive Ltd" 456 "General Kinetics" 455 "ADZ NAGANO GmbH" 454 "NGK Spark Plug Co. Ltd" 453 "Cooper Bussmann" 452 "WIKA Alexander Wiegand SE & Co. KG" 451 "Parker Hannifin Corp" 450 "Dycor Technologies Ltd." 449 "Polaris Industries Inc" 448 "Stanadyne Corporation, Electronics Systems" 447 "Great Plains Mfg." 446 "CertTech, L.L.C." 445 "KAT MECHATRONIC, Electronic Product Division" 444 "ITT Power Solutions" 443 "SignalQuest, Inc." 442 "Horsch Maschinen GmbH" 441 "PTG Reifendruckregelsysteme GmbH" 440 "Cummins Power Generation" 439 "Hyundai Heavy Industries" 438 "Comar Systems Ltd" 437 "Digital Yacht Limited" 436 "Kinze Manufacturing" 435 "Zunhammer GmbH" 434 "Stored Energy Systems" 433 "Rowe Electronics" 432 "S&A Systems, Inc." 431 "Tohatsu Corporation" 430 "Auteq Telematica S.A." 429 "Rota Engineering Ltd." 425 "Methode Electronics Inc, MDI" 424 "Odyne LLC" 423 "BSM Wireless, Inc." 422 "True Heading AB" 421 "Vertex Standard Co, Ltd" 420 "Vermeer Corporation, ACS Group" 419 "Fusion Electronics Ltd" 418 "Intellistick Inc" 417 "KZValve" 416 "Kubota Corporation" 415 "Valid Manufacturing Ltd." 414 "Cattron Group International" 413 "Datapross Nijbroek bv" 412 "WebTech Wireless Inc." 411 "Hy-Drive Technologies Ltd." 410 "COBO S.p.A. Divisione 3B6" 409 "Transfluid S.r.L." 408 "Corvus Energy Ltd." 407 "Comtech Mobile Datacom" 406 "Vecima Networks Inc." 405 "Wema System AS" 404 "Com Nav Marine Ltd" 403 "Trackwell ADS, Inc." 402 "Simma Software, Inc." 401 "Torqeedo GmbH" 400 "Livorsi Marine" 399 "ISEKI & Co., Ltd." 398 "Hilite International" 397 "Sanyo-kiki Co Ltd." 396 "Beyond Measure" 395 "GENTEC S.R.L." 394 "Capi 2 Nederland B.V." 393 "Harvest Tec, Inc" 392 "Tianyuan Technology Co Ltd." 391 "Electronic Design for Industry, Inc" 390 "Partech Inc." 389 "Benchmark Electronics, Minnesota Division" 388 "Innomatix, LLC" 387 "Orscheln Products, LLC" 386 "JLG Automation BVBA" 385 "Johnson Outdoor Marine Electronics" 384 "Camano Light" 383 "MCL Industries" 382 "National Agriculture and Food Research Organization" 381 "B & G" 380 "Suntech International Ltd." 379 "Yamabiko Corporation" 378 "Glendinning Marine Products" 377 "ifm electronic gmbh" 376 "Quake Global" 375 "Williams Controls Inc." 374 "Northern Lights, Inc." 373 "Electronic Design Inc." 372 "Delphi" 371 "Heinzmann GmbH & Co. KG" 370 "Rolls-Royce Marine AS" 369 "Power Torque Engineering Ltd" 368 "HANSENHOF_electronic" 367 "Fliegl Agrartechnik" 366 "Viewnyx Corp." 365 "Digi-Star, LLC" 364 "OEM Controls Inc." 363 "BEI Duncan" 362 "Poettinger Landtechnik GmbH (formerly Alois Poettinger Maschinenfabrik GmbH)" 361 "InMach" 360 "HJS Emission Technology GmbH & Co KG   (formerly HJS Fahrzeugtechnik GmbH & Co KG)" 359 "Ludwig Bergmann GmbH" 358 "Victron Energy B.V." 357 "Hardi International A/S" 356 "Fischer Panda Generators, Inc" 355 "Mastervolt International B.V." 354 "Junkkari OY" 353 "Hegemon Electronics, Inc." 352 "SAME DEUTZ-FAHR GROUP S.p.A." 351 "Thrane & Thrane" 350 "Noris Marine Systems GmbH & Co KG" 349 "Suonentieto" 348 "Amazonen Werke H. Dreyer" 347 "Honeywell" 346 "Control Solutions" 345 "Korean Maritime University" 344 "Parvus Corporation" 343 "Baumer Group" 342 "THOMAS MAGNETE GmbH" 341 "Boning GmbH & Co" 340 "Continental AG" 339 "Competence Center ISOBUS e.V." 338 "GRAF-SYTECO" 337 "Carraro S.p.A." 336 "APE s.r.o." 335 "Evo Electric Ltd" 334 "Takata-Petri AG" 333 "Hadley Products Corporation" 332 "HWH Corporation" 331 "Horton, Inc." 330 "Kidde Aerospace and Defense" 329 "Deif A/S" 328 "Qwerty Electronik AB" 327 "Sonceboz SA" 326 "Akron Brass Company" 325 "ASM Automation Sensorik Messtechnik GmbH" 324 "Snap-on Diagnostics" 323 "Mobileye Vision Technologies Ltd." 322 "MICHENKA s.r.o." 321 "Ultra Electronics, Electrics" 320 "Miedema Landbouwwerktuigenfabriek B.V." 319 "Cadec Global" 318 "SAT Plan" 317 "Navtronics Bvba" 263 "IMMI" 262 "HydraForce, Inc" 261 "Red Dot Corporation" 260 "Reichhardt GmbH Steuerungstechnik" 259 "Jetter AG" 258 "ARAG" 257 "Honda Motor Co., Ltd" 256 "Tyco Electronics AMP" 255 "MEAS France" 254 "GE Sensing" 253 "Mobile Control Systems" 252 "Sensor-Technik Wiedemann GmbH" 251 "German Agricultural Society, Test Center (DLG)" 250 "Kuhn Group" 249 "Schaltbau GmbH" 248 "Cooper Standard Automotive Active Systems Group" 247 "ePULSE" 246 "Class 1, Inc" 245 "Capstan Ag Systems, Inc." 244 "Techno-Matic" 243 "eRide, Inc." 242 "Kokusandenki Co. Ltd" 241 "Schneider Automation SAS" 240 "Vanair Mfg" 239 "May & Scofield Ltd" 238 "ZF Friedrichshafen AG" 237 "Agtron Enterprises Inc" 236 "NORAC Systems International Inc" 235 "SailorMade Marine Telemetry - Tetra Technology Ltd." 234 "Mondial electronic GmbH" 233 "Yacht Monitoring Solutions Inc." 232 "TSD Integrated Controls" 231 "Topcon Positioning Systems, Inc." 230 "Saucon Technologies" 229 "Garmin International Inc." 228 "Unused (formerly ZF Marine Electronics)" 227 "Lykketronic A/S" 226 "Monaco Coach Corporation" 225 "SKF" 224 "EMMI Network, S.L." 223 "Vaueo Retarder Co., Ltd." 222 "Generac Power Systems, Inc." 221 "SiE" 220 "Beede Electrical Instrument Company, Inc" 219 "Cat OEM Solutions" 218 "Gits Manufacturing Company" 217 "RM Michaelides Software & Elektronik GmbH" 216 "Paneltronics Inc." 215 "Aetna Engineering/Fireboy-Xintex" 214 "MC elettronica Srl" 164 "MTU Friedrichshafen GmbH (formerly DaimlerChrysler Off-Highway)" 163 "BRP Inc." 162 "Axiomatic Technologies" 161 "Offshore Systems (UK) Ltd" 160 "Nido" 159 "NTech Industries Inc" 158 "Firestone Industrial Products Company" 157 "ISSPRO Inc." 156 "ITT Industries - Cannon" 155 "Vetronix Corporation" 154 "Westerbeke Corporation" 153 "Woodward, Industrial Controls Division" 152 "elobau GmbH & Co. KG" 151 "Raven Industries, Inc." 150 "Fleetguard" 149 "Holset" 148 "Blue Water Data, Inc." 147 "Nautibus electronic GmbH" 146 "Maxima Technologies" 145 "MurCal Controls" 144 "Mercury Marine" 143 "W. Gmeiner GmbH & Co." 142 "TRW Automotive (Commercial Steering Systems)" 141 "Thales Navigation Ltd." 140 "Lowrance Electronics, Inc." 139 "Caterpillar Trimble Control Technologies (CTCT), LLC" 138 "Georg Fritzmeier GmbH & Co. KG" 137 "Maretron" 136 "Komatsu Ltd" 135 "Airmar Technology Corporation" 134 "Iris Technology Ltd" 133 "Bucher Schoerling GmbH" 132 "Mulag-Fahrzeugwerk" 131 "ITT Industries" 130 "Nido - Universal Machines B.V." 129 "OMNEX Control Systems Inc." 128 "Gerhard Duecker GmbH & Co. KG" 127 "Holland USA" 126 "Driver Tech" 125 "Nevada Automotive Test Center" 124 "Hydac Electronic" 123 "Basler Electric" 122 "FG Wilson (Engineering) Limited" 121 "HED (Hydro Electronic Devices, Inc.)" 120 "RDS Technology Ltd" 119 "IntegriNautics  " 118 "Intron GmbH" 117 "HUSCO International" 116 "BEELINE Technologies" 115 "NACCO Materials Handling Group, Inc." 114 "EControls, Inc." 113 "Stress-Tek, Inc." 112 "MECALAC" 111 "Bernard Krone Holding SE & Co. KG (formerly Maschinenfabrik Bernard Krone GmbH)" 110 "EPIQ Sensor-Nite" 109 "TeeJet Technologies Denmark (formerly LH Technologies ApS)" 108 "WTK-Elecktronik GmbH" 107 "Grimme Landmaschinen GmbH & Co. KG" 106 "BAE Systems Controls, Inc." 105 "Kiepe Elektrik GmbH & Co. KG" 104 "CLAAS KGaA mbH (formerly CLAAS Selbstfahrende Erntemaschinen GmbH)" 103 "CLAAS E-Systems GmbH (formerly CLAAS E-Systems KGaA mbH & Co. KG)" 102 "AGCO (formerly AGCO GmbH & Co.)" 101 "Sensoria" 100 "VDO Technik AG" 99 "International Transmissions Ltd (ITL)" 98 "Mueller-Elektronik GmbH & Co" 97 "Ag Leader Technology, Inc." 96 "Mech@tronic IT GmbH" 95 "Pacific Insight Electronics Corp." 94 "CNH Industrial N.V. (formerly CNH Global N.V.)" 93 "Perkins Engines Company Ltd." 92 "Ag-Chem Equipment Co., Inc." 91 "BSG Bodensee Steuergeraete GmbH" 90 "Knorr-Bremse SfN GmbH" 89 "Kverneland Group, Electronics Division" 88 "Hemisphere GPS Inc (formerly Satloc Precision GPS)" 87 "J.C. Bamford Excavators Ltd (JCB)" 86 "C. E. Niehoff & Company" 85 "Kohler Co" 84 "New Holland UK Limited" 83 "Bendix VORAD Technologies (formerly Eaton VORAD Technologies)" 82 "Bobcat/Ingersoll-Rand (formerly Melroe/Ingersoll-Rand)" 81 "Fire Research Corp." 80 "Twin Disc, Inc." 79 "Daimler Benz AG - Engine Division (PBM)" 78 "Frank W. Murphy Manufacturing, Inc" 77 "Deere Power Systems Group" 76 "unused (formerly Deere & Co, Construction Division)" 75 "Deere & Co, Agricultural Division" 74 "Eaton Axle-Brake Division" 73 "LeTourneau, Inc." 72 "Sisu Corporation" 71 "Vansco Electronics Ltd." 70 "Flex-coil Limited" 69 "Trimble Navigation" 316 "ITT Flow Control" 315 "Icom Incorporated" 314 "CSM GmbH" 313 "Ilmor Engineering, Inc." 312 "Lectronix, Inc." 311 "Patrick Power Products" 310 "TECNORD srl" 309 "Krauss-Maffei Wegmann GmbH & Co. KG" 308 "Cyntrx" 307 "MAS Technologies" 306 "Sleipner Motor AB" 305 "NovAtel Inc" 304 "EmpirBus AB" 303 "CTS Corporation" 302 "Nissin Kogyo Co., LTD" 301 "Parker Hannifin (UK) Ltd FDE group" 300 "Systron Donner Automotive" 299 "Rauch" 298 "Holley Performance" 297 "Zonar Systems Inc" 296 "micro dynamics GmbH" 295 "BEP Marine" 294 "Grayhill Inc." 293 "Spyder Controls Corp." 292 "IKUSI - Angel Iglesias S.A." 291 "Groeneveld Transport Efficiency BV" 290 "Kuebler GmbH" 289 "Watlow" 288 "Mitsubishi FUSO Truck & Bus Corp." 287 "NTech Industries, Inc" 286 "Coelmo srl" 285 "Sea Recovery Corp" 284 "Mobile Tech Chile" 283 "CWF Hamilton & Co Ltd" 282 "Medallion Instrumentation Systems" 281 "Precision Governors LLC" 280 "Leica Geosystems Pty Ltd" 279 "Geometris LP" 278 "Takata Electronics" 277 "LHP Telematics" 276 "Aqua-Hot Heating Systems" 275 "Navico Egersund AS" 274 "LTW Technology Co., LTD" 273 "Active Research Limited" 272 "Gross Mechanical Laboratories, Inc" 271 "Cole Hersee" 270 "Tennant" 269 "Saft America Inc.,  Space & Defense Division" 268 "Accurate Technologies" 267 "Red Lion Controls, Inc" 266 "International Thermal Research Ltd" 265 "MTS Sensor Technologie GmbH" 264 "Autolync" 213 "CNH Belgium N.V." 212 "Sure Power Industries, Inc" 211 "DNA Group" 210 "Iteris, Inc." 209 "Bell Equip. Co. SA (PTY) LTD" 208 "Drew Technologies, Inc" 207 "Otto Engineering" 206 "port GmbH" 205 "SmarTire Systems Inc" 204 "The Morey Corporation" 203 "MILtronik GmbH" 202 "Curtis Instruments, Inc" 201 "Disenos y Tecnologia S.A." 200 "MGM Brakes" 199 "ACTIA Group (formerly Actia Corp)" 198 "Mystic Valley Communications" 197 "Mechron Power Systems" 196 "LEMKEN GmbH & Co KG" 195 "General Engine Products" 194 "TriMark Corporation" 193 "Jeppesen Marine" 192 "Floscan" 191 "XRS Corporation (formerly XATA Corporation)" 190 "Hella KGaA Hueck & Co" 189 "QUALCOMM" 188 "EMP Corp" 187 "Air-Weigh" 186 "Altronic, Inc" 185 "Beede Electrical Instrument Company" 184 "EIA Electronics" 183 "KDS Controls, Inc" 182 "Vehicle Systems Engineering B.V." 181 "Coretronics, Inc." 180 "Smart Power Systems" 179 "TeeJet Technologies Springfield (formerly Midwest Technologies Illinois, LLC)" 178 "Continental Automotive GmbH (formerly Siemens VDO Automotive AG)" 177 "Diagnostic Systems Associates" 176 "Moritz Aerospace" 175 "Veris Technologies, Inc." 174 "AB Volvo Penta" 173 "Ryeso, Inc." 172 "Yanmar Co., Ltd. (formerly Yanmar Marine USA)" 171 "Topcon Electronics GmbH & Co. KG (formerly Wachendorff Elektronik GmbH & Co. KG)" 170 "Computronics Corporation Ltd." 169 "Marlin Technologies Inc." 168 "Xantrex" 167 "JLG Industries Inc" 166 "John Deere Electronic Solutions (formerly Phoenix International)" 165 "CPAC Systems AB" 68 "Scania" 67 "John Deere Coffeyville Works (formerly Funk Manufacturing Company)" 66 "John Deere Construction Equipment Division" 65 "MAN Nutzfahrzeuge AG" 64 "Unused (formerly SpectraPrecision Laserplane, then SpectraPhysics)" 63 "ZF Industries Inc." 62 "Wabco" 61 "Volvo Truck Corp." 60 "Volvo Trucks North America Inc." 59 "VES Inc." 58 "SPX Corporation, OTC Div" 57 "Danfoss  (formerly Sauer Sundstrand Co, then Sauer-Danfoss Co)" 56 "SAIC" 55 "Ryder System Inc." 54 "Meritor Wabco" 53 "Continental Automotive Systems US, Inc. (formerly Rockwell Land Transportation)" 52 "Meritor Automotive, Inc. (formerly Rockwell Automotive)" 51 "Robert Bosch GmbH" 50 "Robert Bosch Corp" 49 "RE America Inc." 48 "Pollak Alphabet" 47 "Phillips Semiconductor" 46 "Noregon Systems, Inc  (formerly Parasoft Computing Solutions)" 45 "PACCAR" 44 "Nippondenso Co. Ltd." 43 "International Truck and Engine Corporation - Vehicle Electronics (formerly Navistar Intl Trans Corp.)" 42 "International Truck and Engine Corporation - Engine Electronics  (formerly Navistar Intl Trans Co., Engine Electronics)" 41 "Motorola Inc." 40 "Motorola AIEG Inc." 39 "Microfirm Inc." 38 "Micro Processor Systems Inc." 37 "Mack Trucks Inc." 36 "Lucas Ind." 35 "Kenworth Truck Co." 34 "Kelsey Hayes Co." 33 "John Deere" 32 "Jacobs Vehicle Systems" 31 "J Pollak Corp" 30 "Isuzu Motors Ltd" 29 "Hino Motors Ltd." 28 "Grote Ind. Inc." 27 "GMC" 26 "General Motors Corp, Service Technology Grp" 25 "Daimler Trucks North America LLC (formerly Freightliner LLC)" 24 "Ford Motor Co., Vehicle Controls" 23 "Ford Motor Co., Heavy Truck" 22 "Ford Motor Co., Electronic Concepts & Systems" 21 "Echlin Inc., Midland Brake Inc." 20 "Eaton Ltd" 19 "Eaton Corp. Trucking Info Services" 18 "Eaton Corp, Transmission Div." 17 "Eaton Corp, Corp Res & Dev" 16 "Eaton Corp" 15 "DICKEY-john Corporation" 14 "Detroit Diesel Corporation" 13 "Delco Electronics" 12 "Deere & Company, Precision Farming" 11 "Dearborn Group Inc." 10 "Cummins Inc (formerly Cummins Engine Co)" 9 "Chrysler Corp." 8 "Caterpillar Inc." 7 "Case Corp." 6 "Berifors Electronics AB" 5 "AMP Inc." 4 "Ametek-Dixson" 3 "Ametek, US Gauge Division" 2 "Allison Transmission, Inc." 1 "Bendix Commercial Vehicle Systems LLC (formerly Allied Signal Inc.)" 0 "Reserved" ;
VAL_ 2498232062 TextOption 0 "Opaque" 1 "Transparent" ;
VAL_ 2498232062 KeyObjectParentID 2 "KeyIsStillHeld" 1 "KeyHasBeenPressed" 0 "KeyHasBeenReleased" ;
VAL_ 2498232062 SubCommandID 0 "SetGraphicsCursor" 1 "MoveGraphicsCursor" 2 "SetForegroundColour" 3 "SetBackgroundColour" 4 "SetLineAttributesObjectID" 5 "SetFillAttributesObjectID" 6 "SetFontAttributesID" 7 "EraseRectangle" 8 "DrawPoint" 9 "DrawLine" 10 "DrawRectangle" 11 "DrawClosedEllipse" 12 "DrawPolygon" 13 "DrawText" 14 "PanViewport" 15 "ZoomViewport" 16 "PanAndZoomViewport" 17 "ChangeViewportSize" 18 "DrawVTObject" 19 "CopyCanvasToPictureGraphic" 20 "CopyViewportToPictureGraphic" ;
VAL_ 2498232062 EnableOrDisable 1 "Enable" 0 "Disable" ;
VAL_ 2498232062 ShowOrHide 1 "Show" 0 "Hide" ;
VAL_ 2498232062 AssignmentErrorNotAccepted 1 "AssignmentNotAccepted" 0 "AssignmentAccepted" ;
VAL_ 2498232062 Status_1 0 "Hidden" 1 "Shown" ;
VAL_ 2498232062 KeyObjectID 2 "KeyIsStillHeld" 1 "KeyHasBeenPressed" 0 "KeyHasBeenReleased" ;
VAL_ 2498232062 WSMaintenanceVersion 3 "CompliantWithVTVersion3" 4 "CompliantWithVTVersion4" 255 "CompliantWithVTVersion2AndPrior" ;
VAL_ 2498232062 AuxCapabilitiesRequestType 0 "RequestCapabilitiesOfAuxiliaryInputs" 1 "RequestCapabilitiesOfAuxFunctions" ;
VAL_ 2498232062 LockUnlockCommand 0 "UnlockMask" 1 "LockMask" ;
VAL_ 2498232062 MaskType 2 "Alarm" 1 "Data" ;
VAL_ 2498232062 ButtonActivationCode 2 "ButtonsStillHeld" 1 "ButtonHasBeenLatched" 0 "ButtonHasBeenUnlatched" 3 "ButtonPressAborted" ;
VAL_ 2498232062 KeyActivationCode 2 "KeyIsStillHeld" 1 "KeyHasBeenPressed" 0 "KeyHasBeenReleased" 3 "KeyPressAborted" ;
VAL_ 2498232062 VTFunctionECUtoVT 10 "VTControlAudioSigTerminationResp" 38 "AuxiliaryInputType2Status" 198 "ScreenCapture" 144 "SelectActiveWorkingSet" 253 "UnsupportedVTFunction" 8 "VTChangeStringValueResponse" 180 "ChangeChildPosition" 17 "ObjectPoolTransfer" 196 "GetWindowMaskData" 7 "VTChangeSoftKeyMaskResponse" 6 "VTChangeActiveMaskResponse" 5 "VTChangeNumericValueResponse" 4 "VTESCResponse" 3 "VTSelectInputObjectResponse" 179 "ChangeStringValue" 255 "WorkingSetMaintenance" 223 "GetVersions" 210 "DeleteVersion" 209 "LoadVersion" 208 "StoreVersion" 199 "GetHardware" 195 "GetTextFontData" 194 "GetNumberOfSoftKeys" 192 "GetMemory" 178 "DeleteObjectPool" 177 "ChangeListItem" 176 "ChangePriority" 175 "ChangeAttribute" 174 "ChangeSoftKeyMask" 173 "ChangeActiveMask" 172 "ChangeFillAttributes" 171 "ChangeLineAttributes" 170 "ChangeFontAttributes" 169 "ChangeEndPoint" 168 "ChangeNumericValue" 167 "ChangeBackgroundColour" 166 "ChangeSize" 165 "ChangeChildLocation" 164 "SetAudioVolume" 163 "ControlAudioDevice" 162 "SelectInputObject" 161 "EnableDisableObject" 160 "ShowHideObject" 146 "ESC" 32 "AuxiliaryAssignmentResponse" 18 "EndOfObjectPool" 2 "PointingEventResponse" 1 "ButtonActivationResponse" 0 "SoftKeyActivationResponse" 181 "ChangeObjectLabel" 182 "ChangePolygonPoint" 183 "ChangePolygonScale" 184 "GraphicsContextCommand" 185 "GetAttribute" 186 "SelectColourMap" 9 "VTOnUserLayoutHideShowResponse" 34 "AuxiliaryPreferredAssignment" 189 "LockUnlockMask" 190 "ExecuteMacro" 35 "AuxiliaryInputMaintenance" 37 "AuxiliaryInputStatusEnableCommandResponse" 193 "GetSupportedWideChars" 33 "Auxiliary Input Status" 36 "AuxiliaryAssignmentResponseType2" 187 "IdentifyVT" 197 "GetSupportedObjects" 188 "ExecuteExtendedMacro" 211 "ExtendedGetVersions" 212 "ExtendedStoreVersion" 213 "ExtendedLoadVersion" 214 "ExtendedDeleteVersion" 39 "AuxiliaryCapabilitiesRequest" ;
SIG_VALTYPE_ 2498232062 ZoomValue_PanZoom : 1;
SIG_VALTYPE_ 2498232062 ZoomValue : 1;
SG_MUL_VAL_ 2498232062 AudioWasTerminated VTFunctionECUtoVT 10-10;
SG_MUL_VAL_ 2498232062 VTControlAudioSigTerminationTAN VTFunctionECUtoVT 10-10;
SG_MUL_VAL_ 2498232062 VTSelectInputObjectIsEdited VTFunctionECUtoVT 3-3;
SG_MUL_VAL_ 2498232062 ParentMaskObjectID VTFunctionECUtoVT 2-2;
SG_MUL_VAL_ 2498232062 OperatingState4 VTFunctionECUtoVT 38-38;
SG_MUL_VAL_ 2498232062 OperatingState3 VTFunctionECUtoVT 38-38;
SG_MUL_VAL_ 2498232062 VTSelectInputObjectResponseTAN VTFunctionECUtoVT 3-3;
SG_MUL_VAL_ 2498232062 VTOnUserLayoutHideShowRespTAN VTFunctionECUtoVT 9-9;
SG_MUL_VAL_ 2498232062 VTESCResponseTAN VTFunctionECUtoVT 4-4;
SG_MUL_VAL_ 2498232062 VTChangeNumericValueResponseTAN VTFunctionECUtoVT 5-5;
SG_MUL_VAL_ 2498232062 SoftKeyActivationResponseTAN VTFunctionECUtoVT 0-0;
SG_MUL_VAL_ 2498232062 PointingEventResponseTAN VTFunctionECUtoVT 2-2;
SG_MUL_VAL_ 2498232062 ButtonActivationResponseTAN VTFunctionECUtoVT 1-1;
SG_MUL_VAL_ 2498232062 WSVehicleSystemInstance VTFunctionECUtoVT 144-144;
SG_MUL_VAL_ 2498232062 WSVehicleSystem5 WSIndustryGroup 5-5;
SG_MUL_VAL_ 2498232062 WSVehicleSystem4 WSIndustryGroup 4-4;
SG_MUL_VAL_ 2498232062 WSVehicleSystem3 WSIndustryGroup 3-3;
SG_MUL_VAL_ 2498232062 WSVehicleSystem2 WSIndustryGroup 2-2;
SG_MUL_VAL_ 2498232062 WSVehicleSystem1 WSIndustryGroup 1-1;
SG_MUL_VAL_ 2498232062 WSVehicleSystem WSIndustryGroup 0-0;
SG_MUL_VAL_ 2498232062 WSManufacturerCode VTFunctionECUtoVT 144-144;
SG_MUL_VAL_ 2498232062 WSIndustryGroup VTFunctionECUtoVT 144-144;
SG_MUL_VAL_ 2498232062 WSIdentityNumber VTFunctionECUtoVT 144-144;
SG_MUL_VAL_ 2498232062 WSFunctionInstance VTFunctionECUtoVT 144-144;
SG_MUL_VAL_ 2498232062 WSFunction VTFunctionECUtoVT 144-144;
SG_MUL_VAL_ 2498232062 WSECUInstance VTFunctionECUtoVT 144-144;
SG_MUL_VAL_ 2498232062 WSArbitraryAddressCapable VTFunctionECUtoVT 144-144;
SG_MUL_VAL_ 2498232062 PathRequested VTFunctionECUtoVT 198-198;
SG_MUL_VAL_ 2498232062 ItemRequested VTFunctionECUtoVT 198-198;
SG_MUL_VAL_ 2498232062 Status_3 VTFunctionECUtoVT 35-35;
SG_MUL_VAL_ 2498232062 UnsupportedVtFunction VTFunctionECUtoVT 253-253;
SG_MUL_VAL_ 2498232062 AuxiliaryInputID_1 VTFunctionECUtoVT 34-34;
SG_MUL_VAL_ 2498232062 AuxiliaryFunctionID_1 VTFunctionECUtoVT 34-34;
SG_MUL_VAL_ 2498232062 NumOfPreferredFunctions VTFunctionECUtoVT 34-34;
SG_MUL_VAL_ 2498232062 ModelIdentificationCode VTFunctionECUtoVT 34-34;
SG_MUL_VAL_ 2498232062 ArbitraryAddressCapable VTFunctionECUtoVT 34-34;
SG_MUL_VAL_ 2498232062 IndustryGroup VTFunctionECUtoVT 34-34;
SG_MUL_VAL_ 2498232062 VehicleSystemInstance VTFunctionECUtoVT 34-34;
SG_MUL_VAL_ 2498232062 VehicleSystem2 VTFunctionECUtoVT 34-34;
SG_MUL_VAL_ 2498232062 ZoomValue_PanZoom SubCommandID 16-16;
SG_MUL_VAL_ 2498232062 OperatingState2 VTFunctionECUtoVT 38-38;
SG_MUL_VAL_ 2498232062 Function VTFunctionECUtoVT 34-34;
SG_MUL_VAL_ 2498232062 OperatingState1 VTFunctionECUtoVT 38-38;
SG_MUL_VAL_ 2498232062 YPosChangeTopLeftLong VTFunctionECUtoVT 180-180;
SG_MUL_VAL_ 2498232062 LineDirection VTFunctionECUtoVT 169-169;
SG_MUL_VAL_ 2498232062 FunctionInstance VTFunctionECUtoVT 34-34;
SG_MUL_VAL_ 2498232062 ECUInstance VTFunctionECUtoVT 34-34;
SG_MUL_VAL_ 2498232062 NewValueY VTFunctionECUtoVT 182-182;
SG_MUL_VAL_ 2498232062 GraphicRepresentationObjectID VTFunctionECUtoVT 181-181;
SG_MUL_VAL_ 2498232062 FontStyle VTFunctionECUtoVT 170-170;
SG_MUL_VAL_ 2498232062 YPosChangeTopLeft VTFunctionECUtoVT 165-165;
SG_MUL_VAL_ 2498232062 OffTimeDuration_Audio VTFunctionECUtoVT 163-163;
SG_MUL_VAL_ 2498232062 ButtonKeyCode VTFunctionECUtoVT 1-1;
SG_MUL_VAL_ 2498232062 SoftKeyCode VTFunctionECUtoVT 0-0;
SG_MUL_VAL_ 2498232062 Status_2 VTFunctionECUtoVT 9-9;
SG_MUL_VAL_ 2498232062 NewViewportHeight SubCommandID 17-17;
SG_MUL_VAL_ 2498232062 ViewportY_PanZoom SubCommandID 16-16;
SG_MUL_VAL_ 2498232062 ViewportY SubCommandID 14-14;
SG_MUL_VAL_ 2498232062 EllipseHeight SubCommandID 11-11;
SG_MUL_VAL_ 2498232062 RectangleHeight_Draw SubCommandID 10-10;
SG_MUL_VAL_ 2498232062 EndPixelOffsetY SubCommandID 9-9;
SG_MUL_VAL_ 2498232062 PixelOffsetY SubCommandID 8-8;
SG_MUL_VAL_ 2498232062 CursorOffsetY SubCommandID 1-1;
SG_MUL_VAL_ 2498232062 CursorPosY SubCommandID 0-0;
SG_MUL_VAL_ 2498232062 NewStringValue VTFunctionECUtoVT 179-179;
SG_MUL_VAL_ 2498232062 Value2 VTFunctionECUtoVT 38-38;
SG_MUL_VAL_ 2498232062 NewHeigthAttribute VTFunctionECUtoVT 183-183;
SG_MUL_VAL_ 2498232062 FontType VTFunctionECUtoVT 170-170;
SG_MUL_VAL_ 2498232062 XPosChangeTopLeftLong VTFunctionECUtoVT 180-180;
SG_MUL_VAL_ 2498232062 FillPatternObjectID VTFunctionECUtoVT 172-172;
SG_MUL_VAL_ 2498232062 LineArt VTFunctionECUtoVT 171-171;
SG_MUL_VAL_ 2498232062 LabelFontType VTFunctionECUtoVT 181-181;
SG_MUL_VAL_ 2498232062 Height VTFunctionECUtoVT 169-169;
SG_MUL_VAL_ 2498232062 NewHeight VTFunctionECUtoVT 166-166;
SG_MUL_VAL_ 2498232062 XPosChangeTopLeft VTFunctionECUtoVT 165-165;
SG_MUL_VAL_ 2498232062 TouchState VTFunctionECUtoVT 2-2;
SG_MUL_VAL_ 2498232062 TextLength SubCommandID 13-13;
SG_MUL_VAL_ 2498232062 ManufacturerCode VTFunctionECUtoVT 34-34;
SG_MUL_VAL_ 2498232062 AuxErrorAnyOther VTFunctionECUtoVT 37-37;
SG_MUL_VAL_ 2498232062 CursorPosX SubCommandID 0-0;
SG_MUL_VAL_ 2498232062 CursorOffsetX SubCommandID 1-1;
SG_MUL_VAL_ 2498232062 ForegroundColour SubCommandID 2-2;
SG_MUL_VAL_ 2498232062 BackgroundColour SubCommandID 3-3;
SG_MUL_VAL_ 2498232062 LineAttributesObjectID SubCommandID 4-4;
SG_MUL_VAL_ 2498232062 FillAttributesObjectID SubCommandID 5-5;
SG_MUL_VAL_ 2498232062 FontAttributesObjectID SubCommandID 6-6;
SG_MUL_VAL_ 2498232062 RectangleWidth_Erase SubCommandID 7-7;
SG_MUL_VAL_ 2498232062 RectangleHeight_Erase SubCommandID 7-7;
SG_MUL_VAL_ 2498232062 PixelOffsetX SubCommandID 8-8;
SG_MUL_VAL_ 2498232062 EndPixelOffsetX SubCommandID 9-9;
SG_MUL_VAL_ 2498232062 RectangleWidth_Draw SubCommandID 10-10;
SG_MUL_VAL_ 2498232062 EllipseWidth SubCommandID 11-11;
SG_MUL_VAL_ 2498232062 NumberOfPoints SubCommandID 12-12;
SG_MUL_VAL_ 2498232062 TextOption SubCommandID 13-13;
SG_MUL_VAL_ 2498232062 ViewportX SubCommandID 14-14;
SG_MUL_VAL_ 2498232062 ZoomValue SubCommandID 15-15;
SG_MUL_VAL_ 2498232062 ViewportX_PanZoom SubCommandID 16-16;
SG_MUL_VAL_ 2498232062 NewViewportWidth SubCommandID 17-17;
SG_MUL_VAL_ 2498232062 ObjectID SubCommandID 18-18;
SG_MUL_VAL_ 2498232062 PictureGraphicsID_Canvas SubCommandID 19-19;
SG_MUL_VAL_ 2498232062 PictureGraphicsID_Viewport SubCommandID 20-20;
SG_MUL_VAL_ 2498232062 LastWideChar VTFunctionECUtoVT 193-193;
SG_MUL_VAL_ 2498232062 LockTimeout VTFunctionECUtoVT 189-189;
SG_MUL_VAL_ 2498232062 NewValueX VTFunctionECUtoVT 182-182;
SG_MUL_VAL_ 2498232062 NewObjectID VTFunctionECUtoVT 177-177;
SG_MUL_VAL_ 2498232062 NewAttributeValue VTFunctionECUtoVT 175-175;
SG_MUL_VAL_ 2498232062 NewSoftKeyMaskObjectID VTFunctionECUtoVT 174-174;
SG_MUL_VAL_ 2498232062 FillColour VTFunctionECUtoVT 172-172;
SG_MUL_VAL_ 2498232062 LineWidth VTFunctionECUtoVT 171-171;
SG_MUL_VAL_ 2498232062 FontSize VTFunctionECUtoVT 170-170;
SG_MUL_VAL_ 2498232062 NewValue VTFunctionECUtoVT 168-168;
SG_MUL_VAL_ 2498232062 OnTimeDuration_Audio VTFunctionECUtoVT 163-163;
SG_MUL_VAL_ 2498232062 AuxErrorInvalidInputID VTFunctionECUtoVT 37-37;
SG_MUL_VAL_ 2498232062 VTChangeNumericValueValue VTFunctionECUtoVT 5-5;
SG_MUL_VAL_ 2498232062 ButtonObjectParentID VTFunctionECUtoVT 1-1;
SG_MUL_VAL_ 2498232062 KeyObjectParentID VTFunctionECUtoVT 0-0;
SG_MUL_VAL_ 2498232062 ObjectId_2 VTFunctionECUtoVT 9-9;
SG_MUL_VAL_ 2498232062 Value1 VTFunctionECUtoVT 38-38;
SG_MUL_VAL_ 2498232062 AttributeIDToChange VTFunctionECUtoVT 175-175;
SG_MUL_VAL_ 2498232062 SubCommandID VTFunctionECUtoVT 184-184;
SG_MUL_VAL_ 2498232062 NewWidthAttribute VTFunctionECUtoVT 183-183;
SG_MUL_VAL_ 2498232062 IndexOfThePointToReplace VTFunctionECUtoVT 182-182;
SG_MUL_VAL_ 2498232062 StringVariableObjectID VTFunctionECUtoVT 181-181;
SG_MUL_VAL_ 2498232062 ChangeChildLocationObjectID VTFunctionECUtoVT 165-165;
SG_MUL_VAL_ 2498232062 ListIndex VTFunctionECUtoVT 177-177;
SG_MUL_VAL_ 2498232062 NewPriority VTFunctionECUtoVT 176-176;
SG_MUL_VAL_ 2498232062 AttributeID VTFunctionECUtoVT 185-185;
SG_MUL_VAL_ 2498232062 NewActiveMaskObjectID VTFunctionECUtoVT 173-173;
SG_MUL_VAL_ 2498232062 FillType VTFunctionECUtoVT 172-172;
SG_MUL_VAL_ 2498232062 LineColour VTFunctionECUtoVT 171-171;
SG_MUL_VAL_ 2498232062 FontColour VTFunctionECUtoVT 170-170;
SG_MUL_VAL_ 2498232062 Width VTFunctionECUtoVT 169-169;
SG_MUL_VAL_ 2498232062 NewBackgroundColour VTFunctionECUtoVT 167-167;
SG_MUL_VAL_ 2498232062 NewWidth VTFunctionECUtoVT 166-166;
SG_MUL_VAL_ 2498232062 ChangeChildPositionObjectID VTFunctionECUtoVT 180-180;
SG_MUL_VAL_ 2498232062 SetFocusOpenForEditing VTFunctionECUtoVT 162-162;
SG_MUL_VAL_ 2498232062 EnableOrDisable VTFunctionECUtoVT 161-161;
SG_MUL_VAL_ 2498232062 ShowOrHide VTFunctionECUtoVT 160-160;
SG_MUL_VAL_ 2498232062 AuxInputEnable VTFunctionECUtoVT 37-37;
SG_MUL_VAL_ 2498232062 AssignmentErrorNotAccepted VTFunctionECUtoVT 36-36;
SG_MUL_VAL_ 2498232062 ObjectOfChangedStringValueID VTFunctionECUtoVT 8-8;
SG_MUL_VAL_ 2498232062 VTChangeSoftKeyMaskObjectID VTFunctionECUtoVT 7-7;
SG_MUL_VAL_ 2498232062 VTSelectInputObjectStatus VTFunctionECUtoVT 3-3;
SG_MUL_VAL_ 2498232062 YPosition VTFunctionECUtoVT 2-2;
SG_MUL_VAL_ 2498232062 AuxiliaryFunctionID VTFunctionECUtoVT 32-32;
SG_MUL_VAL_ 2498232062 Status_1 VTFunctionECUtoVT 9-9;
SG_MUL_VAL_ 2498232062 IdentityNumber VTFunctionECUtoVT 34-34;
SG_MUL_VAL_ 2498232062 FirstWideChar VTFunctionECUtoVT 193-193;
SG_MUL_VAL_ 2498232062 MemoryRequired VTFunctionECUtoVT 192-192;
SG_MUL_VAL_ 2498232062 ObjectIDOfDataMaskToLock VTFunctionECUtoVT 189-189;
SG_MUL_VAL_ 2498232062 DataOrAlarmMaskObjectID VTFunctionECUtoVT 174-174;
SG_MUL_VAL_ 2498232062 Frequency_Audio VTFunctionECUtoVT 163-163;
SG_MUL_VAL_ 2498232062 ButtonObjectID VTFunctionECUtoVT 1-1;
SG_MUL_VAL_ 2498232062 KeyObjectID VTFunctionECUtoVT 0-0;
SG_MUL_VAL_ 2498232062 WSMaintenanceVersion VTFunctionECUtoVT 255-255;
SG_MUL_VAL_ 2498232062 AuxiliaryInputNumber VTFunctionECUtoVT 32-32;
SG_MUL_VAL_ 2498232062 ExtendedVersionLabelToDelete VTFunctionECUtoVT 214-214;
SG_MUL_VAL_ 2498232062 ExtendedVersionLabelToLoad VTFunctionECUtoVT 213-213;
SG_MUL_VAL_ 2498232062 ExtendedVersionLabelToStore VTFunctionECUtoVT 212-212;
SG_MUL_VAL_ 2498232062 MacroObjectID_2 VTFunctionECUtoVT 188-188;
SG_MUL_VAL_ 2498232062 AuxCapabilitiesRequestType VTFunctionECUtoVT 39-39;
SG_MUL_VAL_ 2498232062 WSMaintenanceInitiating WSMaintenanceVersion 3-254;
SG_MUL_VAL_ 2498232062 VersionLabelToDelete VTFunctionECUtoVT 210-210;
SG_MUL_VAL_ 2498232062 VersionLabelToLoad VTFunctionECUtoVT 209-209;
SG_MUL_VAL_ 2498232062 VersionLabelToStore VTFunctionECUtoVT 208-208;
SG_MUL_VAL_ 2498232062 CodePlane VTFunctionECUtoVT 193-193;
SG_MUL_VAL_ 2498232062 MacroObjectID VTFunctionECUtoVT 190-190;
SG_MUL_VAL_ 2498232062 LockUnlockCommand VTFunctionECUtoVT 189-189;
SG_MUL_VAL_ 2498232062 ColourMapObjectID VTFunctionECUtoVT 186-186;
SG_MUL_VAL_ 2498232062 ObjectToGetAttributeID VTFunctionECUtoVT 185-185;
SG_MUL_VAL_ 2498232062 GraphicsContextObjectID VTFunctionECUtoVT 184-184;
SG_MUL_VAL_ 2498232062 PolygonObjectToScaleID VTFunctionECUtoVT 183-183;
SG_MUL_VAL_ 2498232062 PolygonObjectToChangeID VTFunctionECUtoVT 182-182;
SG_MUL_VAL_ 2498232062 ObjectToAssociateLabelWithID VTFunctionECUtoVT 181-181;
SG_MUL_VAL_ 2498232062 ObjectToChangeStringValueID VTFunctionECUtoVT 179-179;
SG_MUL_VAL_ 2498232062 ListInputObjectID VTFunctionECUtoVT 177-177;
SG_MUL_VAL_ 2498232062 AlarmMaskObjectID VTFunctionECUtoVT 176-176;
SG_MUL_VAL_ 2498232062 ObjectToChangeAttributeID VTFunctionECUtoVT 175-175;
SG_MUL_VAL_ 2498232062 MaskType VTFunctionECUtoVT 174-174;
SG_MUL_VAL_ 2498232062 WorkingSetObjectID VTFunctionECUtoVT 173-173;
SG_MUL_VAL_ 2498232062 ObjectToChangeFillAttributesID VTFunctionECUtoVT 172-172;
SG_MUL_VAL_ 2498232062 ObjectToChangeLineAttributesID VTFunctionECUtoVT 171-171;
SG_MUL_VAL_ 2498232062 ObjectToChangeFontID VTFunctionECUtoVT 170-170;
SG_MUL_VAL_ 2498232062 ObjectToChangeEndPointID VTFunctionECUtoVT 169-169;
SG_MUL_VAL_ 2498232062 ObjectToChangeNumValueID VTFunctionECUtoVT 168-168;
SG_MUL_VAL_ 2498232062 ObjectToChangeColourID VTFunctionECUtoVT 167-167;
SG_MUL_VAL_ 2498232062 ObjectToSizeID VTFunctionECUtoVT 166-166;
SG_MUL_VAL_ 2498232062 ChangeChildLocationParentOb_0003 VTFunctionECUtoVT 165-165;
SG_MUL_VAL_ 2498232062 AudioVolume VTFunctionECUtoVT 164-164;
SG_MUL_VAL_ 2498232062 NumberOfRepetitions_Audio VTFunctionECUtoVT 163-163;
SG_MUL_VAL_ 2498232062 SelectInputObjectID VTFunctionECUtoVT 162-162;
SG_MUL_VAL_ 2498232062 ObjectoEnableDisbaleID VTFunctionECUtoVT 161-161;
SG_MUL_VAL_ 2498232062 ObjectToShowHideID VTFunctionECUtoVT 160-160;
SG_MUL_VAL_ 2498232062 InputStatusObjectId VTFunctionECUtoVT 37-37;
SG_MUL_VAL_ 2498232062 AuxModelIdentification VTFunctionECUtoVT 35-35;
SG_MUL_VAL_ 2498232062 NumberOfInpuUnits VTFunctionECUtoVT 34-34;
SG_MUL_VAL_ 2498232062 AuxiliaryFunctionObjectID VTFunctionECUtoVT 36-36;
SG_MUL_VAL_ 2498232062 ObjectPoolRecord VTFunctionECUtoVT 17-17;
SG_MUL_VAL_ 2498232062 ChangeChildPositionParentOb_0003 VTFunctionECUtoVT 180-180;
SG_MUL_VAL_ 2498232062 VTChangeSoftKeyMaskParentID VTFunctionECUtoVT 7-7;
SG_MUL_VAL_ 2498232062 VTChangeActiveMaskObjectID VTFunctionECUtoVT 6-6;
SG_MUL_VAL_ 2498232062 VTChangeNumericValueObjectID VTFunctionECUtoVT 5-5;
SG_MUL_VAL_ 2498232062 VTEscObjectID VTFunctionECUtoVT 4-4;
SG_MUL_VAL_ 2498232062 VTSelectInputObjectID VTFunctionECUtoVT 3-3;
SG_MUL_VAL_ 2498232062 XPosition VTFunctionECUtoVT 2-2;
SG_MUL_VAL_ 2498232062 ButtonActivationCode VTFunctionECUtoVT 1-1;
SG_MUL_VAL_ 2498232062 KeyActivationCode VTFunctionECUtoVT 0-0;
SG_MUL_VAL_ 2498232062 InputObjectId VTFunctionECUtoVT 38-38;
SG_MUL_VAL_ 2498232062 SourceAddressOfAuxiliaryInputDev VTFunctionECUtoVT 32-32;
SG_MUL_VAL_ 2498232062 ObjectId_1 VTFunctionECUtoVT 9-9;
